VERSION ""

NS_ :

BS_:

BU_: ICC DVR PCL EAMP FLZCU_HCU_IC FLZCU_IC HCU_IC FLZCU_Signal_IC CGW TBOX BNCM CWC FRZCU

BO_ 1096 TMS_11: 32 CGW
 SG_ TMS_AirPurgeReminderSts : 17|2@0+ (1,0) [0|3] ""  ICC
 SG_ TMS_BT_Reduce_Wind_SpeedSts : 23|2@0+ (1,0) [0|3] "Bit"  ICC
 SG_ TMS_First_BlowingSts : 21|2@0+ (1,0) [0|3] "Bit"  ICC
 SG_ TMS_CirculationInTunnelsSts : 19|2@0+ (1,0) [0|3] "Bit"  ICC
 SG_ TMS_crosscountry_coolingSts : 29|2@0+ (1,0) [0|3] "Bit"  ICC
 SG_ TMS_ParkingAirConditioningStatus : 27|2@0+ (1,0) [0|3] "Bit"  ICC
 SG_ TMS_CoolantFillSts : 25|2@0+ (1,0) [0|3] "Bit"  ICC
 SG_ TMS_UVC_ControlSts : 39|2@0+ (1,0) [0|3] "Bit"  ICC
 SG_ TMS_AutoDefogActiveSts : 37|1@0+ (1,0) [0|1] ""  ICC
 SG_ TMS_UVC_LuminanceSts : 36|3@0+ (1,0) [0|7] "Bit"  ICC
 SG_ TMS_ICC_Lightoff_Sts : 33|2@0+ (1,0) [0|3] ""  ICC
 SG_ TMS_ICC_Memoff_Sts : 47|2@0+ (1,0) [0|3] ""  ICC
 SG_ TMS_keepwarmSet_TemperatureSts : 55|8@0+ (1,0) [0|254] "Bit"  ICC
 SG_ TMS_CFSCycleLevel : 71|3@0+ (1,0) [0|7] ""  ICC
 SG_ TMS_TimingLevel : 68|3@0+ (1,0) [0|7] ""  ICC
 SG_ TMS_BiochemicalFuncSts : 95|2@0+ (1,0) [0|3] ""  ICC
 SG_ TMS_TimedVentilationSts : 97|2@0+ (1,0) [0|3] ""  ICC

BO_ 1240 TDU_9: 32 CGW
 SG_ TMS_CFSSwitchFb : 17|2@0+ (1,0) [0|3] ""  ICC
 SG_ TDU_CFSPosOneType : 21|4@0+ (1,0) [0|15] ""  ICC
 SG_ TDU_CFSPosTwoType : 27|4@0+ (1,0) [0|15] ""  ICC
 SG_ TDU_CFSPosThreeType : 31|4@0+ (1,0) [0|15] ""  ICC
 SG_ TDU_CFSRunOut : 39|4@0+ (1,0) [0|15] ""  ICC
 SG_ TMS_CFSShortWarn : 43|4@0+ (1,0) [0|15] ""  ICC
 SG_ TMS_CFSLevelSetFb : 47|4@0+ (1,0) [0|15] ""  ICC
 SG_ TMS_CFSPosSetFb : 49|2@0+ (1,0) [0|3] ""  ICC
 SG_ TMS_CFSPosOneLife : 63|8@0+ (1,0) [0|100] "%"  ICC
 SG_ TMS_CFSPosTwoLife : 87|8@0+ (1,0) [0|100] "%"  ICC
 SG_ TMS_CFSPosThreeLife : 95|8@0+ (1,0) [0|100] "%"  ICC
 SG_ TMS_PM25SwitchFb : 97|2@0+ (1,0) [0|3] ""  ICC
 SG_ TMS_AQSCOSts_2 : 103|4@0+ (1,0) [0|15] ""  ICC
 SG_ TMS_AQSNO2Sts_2 : 107|4@0+ (1,0) [0|15] ""  ICC
 SG_ TMS_AQSN02SnsrSts_2 : 109|2@0+ (1,0) [0|3] ""  ICC
 SG_ TMS_AQSLifeCntr_2 : 111|2@0+ (1,0) [0|3] ""  ICC
 SG_ TMS_AQSErrSts_2 : 114|3@0+ (1,0) [0|7] ""  ICC
 SG_ TMS_AQSErrRespAQSM_2 : 115|1@0+ (1,0) [0|1] ""  ICC
 SG_ TMS_AQSAirQlySts_2 : 118|3@0+ (1,0) [0|7] ""  ICC
 SG_ TMS_ThrModeStsFb : 122|3@0+ (1,0) [0|6] ""  ICC
 SG_ TMS_ThrSetTempFb_C : 127|5@0+ (0.5,15.5) [15.5|30.5] "℃"  ICC
 SG_ TMS_ThrCLMSwitchFb : 145|2@0+ (1,0) [0|3] ""  ICC
 SG_ TMS_ThrAutoSwitchFb : 147|2@0+ (1,0) [0|3] ""  ICC
 SG_ TMS_ThrBlowSpeedLevelKeyStsFb : 151|4@0+ (1,0) [0|15] ""  ICC

BO_ 638 FRZCU_9: 16 CGW
 SG_ FRZCU_HoodSts : 45|2@0+ (1,0) [0|3] ""  ICC
 SG_ FRZCU_AuthenResult : 48|1@0+ (1,0) [0|1] ""  ICC
 SG_ FRZCU_PowerMode : 51|2@0+ (1,0) [0|3] ""  ICC
 SG_ FRZCU_TrunkSts : 53|2@0+ (1,0) [0|3] ""  ICC
 SG_ FRZCU_HandleSwitchStsFL : 57|2@0+ (1,0) [0|3] ""  ICC,PCL
 SG_ FRZCU_HandleSwitchStsFR : 59|2@0+ (1,0) [0|3] ""  ICC,PCL
 SG_ FRZCU_HandleSwitchStsRR : 61|2@0+ (1,0) [0|3] ""  ICC
 SG_ FRZCU_HandleSwitchStsRL : 63|2@0+ (1,0) [0|3] ""  ICC
 SG_ SeatLength_target_Passenger : 87|4@0+ (1,0) [0|15] ""  ICC
 SG_ SeatBackrest_target_Passenger : 95|5@0+ (1,0) [0|15] ""  ICC
 SG_ FRZCU_TrunkLockSts : 89|2@0+ (1,0) [0|3] ""  ICC
 SG_ FRZCU_HoodLockSts : 103|2@0+ (1,0) [0|3] ""  ICC
 SG_ FrontBackSpeedAdj_Cmd : 101|3@0+ (1,0) [0|7] ""  ICC
 SG_ FRZCU_GloveboxSW : 98|1@0+ (1,0) [0|1] ""  ICC
 SG_ FRZCU_FRReleaseLockSts : 111|3@0+ (1,0) [0|7] ""  ICC
 SG_ FRZCU_RRReleaseLockSts : 108|3@0+ (1,0) [0|7] ""  ICC
 SG_ FRZCU_PELockInKeyWarning : 105|1@0+ (1,0) [0|1] ""  ICC
 SG_ FRZCU_PowerOFFWarning : 118|1@0+ (1,0) [0|1] ""  ICC
 SG_ FRZCU_KeylessWarning : 116|1@0+ (1,0) [0|1] ""  ICC
 SG_ FRZCU_OTAPwrDwnReqFb : 113|2@0+ (1,0) [0|3] ""  ICC
 SG_ FRZCU_OTAPwrOnReqFb : 127|2@0+ (1,0) [0|3] ""  ICC

BO_ 949 PEPS_1: 16 CGW
 SG_ PEPS_InformationSource : 23|2@0+ (1,0) [0|3] ""  ICC,PCL
 SG_ PEPS_OrderInformation : 21|4@0+ (1,0) [0|15] ""  ICC,PCL
 SG_ PEPS_IDInformation : 31|4@0+ (1,0) [0|15] ""  ICC,PCL
 SG_ PEPS_KeySts : 27|3@0+ (1,0) [0|7] ""  ICC,PCL
 SG_ PEPS_ETRUnLockReq : 39|2@0+ (1,0) [0|3] ""  ICC,PCL

BO_ 1028 PEPS_2: 16 CGW
 SG_ PEPS_WelcomeON : 17|2@0+ (1,0) [0|3] ""  ICC,PCL
 SG_ PEPS_VehicleSearchReq : 19|2@0+ (1,0) [0|3] ""  ICC,PCL
 SG_ PEPS_SATOReminder : 21|2@0+ (1,0) [0|3] ""  ICC,PCL
 SG_ PEPS_PLGUnlockReq : 23|2@0+ (1,0) [0|3] ""  ICC,PCL
 SG_ PEPS_RKETrunkSts : 25|2@0+ (1,0) [0|3] ""  ICC,PCL
 SG_ PEPS_SSBInhibitCWCSts : 27|2@0+ (1,0) [0|3] ""  ICC,PCL
 SG_ PEPS_WirelessChargingCtrSts : 29|2@0+ (1,0) [0|3] ""  ICC,PCL
 SG_ PEPS_EmgyShutdown : 35|2@0+ (1,0) [0|3] ""  ICC,PCL
 SG_ PEPS_SSBInputFailure : 37|2@0+ (1,0) [0|3] ""  ICC,PCL
 SG_ PEPS_SmartSystemWarning1_1 : 39|2@0+ (1,0) [0|3] ""  ICC,PCL
 SG_ PEPS_SmartSystemWarning2_2 : 41|2@0+ (1,0) [0|3] ""  ICC,PCL
 SG_ PEPS_SmartSystemWarning3_1 : 43|2@0+ (1,0) [0|3] ""  ICC,PCL
 SG_ PEPS_SmartSystemWarning3_2 : 45|2@0+ (1,0) [0|3] ""  ICC,PCL
 SG_ PEPS_SmartSystemWarning4_2 : 47|2@0+ (1,0) [0|3] ""  ICC,PCL
 SG_ PEPS_SmartSystemWarning4_3 : 49|2@0+ (1,0) [0|3] ""  ICC,PCL
 SG_ PEPS_SystemWarning : 51|2@0+ (1,0) [0|3] ""  ICC,PCL
 SG_ PEPS_BLTKeyPESts : 53|2@0+ (1,0) [0|3] ""  ICC,PCL

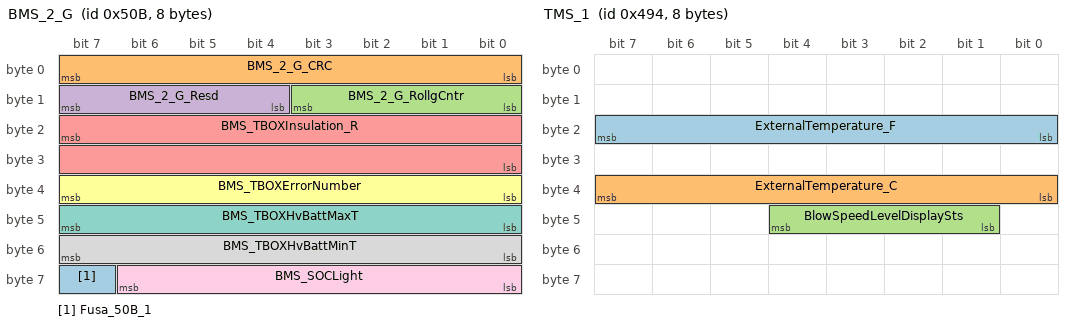
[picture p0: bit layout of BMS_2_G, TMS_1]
BO_ 1291 BMS_2_G: 8 CGW
 SG_ Fusa_50B_1 : 63|1@0+ (1,0) [0|1] ""  ICC
 SG_ BMS_2_G_CRC : 7|8@0+ (1,0) [0|255] ""  ICC
 SG_ BMS_2_G_RollgCntr : 11|4@0+ (1,0) [0|14] ""  ICC
 SG_ BMS_2_G_Resd : 15|4@0+ (1,0) [0|15] ""  ICC
 SG_ BMS_TBOXInsulation_R : 23|16@0+ (1,0) [0|60000] "kiloohm(kΩ)"  ICC
 SG_ BMS_TBOXErrorNumber : 39|8@0+ (1,0) [0|255] ""  ICC
 SG_ BMS_TBOXHvBattMaxT : 47|8@0+ (1,-40) [-40|210] "gradcelsius(°C)"  ICC
 SG_ BMS_TBOXHvBattMinT : 55|8@0+ (1,-40) [-40|210] "gradcelsius(°C)"  ICC
 SG_ BMS_SOCLight : 62|7@0+ (1,0) [0|100] "%"  ICC

BO_ 587 ONEBOX_4: 48 CGW
 SG_ ONEBOX_4_LHFWheelSpeedRPM : 23|16@0+ (0.0625,0) [0|4095.875] "rpm"  ICC
 SG_ ONEBOX_4_RHFWheelSpeedRPM : 39|16@0+ (0.0625,0) [0|4095.875] "rpm"  ICC
 SG_ LHRWheelSpeedRPM : 55|16@0+ (0.0625,0) [0|4095.875] "rpm"  ICC
 SG_ RHRWheelSpeedRPM : 87|16@0+ (0.0625,0) [0|4095.875] "rpm"  ICC
 SG_ LHRPulseCounterFailSts : 106|1@0+ (1,0) [0|1] ""  ICC
 SG_ LHRPulseCounter : 103|13@0+ (1,0) [0|8191] "pulse"  ICC
 SG_ RHRPulseCounterFailSts : 122|1@0+ (1,0) [0|1] ""  ICC
 SG_ RHRPulseCounter : 119|13@0+ (1,0) [0|8191] "pulse"  ICC
 SG_ RHFPulseCounterFailSts : 154|1@0+ (1,0) [0|1] ""  ICC
 SG_ RHFPulseCounter : 151|13@0+ (1,0) [0|8191] "pulse"  ICC
 SG_ LHFPulseCounterFailSts : 170|1@0+ (1,0) [0|1] ""  ICC
 SG_ LHFPulseCounter : 167|13@0+ (1,0) [0|8191] "pulse"  ICC
 SG_ LHFWheelDriveDirection : 187|3@0+ (1,0) [0|7] ""  ICC
 SG_ RHFWheelDriveDirection : 219|3@0+ (1,0) [0|7] ""  ICC
 SG_ LHRWheelDriveDirection : 235|3@0+ (1,0) [0|7] ""  ICC
 SG_ RHRWheelDriveDirection : 251|3@0+ (1,0) [0|7] ""  ICC

BO_ 1338 FMCU_1_G: 8 CGW
 SG_ FMCU_ErrLvlDis : 19|3@0+ (1,0) [0|7] ""  ICC
 SG_ FMCU_SpdAct_EDR : 39|16@0+ (1,-32767) [-32767|32766] "rpm"  ICC

BO_ 777 ISGF_2: 8 CGW
 SG_ ISGF_ErrLvl : 20|4@0+ (1,0) [0|6] ""  ICC

BO_ 1403 RMCU_1_G: 8 CGW
 SG_ RMCU_ErrLvlDis : 19|3@0+ (1,0) [0|7] ""  ICC
 SG_ RMCU_Speed_EDR : 39|16@0+ (1,-32767) [-32767|32766] "rpm"  ICC

BO_ 1299 BMS_1_G: 8 CGW
 SG_ BMS_PackVoltageDis : 23|16@0+ (0.1,0) [0|1000] "volt(V)"  ICC
 SG_ BMS_PackCurrentDis : 39|16@0+ (0.1,-2047) [-2047|2047] "ampere(A)"  ICC

BO_ 1099 ISGF_4: 8 CGW
 SG_ ISGF_SysTempOvrInd : 40|1@0+ (1,0) [0|1] ""  ICC

BO_ 1130 TCU_23: 64 CGW
 SG_ TCU_23_GBFaultstatus : 23|2@0+ (1,0) [0|3] ""  ICC
 SG_ TCU_23_TeachInState : 30|3@0+ (1,0) [0|7] ""  ICC
 SG_ TCU_23_GBWarmUpReq : 27|1@0+ (1,0) [0|1] ""  ICC
 SG_ TCU_23_CluSelfLrng : 39|1@0+ (1,0) [0|1] ""  ICC

BO_ 1180 ACU_1: 8 CGW
 SG_ New_Signal_49C_9 : 32|25@0+ (1,0) [0|1024] ""  ICC
 SG_ New_Signal_49C_8 : 37|4@0+ (1,0) [0|15] ""  ICC
 SG_ New_Signal_49C_7 : 27|1@0+ (1,0) [0|1] ""  ICC
 SG_ New_Signal_49C_6 : 29|1@0+ (1,0) [0|1] ""  ICC
 SG_ New_Signal_49C_5 : 31|1@0+ (1,0) [0|1] ""  ICC
 SG_ New_Signal_49C_4 : 19|2@0+ (1,0) [0|3] ""  ICC
 SG_ New_Signal_49C_3 : 21|1@0+ (1,0) [0|1] ""  ICC
 SG_ New_Signal_49C_2 : 23|1@0+ (1,0) [0|1] ""  ICC
 SG_ New_Signal_49C_1 : 15|4@0+ (1,0) [0|15] ""  ICC
 SG_ ACU_1_RollgCntr1 : 11|4@0+ (1,0) [0|15] ""  ICC
 SG_ ACU_1_CRC1 : 7|8@0+ (1,0) [0|255] ""  ICC
 SG_ ABM_1_Rollover_Status : 33|1@0+ (1,0) [0|1] ""  ICC
 SG_ ACU_1_AirBagFailSts : 17|2@0+ (1,0) [0|3] ""  ICC
 SG_ ACU_1_ThdRowLBeltWarning : 20|1@0+ (1,0) [0|1] ""  ICC
 SG_ ACU_1_ThdRowRBeltWarning : 22|1@0+ (1,0) [0|1] ""  ICC
 SG_ ACU_1_PsngrSeatBeltWarning : 25|2@0+ (1,0) [0|3] ""  ICC
 SG_ ACU_1_SecRowLBeltWarning : 26|1@0+ (1,0) [0|1] ""  ICC
 SG_ ACU_1_SecRowMBeltWarning : 28|1@0+ (1,0) [0|1] ""  ICC
 SG_ ACU_1_SecRowRBeltWarning : 30|1@0+ (1,0) [0|1] ""  ICC
 SG_ ACU_1_PsngrSeatOccupiedSts : 39|2@0+ (1,0) [0|3] ""  ICC

BO_ 1248 FRZCU_TO_FLZCU: 48 CGW

BO_ 1341 BMS_44: 48 CGW
 SG_ BMS_44_PackPowerRealTime : 23|15@0+ (0.1,-1024) [-1024|1024] "kW"  ICC

BO_ 811 BMS_6: 16 CGW
 SG_ BMS_Chg_Sts : 87|4@0+ (1,0) [0|15] ""  ICC

BO_ 1427 ILCF_1: 8 CGW
 SG_ ILCF_1_LogoParkingSts : 17|2@0+ (1,0) [0|3] ""  ICC

BO_ 1172 TMS_1: 8 CGW
 SG_ ExternalTemperature_F : 23|8@0+ (1,-67) [-67|158] "°F"  ICC
 SG_ ExternalTemperature_C : 39|8@0+ (0.5,-40) [-40|85] "°C"  ICC
 SG_ BlowSpeedLevelDisplaySts : 44|4@0+ (1,0) [0|15] ""  ICC,EAMP

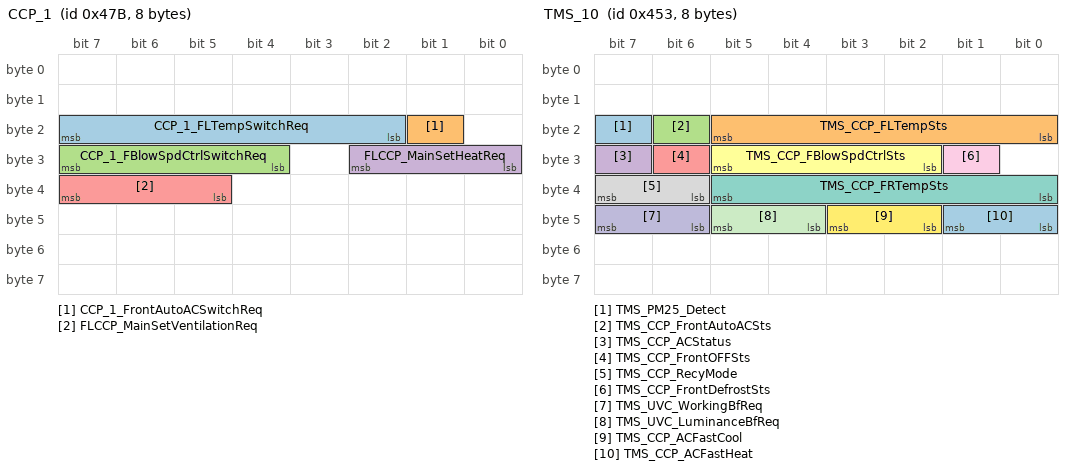
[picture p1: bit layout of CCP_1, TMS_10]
BO_ 1147 CCP_1: 8 CGW
 SG_ CCP_1_FLTempSwitchReq : 23|6@0+ (0.5,15.5) [15.5|30.5] "℃"  ICC
 SG_ CCP_1_FrontAutoACSwitchReq : 17|1@0+ (1,0) [0|1] ""  ICC
 SG_ CCP_1_FBlowSpdCtrlSwitchReq : 31|4@0+ (1,0) [0|15] ""  ICC
 SG_ FLCCP_MainSetHeatReq : 26|3@0+ (1,0) [0|7] ""  ICC
 SG_ FLCCP_MainSetVentilationReq : 39|3@0+ (1,0) [0|7] ""  ICC

BO_ 1107 TMS_10: 8 CGW
 SG_ TMS_PM25_Detect : 23|1@0+ (1,0) [0|1] ""  ICC
 SG_ TMS_CCP_FLTempSts : 21|6@0+ (0.5,15.5) [15.5|30.5] "℃"  ICC
 SG_ TMS_CCP_FrontAutoACSts : 22|1@0+ (1,0) [0|1] ""  ICC
 SG_ TMS_CCP_ACStatus : 31|1@0+ (1,0) [0|1] ""  ICC
 SG_ TMS_CCP_FrontOFFSts : 30|1@0+ (1,0) [0|1] ""  ICC
 SG_ TMS_CCP_FBlowSpdCtrlSts : 29|4@0+ (1,0) [0|15] ""  ICC
 SG_ TMS_CCP_FRTempSts : 37|6@0+ (0.5,15.5) [15.5|30.5] "℃"  ICC
 SG_ TMS_CCP_RecyMode : 39|2@0+ (1,0) [0|3] ""  ICC
 SG_ TMS_CCP_FrontDefrostSts : 25|1@0+ (1,0) [0|1] ""  ICC
 SG_ TMS_UVC_WorkingBfReq : 47|2@0+ (1,0) [0|3] ""  ICC
 SG_ TMS_UVC_LuminanceBfReq : 45|2@0+ (1,0) [0|3] ""  ICC
 SG_ TMS_CCP_ACFastCool : 43|2@0+ (1,0) [0|3] ""  ICC
 SG_ TMS_CCP_ACFastHeat : 41|2@0+ (1,0) [0|3] ""  ICC

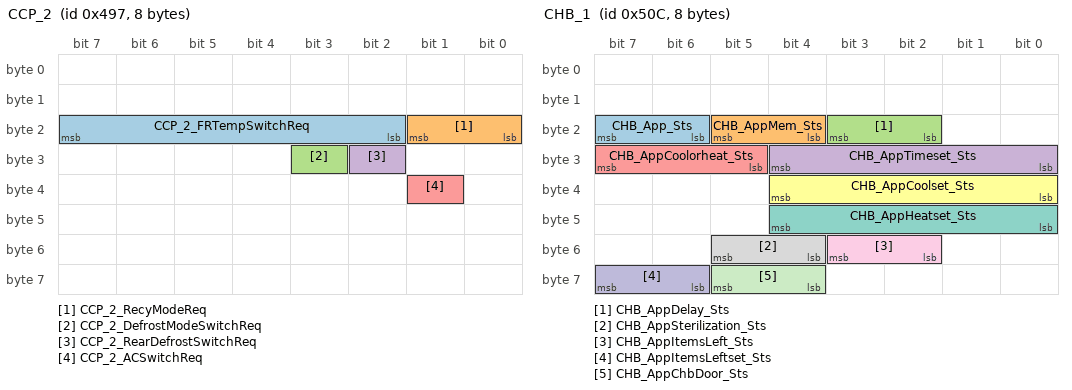
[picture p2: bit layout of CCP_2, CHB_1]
BO_ 1175 CCP_2: 8 CGW
 SG_ CCP_2_FRTempSwitchReq : 23|6@0+ (0.5,15.5) [15.5|30.5] "℃"  ICC
 SG_ CCP_2_RecyModeReq : 17|2@0+ (1,0) [0|3] ""  ICC
 SG_ CCP_2_DefrostModeSwitchReq : 27|1@0+ (1,0) [0|1] ""  ICC
 SG_ CCP_2_RearDefrostSwitchReq : 26|1@0+ (1,0) [0|1] ""  ICC
 SG_ CCP_2_ACSwitchReq : 33|1@0+ (1,0) [0|1] ""  ICC

BO_ 1292 CHB_1: 8 CGW
 SG_ CHB_App_Sts : 23|2@0+ (1,0) [0|3] ""  ICC
 SG_ CHB_AppMem_Sts : 21|2@0+ (1,0) [0|3] ""  ICC
 SG_ CHB_AppDelay_Sts : 19|2@0+ (1,0) [0|3] ""  ICC
 SG_ CHB_AppTimeset_Sts : 28|5@0+ (1,0) [0|31] "h"  ICC
 SG_ CHB_AppCoolorheat_Sts : 31|3@0+ (1,0) [0|7] ""  ICC
 SG_ CHB_AppCoolset_Sts : 36|5@0+ (1,0) [0|31] ""  ICC
 SG_ CHB_AppHeatset_Sts : 44|5@0+ (1,0) [0|31] ""  ICC
 SG_ CHB_AppSterilization_Sts : 53|2@0+ (1,0) [0|3] ""  ICC
 SG_ CHB_AppItemsLeft_Sts : 51|2@0+ (1,0) [0|3] ""  ICC
 SG_ CHB_AppItemsLeftset_Sts : 63|2@0+ (1,0) [0|3] ""  ICC
 SG_ CHB_AppChbDoor_Sts : 61|2@0+ (1,0) [0|3] ""  ICC

BO_ 1241 EMS_4_G: 8 CGW
 SG_ FuelTankLidSystemFailureSts : 43|1@0+ (1,0) [0|1] ""  ICC
 SG_ FuelTankPressureConditionReached : 45|2@0+ (1,0) [0|3] ""  ICC

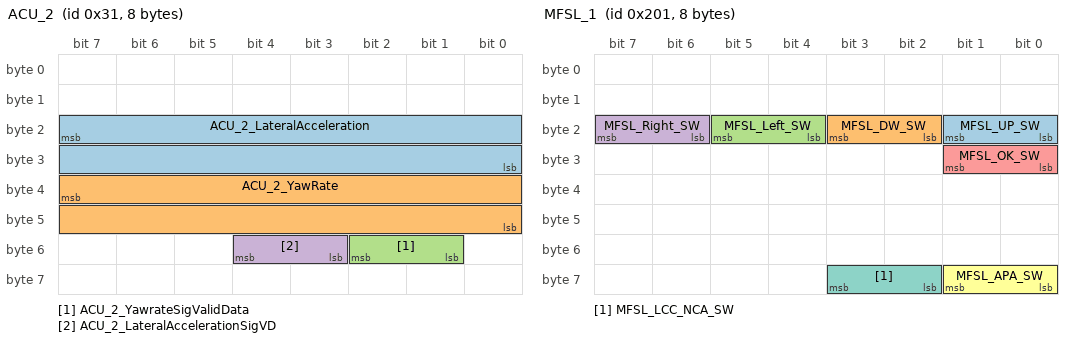
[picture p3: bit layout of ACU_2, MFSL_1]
BO_ 49 ACU_2: 8 CGW
 SG_ ACU_2_LateralAcceleration : 23|16@0+ (0.001,-2) [-2|2] "g"  ICC
 SG_ ACU_2_YawRate : 39|16@0+ (0.01,-180) [-180|180] "deg/sec"  ICC
 SG_ ACU_2_YawrateSigValidData : 50|2@0+ (1,0) [0|3] ""  ICC
 SG_ ACU_2_LateralAccelerationSigVD : 52|2@0+ (1,0) [0|3] ""  ICC

BO_ 1024 FRZCU_13: 64 CGW
 SG_ FRZCU_ADSLightSts : 49|2@0+ (1,0) [0|3] ""  ICC
 SG_ CSunshadeSts : 23|3@0+ (1,0) [0|7] ""  ICC
 SG_ CSunshadePercentSts : 20|4@0+ (1,0) [0|15] ""  ICC
 SG_ FRZCU_SeatHeatLvlFR2 : 31|4@0+ (1,0) [0|15] ""  ICC
 SG_ FRZCU_SeatVentLvlFR2 : 27|4@0+ (1,0) [0|15] ""  ICC
 SG_ FRZCU_SeatVentLvlRR2 : 39|4@0+ (1,0) [0|15] ""  ICC
 SG_ FRZCU_SeatHeatLvlRR2 : 35|4@0+ (1,0) [0|15] ""  ICC
 SG_ FRZCU_ContainerlightSts : 47|2@0+ (1,0) [0|3] ""  ICC
 SG_ FRZCU_FRWinThermalSts : 45|1@0+ (1,0) [0|1] ""  ICC
 SG_ FRZCU_RRWinThermalSts : 44|1@0+ (1,0) [0|1] ""  ICC
 SG_ FRZCU_CSunshadeThermalSts : 43|1@0+ (1,0) [0|1] ""  ICC

BO_ 1182 CDU_OBC_3: 48 CGW
 SG_ OBC_InnerDischgVolt : 348|13@0+ (0.1,0) [0|800] ""  ICC
 SG_ OBC_InnerDischgCurr : 343|10@0+ (0.1,0) [0|100] ""  ICC
 SG_ OBC_ElectronicLockSts : 242|3@0+ (1,0) [0|4] ""  ICC
 SG_ OBC_WorkingMode : 251|4@0+ (1,0) [0|15] ""  ICC
 SG_ OBC_OutDischgCurr : 367|10@0+ (0.1,0) [0|100] "A"  ICC
 SG_ OBC_OutDischgVolt : 372|13@0+ (0.1,0) [0|800] "V"  ICC

BO_ 513 MFSL_1: 8 CGW
 SG_ MFSL_UP_SW : 17|2@0+ (1,0) [0|3] ""  ICC
 SG_ MFSL_DW_SW : 19|2@0+ (1,0) [0|3] ""  ICC
 SG_ MFSL_Left_SW : 21|2@0+ (1,0) [0|3] ""  ICC
 SG_ MFSL_Right_SW : 23|2@0+ (1,0) [0|3] ""  ICC
 SG_ MFSL_OK_SW : 25|2@0+ (1,0) [0|3] ""  ICC
 SG_ MFSL_APA_SW : 57|2@0+ (1,0) [0|3] ""  ICC
 SG_ MFSL_LCC_NCA_SW : 59|2@0+ (1,0) [0|3] ""  ICC

BO_ 1152 TBOX_8: 16 CGW
 SG_ TBOX_PetmodeSetTemperature : 118|5@0+ (0.5,15.5) [15.5|30.5] "℃"  ICC

BO_ 1164 CDU_5: 64 CGW
 SG_ OBC_DischgSts : 123|3@0+ (1,0) [0|3] ""  ICC

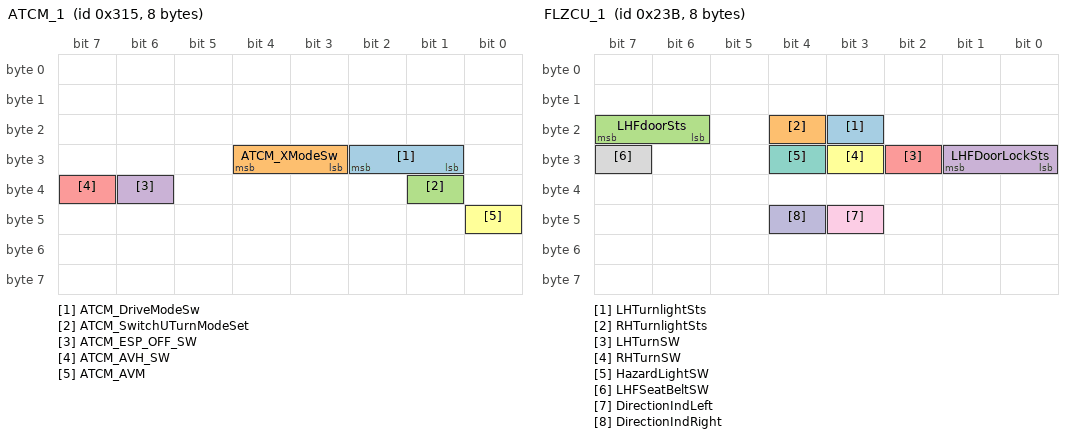
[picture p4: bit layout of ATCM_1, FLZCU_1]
BO_ 789 ATCM_1: 8 CGW
 SG_ ATCM_DriveModeSw : 26|2@0+ (1,0) [0|3] ""  ICC
 SG_ ATCM_XModeSw : 28|2@0+ (1,0) [0|3] ""  ICC
 SG_ ATCM_SwitchUTurnModeSet : 33|1@0+ (1,0) [0|1] ""  ICC
 SG_ ATCM_ESP_OFF_SW : 38|1@0+ (1,0) [0|1] ""  ICC
 SG_ ATCM_AVH_SW : 39|1@0+ (1,0) [0|1] ""  ICC
 SG_ ATCM_AVM : 40|1@0+ (1,0) [0|1] ""  ICC

BO_ 1214 BNCM_16: 32 CGW
 SG_ BNCM_16_CRC1 : 7|8@0+ (1,0) [0|255] ""  ICC
 SG_ BNCM_16_RollgCntr1 : 11|4@0+ (1,0) [0|14] ""  ICC
 SG_ BNCM_16_Resd1 : 15|4@0+ (1,0) [0|15] ""  ICC
 SG_ BNCM_16_CMD : 23|16@0+ (1,0) [0|65535] ""  ICC
 SG_ BNCM_16_PDU1 : 39|64@0+ (1,0) [0|1.84467440737096E+019] ""  ICC
 SG_ BNCM_16_PDU2 : 103|64@0+ (1,0) [0|1.84467440737096E+019] ""  ICC
 SG_ BNCM_16_PDU3 : 167|64@0+ (1,0) [0|1.84467440737096E+019] ""  ICC
 SG_ BNCM_16_PDU4 : 231|32@0+ (1,0) [0|4294967295] ""  ICC

BO_ 571 FLZCU_1: 8 FLZCU_HCU_IC
 SG_ LHTurnlightSts : 19|1@0+ (1,0) [0|1] ""  ICC,DVR
 SG_ RHTurnlightSts : 20|1@0+ (1,0) [0|1] ""  ICC,DVR
 SG_ LHFdoorSts : 23|2@0+ (1,0) [0|3] ""  ICC,PCL
 SG_ LHFDoorLockSts : 25|2@0+ (1,0) [0|3] ""  ICC,PCL
 SG_ LHTurnSW : 26|1@0+ (1,0) [0|1] ""  ICC
 SG_ RHTurnSW : 27|1@0+ (1,0) [0|1] ""  ICC
 SG_ HazardLightSW : 28|1@0+ (1,0) [0|1] ""  ICC
 SG_ LHFSeatBeltSW : 31|1@0+ (1,0) [0|1] ""  ICC
 SG_ DirectionIndLeft : 43|1@0+ (1,0) [0|1] ""  ICC
 SG_ DirectionIndRight : 44|1@0+ (1,0) [0|1] ""  ICC

BO_ 699 RZCU_2: 8 FLZCU_HCU_IC
 SG_ LHRdoorSts : 21|2@0+ (1,0) [0|3] ""  ICC,PCL

BO_ 787 FRZCU_14: 16 CGW
 SG_ ChrgHoodSts : 23|1@0+ (1,0) [0|1] ""  ICC
 SG_ FRZCU_FRSitPosnSts : 22|2@0+ (1,0) [0|3] ""  ICC

BO_ 572 ONEBOX_7: 48 CGW
 SG_ ONEBOX_7_TAB_HighTemp : 49|1@0+ (1,0) [0|1] ""  ICC
 SG_ ONEBOX_7_TAB_Active : 51|2@0+ (1,0) [0|3] ""  ICC
 SG_ ONEBOX_7_BSW_Active : 60|2@0+ (1,0) [0|3] ""  ICC
 SG_ ONEBOX_7_iCCO_TgtVel : 151|8@0+ (0.1,0) [0|20] ""  ICC

BO_ 1212 VCU_3_G: 8 FLZCU_HCU_IC
 SG_ VCU_3_G_ActWheelTorqueFA : 23|16@0+ (1,-32768) [-32768|32767] "NM"  ICC
 SG_ VCU_3_G_ActWheelTorqueRA : 39|16@0+ (1,-32768) [-32768|32767] "NM"  ICC

BO_ 1110 IMMO_ICC_11: 8 CGW
 SG_ IMMO_Chall_ICC : 7|64@0+ (1,0) [0|1.84467440737096E+019] ""  ICC

BO_ 1149 IMMO_VCC_12: 8 CGW
 SG_ IMMO_Teach_VCC : 7|64@0+ (1,0) [0|1.84467440737096E+019] ""  ICC

BO_ 1120 FLZCU_3: 8 FLZCU_HCU_IC
 SG_ RLHS_2_AmbBrightness : 19|12@0+ (20,0) [0|81880] "Lux"  ICC
 SG_ RLHS_LiSwithReason : 49|2@0+ (1,0) [0|3] ""  ICC

BO_ 1199 TCM_1: 8 CGW
 SG_ TCM_1_TrailerSts : 16|1@0+ (1,0) [0|1] ""  ICC

BO_ 770 ADS_HW_302h: 64 CGW
 SG_ ADS_VdcActvSts_302h : 249|1@0+ (1,0) [0|1] ""  ICC
 SG_ ADS_TcsActvSts_302h : 248|1@0+ (1,0) [0|1] ""  ICC
 SG_ ADS_CRC1_302h : 7|8@0+ (1,0) [0|255] ""  ICC
 SG_ ADS_RollgCntr1_302h : 11|4@0+ (1,0) [0|14] ""  ICC
 SG_ ADS_Resd1_302h : 15|4@0+ (1,0) [0|15] ""  ICC
 SG_ ADS_RPAOnlineOrNot_302h : 23|8@0+ (1,0) [0|255] ""  ICC
 SG_ ADS_RpaParkAuthn_302h : 31|2@0+ (1,0) [0|3] ""  ICC
 SG_ ADS_SeldParkID_302h : 29|4@0+ (1,0) [0|10] ""  ICC
 SG_ ADS_VehParkMod_302h : 25|3@0+ (1,0) [0|2] ""  ICC
 SG_ ADS_RemParkPatSel_302h : 38|2@0+ (1,0) [0|3] ""  ICC
 SG_ ADS_ParkDirCfm_302h : 36|4@0+ (1,0) [0|8] ""  ICC
 SG_ ADS_ParkProgs_302h : 32|7@0+ (1,0) [0|100] ""  ICC
 SG_ ADS_ParkRmngDst_302h : 41|9@0+ (0.1,0) [0|50] ""  ICC
 SG_ ADS_ObstclDst_302h : 48|5@0+ (1,0) [0|31] ""  ICC
 SG_ ADS_AutEve_302h : 59|4@0+ (1,0) [0|15] ""  ICC
 SG_ ADS_CRC2_302h : 71|8@0+ (1,0) [0|255] ""  ICC
 SG_ ADS_RollgCntr2_302h : 75|4@0+ (1,0) [0|14] ""  ICC
 SG_ ADS_Resd2_302h : 79|4@0+ (1,0) [0|15] ""  ICC
 SG_ ADS_parkInterruptDuration_302h : 87|8@0+ (1,0) [0|255] ""  ICC
 SG_ APA_ResuAvl_302h : 95|2@0+ (1,0) [0|3] ""  ICC
 SG_ ADS_ParkStMac_302h : 93|5@0+ (1,0) [0|31] ""  ICC
 SG_ ADS_ParkOutDir_ParaLe_302h : 88|1@0+ (1,0) [0|1] ""  ICC
 SG_ ADS_ParkOutDir_ParaRi_302h : 103|1@0+ (1,0) [0|1] ""  ICC
 SG_ ADS_ParkOutDir_PerpFwd_302h : 102|1@0+ (1,0) [0|1] ""  ICC
 SG_ ADS_ParkOutDir_PerpLeFwd_302h : 101|1@0+ (1,0) [0|1] ""  ICC
 SG_ ADS_ParkOutDir_PerpRiFwd_302h : 100|1@0+ (1,0) [0|1] ""  ICC
 SG_ ADS_ParkOutDir_PerpLeBack_302h : 99|1@0+ (1,0) [0|1] ""  ICC
 SG_ ADS_ParkOutDir_PerpRiBack_302h : 98|1@0+ (1,0) [0|1] ""  ICC
 SG_ ADS_ParkOutDir_PerpBack_302h : 97|1@0+ (1,0) [0|1] ""  ICC
 SG_ APA_RPAFctUnavlMsg_1_302h : 96|1@0+ (1,0) [0|1] ""  ICC
 SG_ APA_RPAFctUnavlMsg_2_302h : 111|1@0+ (1,0) [0|1] ""  ICC
 SG_ APA_RPAFctUnavlMsg_3_302h : 110|1@0+ (1,0) [0|1] ""  ICC
 SG_ APA_RPAFctUnavlMsg_4_302h : 109|1@0+ (1,0) [0|1] ""  ICC
 SG_ APA_RPAFctUnavlMsg_5_302h : 108|1@0+ (1,0) [0|1] ""  ICC
 SG_ APA_RPAFctUnavlMsg_6_302h : 107|1@0+ (1,0) [0|1] ""  ICC
 SG_ APA_RPAFctUnavlMsg_7_302h : 106|1@0+ (1,0) [0|1] ""  ICC
 SG_ APA_RPAFctUnavlMsg_8_302h : 105|1@0+ (1,0) [0|1] ""  ICC
 SG_ APA_RPAFctUnavlMsg_9_302h : 104|1@0+ (1,0) [0|1] ""  ICC
 SG_ APA_RPAFctUnavlMsg_10_302h : 119|1@0+ (1,0) [0|1] ""  ICC
 SG_ APA_RPAFctUnavlMsg_11_302h : 118|1@0+ (1,0) [0|1] ""  ICC
 SG_ APA_RPAFctUnavlMsg_12_302h : 117|1@0+ (1,0) [0|1] ""  ICC
 SG_ APA_RPAFctUnavlMsg_13_302h : 116|1@0+ (1,0) [0|1] ""  ICC
 SG_ APA_RPAFctUnavlMsg_14_302h : 115|1@0+ (1,0) [0|1] ""  ICC
 SG_ APA_RPAFctUnavlMsg_15_302h : 114|1@0+ (1,0) [0|1] ""  ICC
 SG_ APA_RPAFctUnavlMsg_16_302h : 113|1@0+ (1,0) [0|1] ""  ICC
 SG_ APA_RPAFctUnavlMsg_17_302h : 112|1@0+ (1,0) [0|1] ""  ICC
 SG_ APA_RPAFctUnavlMsg_18_302h : 127|1@0+ (1,0) [0|1] ""  ICC
 SG_ APA_RPAFctUnavlMsg_19_302h : 126|1@0+ (1,0) [0|1] ""  ICC
 SG_ APA_RPAFctUnavlMsg_20_302h : 125|1@0+ (1,0) [0|1] ""  ICC
 SG_ APA_RPAFctUnavlMsg_21_302h : 124|1@0+ (1,0) [0|1] ""  ICC
 SG_ APA_RPAFctUnavlMsg_22_302h : 123|1@0+ (1,0) [0|1] ""  ICC
 SG_ APA_RPAFctUnavlMsg_23_302h : 122|1@0+ (1,0) [0|1] ""  ICC
 SG_ APA_RPAFctUnavlMsg_24_302h : 121|1@0+ (1,0) [0|1] ""  ICC
 SG_ APA_RPAFctUnavlMsg_25_302h : 120|1@0+ (1,0) [0|1] ""  ICC
 SG_ ADS_CRC3_302h : 135|8@0+ (1,0) [0|255] ""  ICC
 SG_ ADS_RollgCntr3_302h : 139|4@0+ (1,0) [0|14] ""  ICC
 SG_ ADS_Resd3_302h : 143|4@0+ (1,0) [0|15] ""  ICC
 SG_ APA_RPACnclMsg_1_302h : 151|1@0+ (1,0) [0|1] ""  ICC
 SG_ APA_RPACnclMsg_2_302h : 150|1@0+ (1,0) [0|1] ""  ICC
 SG_ APA_RPACnclMsg_3 : 149|1@0+ (1,0) [0|1] ""  ICC
 SG_ APA_RPACnclMsg_4_302h : 148|1@0+ (1,0) [0|1] ""  ICC
 SG_ APA_RPACnclMsg_5_302h : 147|1@0+ (1,0) [0|1] ""  ICC
 SG_ APA_RPACnclMsg_6_302h : 146|1@0+ (1,0) [0|1] ""  ICC
 SG_ APA_RPACnclMsg_7_302h : 145|1@0+ (1,0) [0|1] ""  ICC
 SG_ APA_RPACnclMsg_8_302h : 144|1@0+ (1,0) [0|1] ""  ICC
 SG_ APA_RPACnclMsg_9_302h : 159|1@0+ (1,0) [0|1] ""  ICC
 SG_ APA_RPACnclMsg_10_302h : 158|1@0+ (1,0) [0|1] ""  ICC
 SG_ APA_RPACnclMsg_11_302h : 157|1@0+ (1,0) [0|1] ""  ICC
 SG_ APA_RPACnclMsg_12_302h : 156|1@0+ (1,0) [0|1] ""  ICC
 SG_ APA_RPACnclMsg_13_302h : 155|1@0+ (1,0) [0|1] ""  ICC
 SG_ APA_RPACnclMsg_14_302h : 154|1@0+ (1,0) [0|1] ""  ICC
 SG_ APA_RPACnclMsg_15_302h : 153|1@0+ (1,0) [0|1] ""  ICC
 SG_ APA_RPACnclMsg_16_302h : 152|1@0+ (1,0) [0|1] ""  ICC
 SG_ APA_RPACnclMsg_17_302h : 167|1@0+ (1,0) [0|1] ""  ICC
 SG_ APA_RPACnclMsg_18_302h : 166|1@0+ (1,0) [0|1] ""  ICC
 SG_ APA_RPACnclMsg_19_302h : 165|1@0+ (1,0) [0|1] ""  ICC
 SG_ APA_RPACnclMsg_20_302h : 164|1@0+ (1,0) [0|1] ""  ICC
 SG_ APA_RPAPauseMsg_1_302h : 163|1@0+ (1,0) [0|1] ""  ICC
 SG_ APA_RPAPauseMsg_2_302h : 162|1@0+ (1,0) [0|1] ""  ICC
 SG_ APA_RPAPauseMsg_3_302h : 161|1@0+ (1,0) [0|1] ""  ICC
 SG_ APA_RPAPauseMsg_4_302h : 160|1@0+ (1,0) [0|1] ""  ICC
 SG_ APA_RPAPauseMsg_5_302h : 175|1@0+ (1,0) [0|1] ""  ICC
 SG_ APA_RPAPauseMsg_6_302h : 174|1@0+ (1,0) [0|1] ""  ICC
 SG_ APA_RPAPauseMsg_7_302h : 173|1@0+ (1,0) [0|1] ""  ICC
 SG_ APA_RPAPauseMsg_8_302h : 172|1@0+ (1,0) [0|1] ""  ICC
 SG_ APA_RPAPauseMsg_9_302h : 171|1@0+ (1,0) [0|1] ""  ICC
 SG_ APA_RPAPauseMsg_10_302h : 170|1@0+ (1,0) [0|1] ""  ICC
 SG_ ADS_ParkPosn1_ID_302h : 169|4@0+ (1,0) [0|15] ""  ICC
 SG_ ADS_MnvrOrintChng1_302h : 181|2@0+ (1,0) [0|3] ""  ICC
 SG_ ADS_MnvrOrintChng2_302h : 179|2@0+ (1,0) [0|3] ""  ICC
 SG_ ADS_ParkRelPos1_x1_302h : 177|10@0+ (0.1,-50) [-50|50] ""  ICC
 SG_ ADS_CRC4_302h : 199|8@0+ (1,0) [0|255] ""  ICC
 SG_ ADS_RollgCntr4_302h : 203|4@0+ (1,0) [0|14] ""  ICC
 SG_ ADS_Resd4_302h : 207|4@0+ (1,0) [0|15] ""  ICC
 SG_ ADS_ParkRelPos1_y1_302h : 215|10@0+ (0.1,-50) [-50|50] ""  ICC
 SG_ ADS_ParkRelPos1_x2_302h : 221|10@0+ (0.1,-50) [-50|50] ""  ICC
 SG_ ADS_ParkRelPos1_y2_302h : 227|10@0+ (0.1,-50) [-50|50] ""  ICC
 SG_ ADS_ParkRelPos1_x3_302h : 233|10@0+ (0.1,-50) [-50|50] ""  ICC
 SG_ ADS_TarParkSt_Posn1_302h : 255|3@0+ (1,0) [0|7] ""  ICC
 SG_ ADS_ParkChkSrc_Posn1_302h : 252|3@0+ (1,0) [0|3] ""  ICC
 SG_ ADS_CRC5_302h : 263|8@0+ (1,0) [0|255] ""  ICC
 SG_ ADS_RollgCntr5_302h : 267|4@0+ (1,0) [0|14] ""  ICC
 SG_ ADS_Resd5_302h : 271|4@0+ (1,0) [0|15] ""  ICC
 SG_ ADS_ParkRelPos1_y3_302h : 279|10@0+ (0.1,-50) [-50|50] ""  ICC
 SG_ ADS_ParkRelPos1_x4_302h : 285|10@0+ (0.1,-50) [-50|50] ""  ICC
 SG_ ADS_ParkRelPos1_y4_302h : 291|10@0+ (0.1,-50) [-50|50] ""  ICC
 SG_ ADS_ParkPosn2_ID_302h : 297|4@0+ (1,0) [0|15] ""  ICC
 SG_ ADS_ParkRelPos2_x1_302h : 309|10@0+ (0.1,-50) [-50|50] ""  ICC
 SG_ ADS_CRC6_302h : 327|8@0+ (1,0) [0|255] ""  ICC
 SG_ ADS_RollgCntr6_302h : 331|4@0+ (1,0) [0|14] ""  ICC
 SG_ ADS_Resd6_302h : 335|4@0+ (1,0) [0|15] ""  ICC
 SG_ ADS_ParkRelPos2_y1_302h : 343|10@0+ (0.1,-50) [-50|50] ""  ICC
 SG_ ADS_ParkRelPos2_x2_302h : 349|10@0+ (0.1,-50) [-50|50] ""  ICC
 SG_ ADS_ParkRelPos2_y2_302h : 355|10@0+ (0.1,-50) [-50|50] ""  ICC
 SG_ ADS_ParkRelPos2_x3_302h : 361|10@0+ (0.1,-50) [-50|50] ""  ICC
 SG_ ADS_TarParkSt_Posn2_302h : 383|3@0+ (1,0) [0|7] ""  ICC
 SG_ ADS_ParkChkSrc_Posn2_302h : 380|3@0+ (1,0) [0|3] ""  ICC
 SG_ ADS_CRC7_302h : 391|8@0+ (1,0) [0|255] ""  ICC
 SG_ ADS_RollgCntr7_302h : 395|4@0+ (1,0) [0|14] ""  ICC
 SG_ ADS_Resd7_302h : 399|4@0+ (1,0) [0|15] ""  ICC
 SG_ ADS_ParkRelPos2_y3_302h : 407|10@0+ (0.1,-50) [-50|50] ""  ICC
 SG_ ADS_ParkRelPos2_x4_302h : 413|10@0+ (0.1,-50) [-50|50] ""  ICC
 SG_ ADS_ParkRelPos2_y4_302h : 419|10@0+ (0.1,-50) [-50|50] ""  ICC

BO_ 514 ADS_HW_202h: 16 CGW
 SG_ Fusa_202_1 : 111|24@0+ (1,0) [0|65535] ""  ICC
 SG_ ADS_CRC1_202h : 7|8@0+ (1,0) [0|255] ""  ICC
 SG_ ADS_RollgCntr1_202h : 11|4@0+ (1,0) [0|14] ""  ICC
 SG_ ADS_Resd1_202h : 15|4@0+ (1,0) [0|15] ""  ICC
 SG_ ADS_AdsFault_202h : 23|3@0+ (1,0) [0|7] ""  ICC
 SG_ ADS_NicaReminderLEDVisual_202h : 20|3@0+ (1,0) [0|7] ""  ICC
 SG_ ADS_NicaReminderAcoustic_202h : 17|3@0+ (1,0) [0|7] ""  ICC
 SG_ ADS_TakeoverID_202h : 30|16@0+ (1,0) [0|65535] ""  ICC
 SG_ ADS_TakeoverLevel_202h : 46|3@0+ (1,0) [0|7] ""  ICC
 SG_ ADS_TakeoverType_202h : 43|4@0+ (1,0) [0|15] ""  ICC
 SG_ ADS_TORIDCorrespErrorID_202h : 55|16@0+ (1,0) [0|65535] ""  ICC
 SG_ ADS_CRC2_202h : 71|8@0+ (1,0) [0|255] ""  ICC
 SG_ ADS_RollgCntr2_202h : 75|4@0+ (1,0) [0|14] ""  ICC
 SG_ ADS_Resd2_202h : 79|4@0+ (1,0) [0|15] ""  ICC
 SG_ ADS_TakeoverExtended16bit_202h : 87|16@0+ (1,0) [0|65535] ""  ICC
 SG_ ADS_TakeoverExtended8bit_202h : 103|8@0+ (1,0) [0|255] ""  ICC

BO_ 1041 ADS_HW_411h: 48 CGW
 SG_ ADS_CRC1_411h : 7|8@0+ (1,0) [0|255] ""  ICC
 SG_ ADS_RollgCntr1_411h : 11|4@0+ (1,0) [0|14] ""  ICC
 SG_ ADS_Resd1_411h : 15|4@0+ (1,0) [0|15] ""  ICC
 SG_ ADS_RadarWarning0Distance_411h : 23|8@0+ (1,0) [0|255] "cm"  ICC
 SG_ ADS_RadarWarning1Distance_411h : 31|8@0+ (1,0) [0|255] "cm"  ICC
 SG_ ADS_RadarWarning2Distance_411h : 39|8@0+ (1,0) [0|255] "cm"  ICC
 SG_ ADS_RadarWarning3Distance_411h : 47|8@0+ (1,0) [0|255] "cm"  ICC
 SG_ ADS_RadarWarning4Distance_411h : 55|8@0+ (1,0) [0|255] "cm"  ICC
 SG_ ADS_RadarWarning5Distance_411h : 63|8@0+ (1,0) [0|255] "cm"  ICC
 SG_ ADS_CRC2_411h : 71|8@0+ (1,0) [0|255] ""  ICC
 SG_ ADS_RollgCntr2_411h : 75|4@0+ (1,0) [0|14] ""  ICC
 SG_ ADS_Resd2_411h : 79|4@0+ (1,0) [0|15] ""  ICC
 SG_ ADS_RadarWarning6Distance_411h : 87|8@0+ (1,0) [0|255] "cm"  ICC
 SG_ ADS_RadarWarning7Distance_411h : 95|8@0+ (1,0) [0|255] "cm"  ICC
 SG_ ADS_RadarWarning8Distance_411h : 103|8@0+ (1,0) [0|255] "cm"  ICC
 SG_ ADS_RadarWarning9Distance_411h : 111|8@0+ (1,0) [0|255] "cm"  ICC
 SG_ ADS_RadarWarning10Distance_411h : 119|8@0+ (1,0) [0|255] "cm"  ICC
 SG_ ADS_RadarWarning11Distance_411h : 127|8@0+ (1,0) [0|255] "cm"  ICC
 SG_ ADS_CRC3_411h : 135|8@0+ (1,0) [0|255] ""  ICC
 SG_ ADS_RollgCntr3_411h : 139|4@0+ (1,0) [0|14] ""  ICC
 SG_ ADS_Resd3_411h : 143|4@0+ (1,0) [0|15] ""  ICC
 SG_ ADS_RadarWarning12Distance_411h : 151|8@0+ (1,0) [0|255] "cm"  ICC
 SG_ ADS_RadarWarning13Distance_411h : 159|8@0+ (1,0) [0|255] "cm"  ICC
 SG_ ADS_RadarWarning14Distance_411h : 167|8@0+ (1,0) [0|255] "cm"  ICC
 SG_ ADS_RadarWarning15Distance_411h : 175|8@0+ (1,0) [0|255] "cm"  ICC
 SG_ ADS_RadarWarning0AcLvl_411h : 183|3@0+ (1,0) [0|7] ""  ICC
 SG_ ADS_RadarWarning1AcLvl_411h : 180|3@0+ (1,0) [0|7] ""  ICC
 SG_ ADS_RadarWarning2AcLvl_411h : 177|3@0+ (1,0) [0|7] ""  ICC
 SG_ ADS_RadarWarning3AcLvl_411h : 190|3@0+ (1,0) [0|7] ""  ICC
 SG_ ADS_RadarWarning4AcLvl_411h : 187|3@0+ (1,0) [0|7] ""  ICC
 SG_ ADS_CRC4_411h : 199|8@0+ (1,0) [0|255] ""  ICC
 SG_ ADS_RollgCntr4_411h : 203|4@0+ (1,0) [0|14] ""  ICC
 SG_ ADS_Resd4_411h : 207|4@0+ (1,0) [0|15] ""  ICC
 SG_ ADS_RadarWarning5AcLvl_411h : 215|3@0+ (1,0) [0|7] ""  ICC
 SG_ ADS_RadarWarning6AcLvl_411h : 212|3@0+ (1,0) [0|7] ""  ICC
 SG_ ADS_RadarWarning7AcLvl_411h : 209|3@0+ (1,0) [0|7] ""  ICC
 SG_ ADS_RadarWarning8AcLvl_411h : 222|3@0+ (1,0) [0|7] ""  ICC
 SG_ ADS_RadarWarning9AcLvl_411h : 219|3@0+ (1,0) [0|7] ""  ICC
 SG_ ADS_RadarWarning10AcLvl_411h : 216|3@0+ (1,0) [0|7] ""  ICC
 SG_ ADS_RadarWarning11AcLvl_411h : 229|3@0+ (1,0) [0|7] ""  ICC
 SG_ ADS_RadarWarning12AcLvl_411h : 226|3@0+ (1,0) [0|7] ""  ICC
 SG_ ADS_RadarWarning13AcLvl_411h : 239|3@0+ (1,0) [0|7] ""  ICC
 SG_ ADS_RadarWarning14AcLvl_411h : 236|3@0+ (1,0) [0|7] ""  ICC
 SG_ ADS_RadarWarning15AcLvl_411h : 233|3@0+ (1,0) [0|7] ""  ICC
 SG_ ADC_FuncReq_SentryModWarn_411h : 246|1@0+ (1,0) [0|1] ""  ICC
 SG_ ADC_FuncReq_SentryModDetec_411h : 245|1@0+ (1,0) [0|1] ""  ICC
 SG_ ADC_MdcSentryAlarmMod_411h : 244|1@0+ (1,0) [0|1] ""  ICC

BO_ 769 ADS_HW_301h: 48 CGW
 SG_ ADS_CRC1_301h : 7|8@0+ (1,0) [0|255] ""  ICC
 SG_ ADS_RollgCntr1_301h : 11|4@0+ (1,0) [0|14] ""  ICC
 SG_ ADS_Resd1_301h : 15|4@0+ (1,0) [0|15] ""  ICC
 SG_ ADS_AccFunctionStatus_301h : 23|4@0+ (1,0) [0|15] ""  ICC
 SG_ ADS_LccNcaFunctionStatus_301h : 19|6@0+ (1,0) [0|63] ""  ICC
 SG_ ADS_AdsFucntionNotActive_301h : 29|4@0+ (1,0) [0|15] ""  ICC
 SG_ ADS_AvpFunctionStatus_301h : 25|5@0+ (1,0) [0|31] ""  ICC
 SG_ ADS_SpeedSetByDriver_301h : 36|9@0+ (1,0) [0|511] "kph"  ICC
 SG_ ADS_SpeedLimitValue_301h : 43|8@0+ (1,0) [0|255] "kph"  ICC
 SG_ ADS_SpeedAutoFollow_301h : 51|3@0+ (1,0) [0|7] ""  ICC
 SG_ ADS_OneTouchSpeedAdjustment_301h : 48|3@0+ (1,0) [0|7] ""  ICC
 SG_ ADS_CalibState_301h : 61|3@0+ (1,0) [0|7] ""  ICC
 SG_ ADS_HODReminder_301h : 58|3@0+ (1,0) [0|7] ""  ICC
 SG_ ADS_CRC2_301h : 71|8@0+ (1,0) [0|255] ""  ICC
 SG_ ADS_RollgCntr2_301h : 75|4@0+ (1,0) [0|14] ""  ICC
 SG_ ADS_Resd2_301h : 79|4@0+ (1,0) [0|15] ""  ICC
 SG_ ADS_DMSReminder_301h : 87|4@0+ (1,0) [0|15] ""  ICC
 SG_ ADS_FcwWaning_301h : 83|3@0+ (1,0) [0|7] ""  ICC
 SG_ ADS_FcwFault_301h : 80|2@0+ (1,0) [0|3] ""  ICC
 SG_ ADS_AebWaning_301h : 94|4@0+ (1,0) [0|15] ""  ICC
 SG_ ADS_AebFault_301h : 90|2@0+ (1,0) [0|3] ""  ICC
 SG_ ADS_AebObjType_301h : 88|3@0+ (1,0) [0|7] ""  ICC
 SG_ ADS_RaebWarning_301h : 101|3@0+ (1,0) [0|7] ""  ICC
 SG_ ADS_RaebFault_301h : 98|2@0+ (1,0) [0|3] ""  ICC
 SG_ ADS_RcwWarning_301h : 96|3@0+ (1,0) [0|7] ""  ICC
 SG_ ADS_RcwFault_301h : 109|2@0+ (1,0) [0|3] ""  ICC
 SG_ ADS_FctaLeftWarning_301h : 107|3@0+ (1,0) [0|7] ""  ICC
 SG_ ADS_FctaRightWarning_301h : 104|3@0+ (1,0) [0|7] ""  ICC
 SG_ ADS_FctbLeftWarning_301h : 117|3@0+ (1,0) [0|7] ""  ICC
 SG_ ADS_FctbRightWarning_301h : 114|3@0+ (1,0) [0|7] ""  ICC
 SG_ ADS_RctaLeftWarning_301h : 127|3@0+ (1,0) [0|7] ""  ICC
 SG_ ADS_RctaRightWarning_301h : 124|3@0+ (1,0) [0|7] ""  ICC
 SG_ ADS_RctaFault_301h : 121|2@0+ (1,0) [0|3] ""  ICC
 SG_ ADS_CRC3_301h : 135|8@0+ (1,0) [0|255] ""  ICC
 SG_ ADS_RollgCntr3_301h : 139|4@0+ (1,0) [0|14] ""  ICC
 SG_ ADS_Resd3_301h : 143|4@0+ (1,0) [0|15] ""  ICC
 SG_ ADS_RctbLeftWarning_301h : 151|3@0+ (1,0) [0|7] ""  ICC
 SG_ ADS_RctbRightWarning_301h : 148|3@0+ (1,0) [0|7] ""  ICC
 SG_ ADS_LdwWarning_301h : 145|3@0+ (1,0) [0|7] ""  ICC
 SG_ ADS_LdwFault_301h : 158|3@0+ (1,0) [0|7] ""  ICC
 SG_ ADS_LKAWarning_301h : 155|3@0+ (1,0) [0|7] ""  ICC
 SG_ ADS_LkaFault_301h : 152|2@0+ (1,0) [0|3] ""  ICC
 SG_ ADS_LeftMirrWarningCmd_301h : 166|3@0+ (1,0) [0|7] ""  ICC
 SG_ ADS_RightMirrWarningCmd_301h : 163|3@0+ (1,0) [0|7] ""  ICC
 SG_ ADS_BsdFault_301h : 160|2@0+ (1,0) [0|3] ""  ICC
 SG_ ADS_LeFrntDoorWarningCmd_301h : 174|3@0+ (1,0) [0|7] ""  ICC
 SG_ ADS_LeReDoorWarningCmd_301h : 171|3@0+ (1,0) [0|7] ""  ICC
 SG_ ADS_RiFrntDoorWarningCmd_301h : 168|3@0+ (1,0) [0|7] ""  ICC
 SG_ ADS_RiReDoorWarningCmd_301h : 181|3@0+ (1,0) [0|7] ""  ICC
 SG_ ADS_DowFault_301h : 178|2@0+ (1,0) [0|3] ""  ICC
 SG_ ADS_SpeedLimitWarning_301h : 176|3@0+ (1,0) [0|7] ""  ICC
 SG_ ADS_TsrFault_301h : 189|2@0+ (1,0) [0|3] ""  ICC
 SG_ ADS_TlaFault_301h : 187|2@0+ (1,0) [0|3] ""  ICC
 SG_ ADS_ElkaFault_301h : 185|2@0+ (1,0) [0|3] ""  ICC
 SG_ ADS_CRC4_301h : 199|8@0+ (1,0) [0|255] ""  ICC
 SG_ ADS_RollgCntr4_301h : 203|4@0+ (1,0) [0|14] ""  ICC
 SG_ ADS_Resd4_301h : 207|4@0+ (1,0) [0|15] ""  ICC
 SG_ ADS_AbsoultwSpeedLimit_301h : 215|16@0+ (1,0) [0|65535] "kph"  ICC
 SG_ ADS_TlaWarning_301h : 231|3@0+ (1,0) [0|7] ""  ICC
 SG_ ADS_ElkaWarning_301h : 228|3@0+ (1,0) [0|7] ""  ICC

BO_ 1042 ADS_HW_412h: 16 CGW
 SG_ New_Signal_412_1 : 56|1@0+ (1,0) [0|1] ""  ICC
 SG_ ADS_CRC1_412h : 7|8@0+ (1,0) [0|255] ""  ICC
 SG_ ADS_RollgCntr1_412h : 11|4@0+ (1,0) [0|14] ""  ICC
 SG_ ADS_Resd1_412h : 15|4@0+ (1,0) [0|15] ""  ICC
 SG_ ADS_BrkBeamReq_412h : 23|2@0+ (1,0) [0|3] ""  ICC
 SG_ ADS_AutoLightSwCtrl_412h : 21|2@0+ (1,0) [0|3] ""  ICC
 SG_ ADS_LeFrntDowWarning_412h : 19|2@0+ (1,0) [0|3] ""  ICC
 SG_ ADS_RiFrntDowWarning_412h : 17|2@0+ (1,0) [0|3] ""  ICC
 SG_ ADS_LeReDowWarning_412h : 31|2@0+ (1,0) [0|3] ""  ICC
 SG_ ADS_RiReDowWarning_412h : 29|2@0+ (1,0) [0|3] ""  ICC
 SG_ ADS_LeftMirrWarningCmd_412h : 27|2@0+ (1,0) [0|3] ""  ICC
 SG_ ADS_RightMirrWarningCmd_412h : 25|2@0+ (1,0) [0|3] ""  ICC
 SG_ ADS_ReMirrReq_412h : 39|2@0+ (1,0) [0|3] ""  ICC
 SG_ ADS_DoorLockReq_412h : 37|2@0+ (1,0) [0|3] ""  ICC
 SG_ ADS_SBeltControl_412h : 35|3@0+ (1,0) [0|7] ""  ICC
 SG_ ADS_WshrReq_412h : 32|1@0+ (1,0) [0|1] ""  ICC
 SG_ ADS_SeatShakeControl_412h : 47|2@0+ (1,0) [0|3] ""  ICC
 SG_ ADS_FrtWindshildHeatReq_412h : 45|2@0+ (1,0) [0|3] ""  ICC
 SG_ ADS_HornReq_412h : 43|2@0+ (1,0) [0|3] ""  ICC
 SG_ ADS_LeFmtWinCtrl_412h : 41|2@0+ (1,0) [0|3] ""  ICC
 SG_ ADS_RiFmtWinCtrl_412h : 55|2@0+ (1,0) [0|3] ""  ICC
 SG_ ADS_LeReWinCtrl_412h : 53|2@0+ (1,0) [0|3] ""  ICC
 SG_ ADS_RiReWinCtrl_412h : 51|2@0+ (1,0) [0|3] ""  ICC
 SG_ ADS_TopWinCtrl_412h : 49|2@0+ (1,0) [0|3] ""  ICC
 SG_ ADS_FrontWiperReq_412h : 63|1@0+ (1,0) [0|1] ""  ICC
 SG_ ADS_ChargingPortCmd_412h : 62|2@0+ (1,0) [0|3] ""  ICC
 SG_ ADAS_FctSts_412h : 60|1@0+ (1,0) [0|1] ""  ICC
 SG_ ADS_MdcCrtSts_412h : 59|3@0+ (1,0) [0|7] ""  ICC
 SG_ ADS_CRC2_412h : 71|8@0+ (1,0) [0|255] ""  ICC
 SG_ ADS_RollgCntr2_412h : 75|4@0+ (1,0) [0|14] ""  ICC
 SG_ ADS_Resd2_412h : 79|4@0+ (1,0) [0|15] ""  ICC
 SG_ ADS_HVCtrlReq_412h : 87|1@0+ (1,0) [0|1] ""  ICC
 SG_ ADS_ThmPostRun_412h : 86|1@0+ (1,0) [0|1] "m/s2"  ICC
 SG_ ADS_FlowReq_412h : 85|4@0+ (1,0) [0|15] ""  ICC
 SG_ ADS_PwrOnOffReq_412h : 81|3@0+ (1,0) [0|7] ""  ICC
 SG_ ADS_hmaOnOffSts_412h : 94|2@0+ (1,0) [0|3] ""  ICC
 SG_ ADS_HMAStatus_412h : 92|2@0+ (1,0) [0|3] ""  ICC
 SG_ ADS_HiBeamReq_412h : 90|1@0+ (1,0) [0|1] ""  ICC

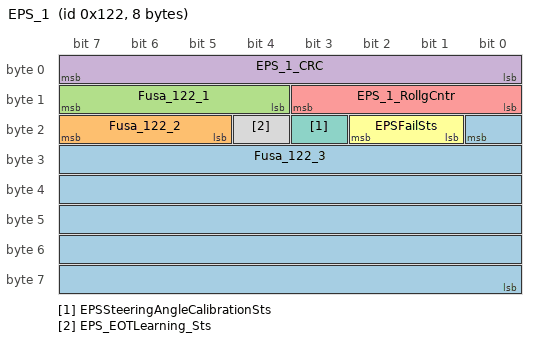
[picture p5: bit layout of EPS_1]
BO_ 290 EPS_1: 8 CGW
 SG_ Fusa_122_3 : 16|41@0+ (1,0) [0|1024] ""  ICC
 SG_ Fusa_122_2 : 23|3@0+ (1,0) [0|7] ""  ICC
 SG_ Fusa_122_1 : 15|4@0+ (1,0) [0|15] ""  ICC
 SG_ EPS_1_CRC : 7|8@0+ (1,0) [0|255] ""  ICC
 SG_ EPS_1_RollgCntr : 11|4@0+ (1,0) [0|14] ""  ICC
 SG_ EPSFailSts : 18|2@0+ (1,0) [0|3] ""  ICC
 SG_ EPSSteeringAngleCalibrationSts : 19|1@0+ (1,0) [0|1] ""  ICC
 SG_ EPS_EOTLearning_Sts : 20|1@0+ (1,0) [0|1] ""  ICC

BO_ 1046 LBMS_SysSt4: 32 CGW
 SG_ LBMS_LoWSocFlt : 87|4@0+ (1,0) [0|15] ""  ICC
 SG_ LBMS_ThermRunawayFlt : 158|1@0+ (1,0) [0|1] ""  ICC
 SG_ LBMS_SysFlt : 157|1@0+ (1,0) [0|1] ""  ICC
 SG_ LBMS_LowPowerRemind : 167|4@0+ (1,0) [0|15] ""  ICC
 SG_ LBMS_EndLifeFlt : 152|1@0+ (1,0) [0|1] ""  ICC

BO_TX_BU_ 571 : FLZCU_HCU_IC,FLZCU_IC,FLZCU_Signal_IC;
BO_TX_BU_ 699 : FLZCU_HCU_IC,FLZCU_IC,FLZCU_Signal_IC;
BO_TX_BU_ 787 : CGW,FRZCU;
BO_TX_BU_ 1212 : FLZCU_HCU_IC,HCU_IC;
BO_TX_BU_ 1120 : FLZCU_HCU_IC,FLZCU_IC,FLZCU_Signal_IC;
CM_ SG_ 1096 TMS_AirPurgeReminderSts "空气净化提醒开关状态";
CM_ SG_ 1096 TMS_BT_Reduce_Wind_SpeedSts "蓝牙通话降低风速状态";
CM_ SG_ 1096 TMS_First_BlowingSts "空调启动时第一口风状态";
CM_ SG_ 1096 TMS_CirculationInTunnelsSts "隧道内循环状态";
CM_ SG_ 1096 TMS_crosscountry_coolingSts "越野散热状态";
CM_ SG_ 1096 TMS_ParkingAirConditioningStatus "驻车空调状态工作状态";
CM_ SG_ 1096 TMS_CoolantFillSts "一键除气";
CM_ SG_ 1096 TMS_UVC_ControlSts "UVC控制反馈";
CM_ SG_ 1096 TMS_AutoDefogActiveSts "自动除雾开启后激活功能弹窗使用";
CM_ SG_ 1096 TMS_UVC_LuminanceSts "UVC亮度反馈";
CM_ SG_ 1096 TMS_ICC_Lightoff_Sts "香氛氛围灯开关状态";
CM_ SG_ 1096 TMS_ICC_Memoff_Sts "香氛记忆开关状态";
CM_ SG_ 1096 TMS_keepwarmSet_TemperatureSts "恒温模式温度设置";
CM_ SG_ 1096 TMS_CFSCycleLevel "香氛循环等级";
CM_ SG_ 1096 TMS_TimingLevel "香氛定时等级";
CM_ SG_ 1096 TMS_BiochemicalFuncSts "生化功能开关反馈";
CM_ SG_ 1096 TMS_TimedVentilationSts "大屏定时换气开关状态反馈";
CM_ SG_ 1240 TMS_CFSSwitchFb "香氛系统开关设置反馈";
CM_ SG_ 1240 TDU_CFSPosOneType "香氛位置1香型";
CM_ SG_ 1240 TDU_CFSPosTwoType "香氛位置2香型";
CM_ SG_ 1240 TDU_CFSPosThreeType "香氛位置3香型";
CM_ SG_ 1240 TDU_CFSRunOut "香氛已用完提醒";
CM_ SG_ 1240 TMS_CFSShortWarn "香氛不足提醒";
CM_ SG_ 1240 TMS_CFSLevelSetFb "香氛工作浓度";
CM_ SG_ 1240 TMS_CFSPosSetFb "香氛工作位置反馈";
CM_ SG_ 1240 TMS_CFSPosOneLife "通道一香氛寿命";
CM_ SG_ 1240 TMS_CFSPosTwoLife "通道二香氛寿命";
CM_ SG_ 1240 TMS_CFSPosThreeLife "通道三香氛寿命";
CM_ SG_ 1240 TMS_PM25SwitchFb "PM2.5状态反馈";
CM_ SG_ 1240 TMS_AQSCOSts_2 "J版AQS检测CO污染等级";
CM_ SG_ 1240 TMS_AQSNO2Sts_2 "J版AQS检测NO2污染等级";
CM_ SG_ 1240 TMS_AQSN02SnsrSts_2 "J版AQS中NO2传感器工作状态
0x0:初始阶段
0x1:工作阶段
0x2:待机阶段
0x3:故障阶段";
CM_ SG_ 1240 TMS_AQSLifeCntr_2 "J版AQS内部循环状态";
CM_ SG_ 1240 TMS_AQSErrSts_2 "J版空气质量传感器故障状态(内部故障诊断)  
0x0:信号无效
0x1:传感器正常
0x2:传感器过压工作
0x3:传感器MCU温度超高
0x4:传感器内部故障";
CM_ SG_ 1240 TMS_AQSErrRespAQSM_2 "J版AQS通讯状态";
CM_ SG_ 1240 TMS_AQSAirQlySts_2 "J版传感器感受到的污染状态
0x0:无污染
0x1:低度污染
0x2:中度污染
0x3:重度污染
0x4:信号无效
0x5~0x7:Reserved";
CM_ SG_ 1240 TMS_ThrModeStsFb "三排模式反馈";
CM_ SG_ 1240 TMS_ThrSetTempFb_C "三排温度反馈";
CM_ SG_ 1240 TMS_ThrCLMSwitchFb "三排空调状态反馈";
CM_ SG_ 1240 TMS_ThrAutoSwitchFb "空调自动状态显示";
CM_ SG_ 1240 TMS_ThrBlowSpeedLevelKeyStsFb "三排鼓风机档位";
CM_ SG_ 638 FRZCU_HoodSts "前舱盖状态";
CM_ SG_ 638 FRZCU_PowerMode "低压电源状态";
CM_ SG_ 638 SeatLength_target_Passenger "座椅水平位置调节";
CM_ SG_ 638 SeatBackrest_target_Passenger "座椅靠背角度调节";
CM_ SG_ 638 FrontBackSpeedAdj_Cmd "Front_Back_Speed_Adjust_Command
座椅前后调节速度信号";
CM_ SG_ 638 FRZCU_GloveboxSW "上报手套箱开关状态";
CM_ SG_ 638 FRZCU_FRReleaseLockSts "右前电释放状态
0x0:None
0x1:已释放
0x2:释放中
0x3:已复位
0x4:复位中";
CM_ SG_ 638 FRZCU_RRReleaseLockSts "右后电释放状态
0x0:None
0x1:已释放
0x2:释放中
0x3:已复位
0x4:复位中";
CM_ SG_ 638 FRZCU_PELockInKeyWarning "PE闭锁车内有钥匙提醒";
CM_ SG_ 638 FRZCU_PowerOFFWarning "电源下电提醒";
CM_ SG_ 638 FRZCU_KeylessWarning "无合法钥匙提醒";
CM_ SG_ 638 FRZCU_OTAPwrDwnReqFb "OTA_Power_Down_Request_FeedBack";
CM_ SG_ 638 FRZCU_OTAPwrOnReqFb "OTA_Power_On_Request_FeedBack";
CM_ SG_ 949 PEPS_InformationSource "To_show_the_lock/unlock_information_is_from_Smart_or_RKE_.";
CM_ SG_ 949 PEPS_OrderInformation "PEPS_do_not_add_any_additional_logic._Just_reflect_the_status_of_the_switch_state.";
CM_ SG_ 949 PEPS_KeySts "PEPS钥匙位置状态";
CM_ SG_ 949 PEPS_ETRUnLockReq "尾门靠近解锁请求";
CM_ SG_ 1028 PEPS_WelcomeON "welcome_light_request
迎宾开启请求";
CM_ SG_ 1028 PEPS_VehicleSearchReq "寻车请VehicleSearchRequest
寻车请求";
CM_ SG_ 1028 PEPS_SATOReminder "Easy_trunk_function_start_light
进入后备箱区域激活ETR功能闪灯信号";
CM_ SG_ 1028 PEPS_PLGUnlockReq "PLG解锁指令";
CM_ SG_ 1028 PEPS_RKETrunkSts "实体钥匙尾门按键";
CM_ SG_ 1028 PEPS_SSBInhibitCWCSts "OFF档时点按SSB，发送1值。
OFF档，CWC接收到SSBInhibitCWCSts=1后屏蔽无线充电功能；";
CM_ SG_ 1028 PEPS_WirelessChargingCtrSts "发送1时，PEPS处于搜索遥控钥匙的状态，无线充电功能应关闭";
CM_ SG_ 1028 PEPS_EmgyShutdown "Emergency_shut_down._If_happen_,Send_three_frame_continuous_signal_1
此信号代表发生过紧急熄火功能。如果没发生都是发0，如果发生了，连续发3帧1出来。";
CM_ SG_ 1028 PEPS_SSBInputFailure "The_warning_indicator_the_SSB_is_faulty";
CM_ SG_ 1028 PEPS_SmartSystemWarning1_1 "非OFF档关门钥匙不在车内报警";
CM_ SG_ 1028 PEPS_SmartSystemWarning2_2 "车速无钥匙报警";
CM_ SG_ 1028 PEPS_SmartSystemWarning3_1 "钥匙电池电量低报警";
CM_ SG_ 1028 PEPS_SmartSystemWarning3_2 "用于SSB启动时，非P档时启动报警";
CM_ SG_ 1028 PEPS_SmartSystemWarning4_2 "用于SSB启动时，未踩刹车提醒报警";
CM_ SG_ 1028 PEPS_SmartSystemWarning4_3 "下电不在P档报警";
CM_ SG_ 1028 PEPS_SystemWarning "PEPS系统故障提醒";
CM_ SG_ 1028 PEPS_BLTKeyPESts "蓝牙钥匙的PE功能开启关闭状态信号";
CM_ SG_ 1291 BMS_2_G_CRC "Profile1A:E2E CRC (SAE J1850 CRC-8) for 8 Bytes
DataID:0x0075";
CM_ SG_ 1291 BMS_2_G_RollgCntr "Profile1A:E2E Rolling message counter(the maximum value of Alive counter is 14)";
CM_ SG_ 1291 BMS_2_G_Resd "Profile1A:E2E Reserved";
CM_ SG_ 1291 BMS_TBOXInsulation_R "insulation resistance";
CM_ SG_ 1291 BMS_TBOXErrorNumber "BMS Error Numbers";
CM_ SG_ 1291 BMS_TBOXHvBattMaxT "battery max temperature";
CM_ SG_ 1291 BMS_TBOXHvBattMinT "battery min temperature";
CM_ SG_ 1291 BMS_SOCLight "BMS_SOCLight
SOC电量显示（仪表显示）";
CM_ SG_ 587 ONEBOX_4_LHFWheelSpeedRPM "left front Wheel Speed(the unit is RPM)";
CM_ SG_ 587 ONEBOX_4_RHFWheelSpeedRPM "right front  Wheel Speed(the unit is RPM)";
CM_ SG_ 587 LHRWheelSpeedRPM "Left Rear Wheel Speed(the unit is RPM)";
CM_ SG_ 587 RHRWheelSpeedRPM "right Rear  Wheel Speed(the unit is RPM)";
CM_ SG_ 587 LHRPulseCounterFailSts "left rear wheel Pulse Counter Fail Status";
CM_ SG_ 587 LHRPulseCounter "left rear wheel Pulse Counter";
CM_ SG_ 587 RHRPulseCounterFailSts "right rear wheel Pulse Counter FailSts";
CM_ SG_ 587 RHRPulseCounter "right rear wheel Pulse Counter";
CM_ SG_ 587 RHFPulseCounterFailSts "right front wheel Pulse Counter FailSts";
CM_ SG_ 587 RHFPulseCounter "right front wheel Pulse Counter";
CM_ SG_ 587 LHFPulseCounterFailSts "left front wheel Pulse Counter FailSts";
CM_ SG_ 587 LHFPulseCounter "left front wheel Pulse Counter";
CM_ SG_ 587 LHFWheelDriveDirection "left front Wheel Drive Direction";
CM_ SG_ 587 RHFWheelDriveDirection "right front Wheel Speed Drive Direction";
CM_ SG_ 587 LHRWheelDriveDirection "left rear Wheel Speed Drive Direction";
CM_ SG_ 587 RHRWheelDriveDirection "right rear Wheel Speed Drive Direction";
CM_ SG_ 1338 FMCU_ErrLvlDis "Error Level";
CM_ SG_ 1338 FMCU_SpdAct_EDR "FMCU motor actual speed";
CM_ SG_ 777 ISGF_ErrLvl "Error Level";
CM_ SG_ 1403 RMCU_ErrLvlDis "Error Level";
CM_ SG_ 1403 RMCU_Speed_EDR "RMCU motor actual speed";
CM_ SG_ 1299 BMS_PackVoltageDis "Battery Voltage（高压后的表显电压，不上高压发0）";
CM_ SG_ 1299 BMS_PackCurrentDis "Battery Current(direction:discharge+ charge -)";
CM_ SG_ 1099 ISGF_SysTempOvrInd "Indicator of overheat warning lamp（捷途D01不使用）";
CM_ SG_ 1130 TCU_23_GBFaultstatus "Activation gearbox error Lamp, only for ICM including LCD to light LED and LCD. This signal should be sent with “AGErrorLamp” simultaneously";
CM_ SG_ 1130 TCU_23_TeachInState "TCU自学习状态";
CM_ SG_ 1130 TCU_23_GBWarmUpReq "变速箱暖机请求（T1J FL2智驾版3DHT使用）";
CM_ SG_ 1130 TCU_23_CluSelfLrng "离合器自学习状态（T1J FL2智驾版3DHT使用）";
CM_ SG_ 1180 ACU_1_ThdRowLBeltWarning "With Occupancy detection：
Third row (left) safety belt status
0x0:not occupied/occupied and fastened
0x1:occupied and not fastened 
Without Occupancy detection：
0x0:Seat belt is fastened
0x1:Seat belt is not fastened";
CM_ SG_ 1180 ACU_1_ThdRowRBeltWarning "With Occupancy detection：
Third row (right) safety belt status
0x0:not occupied/occupied and fastened
0x1:occupied and not fastened 
Without Occupancy detection：
0x0:Seat belt is fastened
0x1:Seat belt is not fastened";
CM_ SG_ 1180 ACU_1_PsngrSeatBeltWarning "In addition to the corresponding value sent by ACU with copilot safety belt alarm, the signal sent by ACU without alarm configuration sends the startup value.
The signal is judged in combination with SBR";
CM_ SG_ 1180 ACU_1_SecRowLBeltWarning "With Occupancy detection：
Second row (left) safety belt status
0x0:not occupied/occupied and fastened
0x1:occupied and not fastened 
Without Occupancy detection：
0x0:Seat belt is fastened
0x1:Seat belt is not fastened";
CM_ SG_ 1180 ACU_1_SecRowMBeltWarning "With Occupancy detection：
Second row (middle) safety belt status
0x0:not occupied/occupied and fastened
0x1:occupied and not fastened 
Without Occupancy detection：
0x0:Seat belt is fastened
0x1:Seat belt is not fastened";
CM_ SG_ 1180 ACU_1_SecRowRBeltWarning "With Occupancy detection：
Second row (right) safety belt status
0x0:not occupied/occupied and fastened
0x1:occupied and not fastened 
Without Occupancy detection：
0x0:Seat belt is fastened
0x1:Seat belt is not fastened";
CM_ SG_ 1180 ACU_1_PsngrSeatOccupiedSts "副驾座椅占位状态，0为未占位，1为占位
E03：国内\国际非欧盟一、二阶段都体现，类欧盟\欧盟不分阶段都体现；
E0Y：国内\国际非欧盟，类欧盟\欧盟都体现；
0x2:open circuit (03仅欧盟、类欧盟做，0Y都做)
0x3:short circuit (03仅欧盟、类欧盟做，0Y都做)";
CM_ SG_ 1341 BMS_44_PackPowerRealTime "捷途新增动力电池包实时功率";
CM_ SG_ 811 BMS_Chg_Sts "BMS_Chg_Sts";
CM_ SG_ 1427 ILCF_1_LogoParkingSts "前LOGO驻车点亮开关状态反馈";
CM_ SG_ 1172 ExternalTemperature_F "External_temperature（F）（外部温度（华氏度））";
CM_ SG_ 1172 ExternalTemperature_C "External_temperature（℃）
Invalid:_When_external_temperature_is_fail,_the_signal_value_is_0xFE.";
CM_ SG_ 1172 BlowSpeedLevelDisplaySts "Blow_Speed_Level_feedback
鼓风机档位
0xB:Auto后面要加这个属性";
CM_ SG_ 1147 CCP_1_FLTempSwitchReq "按下触摸到抬起一次，20ms信号有效的时候连发3帧，后期周期间隔100ms，按照当前状态发送";
CM_ SG_ 1147 CCP_1_FrontAutoACSwitchReq "前排自动功能";
CM_ SG_ 1147 CCP_1_FBlowSpdCtrlSwitchReq "前排风速";
CM_ SG_ 1147 FLCCP_MainSetHeatReq "主驾座椅加热";
CM_ SG_ 1147 FLCCP_MainSetVentilationReq "主驾座椅通风";
CM_ SG_ 1107 TMS_CCP_FLTempSts "前排左侧温度设置";
CM_ SG_ 1107 TMS_CCP_FrontAutoACSts "前排自动功能";
CM_ SG_ 1107 TMS_CCP_ACStatus "ACStatus
AC_状态";
CM_ SG_ 1107 TMS_CCP_FrontOFFSts "空调关闭";
CM_ SG_ 1107 TMS_CCP_FBlowSpdCtrlSts "前排风速设置";
CM_ SG_ 1107 TMS_CCP_FRTempSts "前排右侧温度设置";
CM_ SG_ 1107 TMS_CCP_RecyMode "内外循环";
CM_ SG_ 1107 TMS_CCP_FrontDefrostSts "前除霜";
CM_ SG_ 1107 TMS_UVC_WorkingBfReq "紫外线杀菌灯请求";
CM_ SG_ 1107 TMS_UVC_LuminanceBfReq "紫外线杀菌灯强度请求";
CM_ SG_ 1107 TMS_CCP_ACFastCool "一键制冷反馈";
CM_ SG_ 1107 TMS_CCP_ACFastHeat "一键制热反馈";
CM_ SG_ 1175 CCP_2_FRTempSwitchReq "同上";
CM_ SG_ 1175 CCP_2_RecyModeReq "内外循环";
CM_ SG_ 1175 CCP_2_DefrostModeSwitchReq "前除霜";
CM_ SG_ 1175 CCP_2_RearDefrostSwitchReq "后除霜请求";
CM_ SG_ 1175 CCP_2_ACSwitchReq "AC开关请求";
CM_ SG_ 1292 CHB_App_Sts "冰箱开关状态（捷途预留）";
CM_ SG_ 1292 CHB_AppMem_Sts "记忆开关状态";
CM_ SG_ 1292 CHB_AppDelay_Sts "延时开关状态";
CM_ SG_ 1292 CHB_AppTimeset_Sts "延时时间设置";
CM_ SG_ 1292 CHB_AppCoolorheat_Sts "制冷制热选择状态
冰箱工作模式（捷途使用）
0x0：无请求
0x1：制冷
0x2：制热
0x3：关
0x4：冷饮模式
0x5：冰淇淋模式
0x6：温奶模式
0x7：热饮模式";
CM_ SG_ 1292 CHB_AppCoolset_Sts "制冷温度设置
0xE~0x19:-18℃~-7℃（捷途预留）
0x1~0xD:-6℃~6℃（捷途使用）";
CM_ SG_ 1292 CHB_AppHeatset_Sts "制热温度调节设置";
CM_ SG_ 1292 CHB_AppSterilization_Sts "杀菌开关状态";
CM_ SG_ 1292 CHB_AppItemsLeft_Sts "物品遗留开关状态";
CM_ SG_ 1292 CHB_AppItemsLeftset_Sts "冰箱是否检测到物品的状态";
CM_ SG_ 1292 CHB_AppChbDoor_Sts "冰箱是门开关状态反馈信号";
CM_ SG_ 1241 FuelTankLidSystemFailureSts "加油小门系统故障信号";
CM_ SG_ 1241 FuelTankPressureConditionReached "油箱压力状态信号";
CM_ SG_ 49 ACU_2_LateralAcceleration "Lateral acceleration signal
Sensor accuracy：0.0027680342857143g";
CM_ SG_ 49 ACU_2_YawRate "Yaw rate signal
Sensor accuracy：0.122189236 deg/s";
CM_ SG_ 49 ACU_2_YawrateSigValidData "Signal state for yawrate";
CM_ SG_ 49 ACU_2_LateralAccelerationSigVD "If hasn’t been calibrated, after initialization, this signal ‘s value is always 10(invalid).";
CM_ SG_ 1024 CSunshadeSts "天幕遮阳帘实际状态
(大屏动效-可显示开启和关闭的动画)";
CM_ SG_ 1024 CSunshadePercentSts "天幕遮阳帘开度百分比状态";
CM_ SG_ 1024 FRZCU_SeatHeatLvlFR2 "副驾座椅加热状态--捷途使用";
CM_ SG_ 1024 FRZCU_SeatVentLvlFR2 "副驾座椅通风状态--捷途使用";
CM_ SG_ 1024 FRZCU_SeatVentLvlRR2 "二排右侧座椅通风状态--捷途使用";
CM_ SG_ 1024 FRZCU_SeatHeatLvlRR2 "二排右侧座椅加热状态--捷途使用";
CM_ SG_ 1024 FRZCU_ContainerlightSts "货箱灯状态反馈（D01P)";
CM_ SG_ 1024 FRZCU_FRWinThermalSts "右前车窗热保护状态
0：未触发热保护
1：热保护触发中";
CM_ SG_ 1024 FRZCU_RRWinThermalSts "右后车窗热保护状态
0：未触发热保护
1：热保护触发中";
CM_ SG_ 1024 FRZCU_CSunshadeThermalSts "天幕遮阳帘热保护状态
0：未触发热保护
1：热保护触发中";
CM_ SG_ 1182 OBC_ElectronicLockSts "Electronic Lock Sts";
CM_ SG_ 1182 OBC_WorkingMode "OBC working states";
CM_ SG_ 513 MFSL_APA_SW "APA开关";
CM_ SG_ 513 MFSL_LCC_NCA_SW "行车功能激活按键";
CM_ SG_ 1152 TBOX_PetmodeSetTemperature "宠物模式远程空调温度设置";
CM_ SG_ 1164 OBC_DischgSts "（新增OBC中控屏使用外放电电流显示）
0x0:NoDischarge
0x1:Discharging(外放电)
0x2:Discharging-Interior(内放电)
0x3:Discharging_AND_Discharging-Interior(内外放电同时进行)";
CM_ SG_ 789 ATCM_DriveModeSw "驾驶模式状态
（正旋一次共发送4帧信号：
三帧0×1加一帧0×0
反旋一次共发送4帧信号：
三帧0×2加一帧0×0
信号周期20ms/帧）";
CM_ SG_ 789 ATCM_XModeSw "X模式状态";
CM_ SG_ 789 ATCM_SwitchUTurnModeSet "极限掉头开关/坦克掉头
（点击一次共发送3帧信号：
三帧0×1）";
CM_ SG_ 789 ATCM_ESP_OFF_SW "车身稳定控制系统关闭ESP—OFF开关
（点击一次共发送3帧信号：
三帧0×1）";
CM_ SG_ 789 ATCM_AVH_SW "自动驻车/AVH开关
（点击一次共发送3帧信号：
三帧0×1）";
CM_ SG_ 789 ATCM_AVM "AVM开关
（点击一次共发送3帧信号：
三帧0×1）";
CM_ SG_ 1214 BNCM_16_CRC1 "Profile1A:E2E CRC (SAE J1850 CRC-8) for 8 Bytes
DataID:No ASIL requirements.Not configure
CRC Reserved.";
CM_ SG_ 1214 BNCM_16_RollgCntr1 "Profile1A:E2E Rolling message counter(the maximum value of Alive counter is 14)要求启动计数，每发一帧计数一次，到最大值14之后从0重新计数，防止有两个连续单帧的情况发生";
CM_ SG_ 1214 BNCM_16_Resd1 "Profile1A:E2E Reserved";
CM_ SG_ 571 LHTurnlightSts "转向灯-左";
CM_ SG_ 571 RHTurnlightSts "转向灯-右";
CM_ SG_ 571 LHFDoorLockSts "主驾门锁";
CM_ SG_ 571 LHTurnSW "左转向开关，打开发1；关闭发0，默认发0";
CM_ SG_ 571 RHTurnSW "右转向开关，打开发1；关闭发0，默认发0";
CM_ SG_ 571 HazardLightSW "带自锁的开关，按照危险灯状态发送；不带自锁的开关，发送危险灯状态";
CM_ SG_ 571 LHFSeatBeltSW "安全带检测开关，0为未插入，1为插入";
CM_ SG_ 571 DirectionIndLeft "当左转向灯闪烁时一直发1，转向灯熄灭时一直发0.";
CM_ SG_ 571 DirectionIndRight "当右转向灯闪烁时一直发1，转向灯熄灭时一直发0.";
CM_ SG_ 699 LHRdoorSts "左后门状态";
CM_ SG_ 787 ChrgHoodSts "充电口盖状态反馈
股份FLZCU0x33E发，捷途由FRZCU发";
CM_ SG_ 787 FRZCU_FRSitPosnSts "副驾座椅记忆位置反馈";
CM_ SG_ 572 ONEBOX_7_TAB_HighTemp "坦克转弯工作温度过高";
CM_ SG_ 572 ONEBOX_7_TAB_Active "IPB反馈TAB状态";
CM_ SG_ 572 ONEBOX_7_BSW_Active "智能擦盘状态反馈信号";
CM_ SG_ 572 ONEBOX_7_iCCO_TgtVel "iCCO功能目标车速";
CM_ SG_ 1212 VCU_3_G_ActWheelTorqueFA "Actual wheel torque at FA前轮轮端实际扭矩";
CM_ SG_ 1212 VCU_3_G_ActWheelTorqueRA "Actual wheel torque at RA后轮轮端实际扭矩";
CM_ SG_ 1120 RLHS_2_AmbBrightness "顶向光";
CM_ SG_ 1120 RLHS_LiSwithReason "开关灯切换原因
RLS_ LightSwithReason";
CM_ SG_ 1199 TCM_1_TrailerSts "Trailer Status send by TCM. Vehicle can use this information to turn off/on some assistance like Park Distance Control. Furthermore it might be used to turn off the fog light on the vehicle when a trailer is connected (at least in germany, there is a law saying that the vehicles fog lamp must not be turned on when a trailer is connected - only the fog of the trailer should be turned on).";
CM_ SG_ 770 ADS_CRC1_302h "Profile1A:E2E CRC (SAE J1850 CRC-8) for 8 Bytes
DataID:Reserved";
CM_ SG_ 770 ADS_RollgCntr1_302h "Profile1A:E2E Rolling message counter(the maximum value of Alive counter is 14)";
CM_ SG_ 770 ADS_Resd1_302h "Profile1A:E2E Reserved";
CM_ SG_ 770 ADS_RPAOnlineOrNot_302h "RPA业务心跳消息";
CM_ SG_ 770 ADS_RpaParkAuthn_302h "RPA泊车授权";
CM_ SG_ 770 ADS_SeldParkID_302h "选中的目标车位ID号";
CM_ SG_ 770 ADS_VehParkMod_302h "自车泊入方式";
CM_ SG_ 770 ADS_RemParkPatSel_302h "RPA远程泊车模式选择确认";
CM_ SG_ 770 ADS_ParkDirCfm_302h "RPA泊出方向确认";
CM_ SG_ 770 ADS_ParkProgs_302h "泊车进度0~100%";
CM_ SG_ 770 ADS_ParkRmngDst_302h "泊车剩余距离0~50m";
CM_ SG_ 770 ADS_ObstclDst_302h "障碍物距离";
CM_ SG_ 770 ADS_AutEve_302h "智能驾驶事件（RPA指示信息）";
CM_ SG_ 770 ADS_CRC2_302h "Profile1A:E2E CRC (SAE J1850 CRC-8) for 8 Bytes
DataID:Reserved";
CM_ SG_ 770 ADS_RollgCntr2_302h "Profile1A:E2E Rolling message counter(the maximum value of Alive counter is 14)";
CM_ SG_ 770 ADS_Resd2_302h "Profile1A:E2E Reserved";
CM_ SG_ 770 ADS_parkInterruptDuration_302h "RPA暂停倒计时";
CM_ SG_ 770 APA_ResuAvl_302h "RPA功能是否可以恢复泊车";
CM_ SG_ 770 ADS_ParkStMac_302h "泊车状态机";
CM_ SG_ 770 ADS_ParkOutDir_ParaLe_302h "水平向左";
CM_ SG_ 770 ADS_ParkOutDir_ParaRi_302h "水平向右";
CM_ SG_ 770 ADS_ParkOutDir_PerpFwd_302h "垂直向前";
CM_ SG_ 770 ADS_ParkOutDir_PerpLeFwd_302h "垂直向左前";
CM_ SG_ 770 ADS_ParkOutDir_PerpRiFwd_302h "垂直向右前";
CM_ SG_ 770 ADS_ParkOutDir_PerpLeBack_302h "垂直向左后";
CM_ SG_ 770 ADS_ParkOutDir_PerpRiBack_302h "垂直向右后";
CM_ SG_ 770 ADS_ParkOutDir_PerpBack_302h "垂直向后";
CM_ SG_ 770 APA_RPAFctUnavlMsg_1_302h "RPA功能不可用原因1";
CM_ SG_ 770 APA_RPAFctUnavlMsg_2_302h "RPA功能不可用原因2";
CM_ SG_ 770 APA_RPAFctUnavlMsg_3_302h "RPA功能不可用原因3";
CM_ SG_ 770 APA_RPAFctUnavlMsg_4_302h "RPA功能不可用原因4";
CM_ SG_ 770 APA_RPAFctUnavlMsg_5_302h "RPA功能不可用原因5";
CM_ SG_ 770 APA_RPAFctUnavlMsg_6_302h "RPA功能不可用原因6";
CM_ SG_ 770 APA_RPAFctUnavlMsg_7_302h "RPA功能不可用原因7";
CM_ SG_ 770 APA_RPAFctUnavlMsg_8_302h "RPA功能不可用原因8";
CM_ SG_ 770 APA_RPAFctUnavlMsg_9_302h "RPA功能不可用原因9";
CM_ SG_ 770 APA_RPAFctUnavlMsg_10_302h "RPA功能不可用原因10";
CM_ SG_ 770 APA_RPAFctUnavlMsg_11_302h "RPA功能不可用原因11";
CM_ SG_ 770 APA_RPAFctUnavlMsg_12_302h "RPA功能不可用原因12";
CM_ SG_ 770 APA_RPAFctUnavlMsg_13_302h "RPA功能不可用原因13";
CM_ SG_ 770 APA_RPAFctUnavlMsg_14_302h "RPA功能不可用原因14";
CM_ SG_ 770 APA_RPAFctUnavlMsg_15_302h "RPA功能不可用原因15";
CM_ SG_ 770 APA_RPAFctUnavlMsg_16_302h "RPA功能不可用原因16";
CM_ SG_ 770 APA_RPAFctUnavlMsg_17_302h "RPA功能不可用原因17";
CM_ SG_ 770 APA_RPAFctUnavlMsg_18_302h "RPA功能不可用原因18";
CM_ SG_ 770 APA_RPAFctUnavlMsg_19_302h "RPA功能不可用原因19";
CM_ SG_ 770 APA_RPAFctUnavlMsg_20_302h "RPA功能不可用原因20";
CM_ SG_ 770 APA_RPAFctUnavlMsg_21_302h "RPA功能不可用原因21";
CM_ SG_ 770 APA_RPAFctUnavlMsg_22_302h "RPA功能不可用原因22";
CM_ SG_ 770 APA_RPAFctUnavlMsg_23_302h "RPA功能不可用原因23";
CM_ SG_ 770 APA_RPAFctUnavlMsg_24_302h "RPA功能不可用原因24";
CM_ SG_ 770 APA_RPAFctUnavlMsg_25_302h "RPA功能不可用原因25";
CM_ SG_ 770 ADS_CRC3_302h "Profile1A:E2E CRC (SAE J1850 CRC-8) for 8 Bytes
DataID:Reserved";
CM_ SG_ 770 ADS_RollgCntr3_302h "Profile1A:E2E Rolling message counter(the maximum value of Alive counter is 14)";
CM_ SG_ 770 ADS_Resd3_302h "Profile1A:E2E Reserved";
CM_ SG_ 770 APA_RPACnclMsg_1_302h "RPA功能取消原因1";
CM_ SG_ 770 APA_RPACnclMsg_2_302h "RPA功能取消原因2";
CM_ SG_ 770 APA_RPACnclMsg_3 "RPA功能取消原因3";
CM_ SG_ 770 APA_RPACnclMsg_4_302h "RPA功能取消原因4";
CM_ SG_ 770 APA_RPACnclMsg_5_302h "RPA功能取消原因5";
CM_ SG_ 770 APA_RPACnclMsg_6_302h "RPA功能取消原因6";
CM_ SG_ 770 APA_RPACnclMsg_7_302h "RPA功能取消原因7";
CM_ SG_ 770 APA_RPACnclMsg_8_302h "RPA功能取消原因8";
CM_ SG_ 770 APA_RPACnclMsg_9_302h "RPA功能取消原因9";
CM_ SG_ 770 APA_RPACnclMsg_10_302h "RPA功能取消原因10";
CM_ SG_ 770 APA_RPACnclMsg_11_302h "RPA功能取消原因11";
CM_ SG_ 770 APA_RPACnclMsg_12_302h "RPA功能取消原因12";
CM_ SG_ 770 APA_RPACnclMsg_13_302h "RPA功能取消原因13";
CM_ SG_ 770 APA_RPACnclMsg_14_302h "RPA功能取消原因14";
CM_ SG_ 770 APA_RPACnclMsg_15_302h "RPA功能取消原因15";
CM_ SG_ 770 APA_RPACnclMsg_16_302h "RPA功能取消原因16";
CM_ SG_ 770 APA_RPACnclMsg_17_302h "RPA功能取消原因17";
CM_ SG_ 770 APA_RPACnclMsg_18_302h "RPA功能取消原因18";
CM_ SG_ 770 APA_RPACnclMsg_19_302h "RPA功能取消原因19";
CM_ SG_ 770 APA_RPACnclMsg_20_302h "RPA功能取消原因20";
CM_ SG_ 770 APA_RPAPauseMsg_1_302h "RPA功能暂停原因1";
CM_ SG_ 770 APA_RPAPauseMsg_2_302h "RPA功能暂停原因2";
CM_ SG_ 770 APA_RPAPauseMsg_3_302h "RPA功能暂停原因3";
CM_ SG_ 770 APA_RPAPauseMsg_4_302h "RPA功能暂停原因4";
CM_ SG_ 770 APA_RPAPauseMsg_5_302h "RPA功能暂停原因5";
CM_ SG_ 770 APA_RPAPauseMsg_6_302h "RPA功能暂停原因6";
CM_ SG_ 770 APA_RPAPauseMsg_7_302h "RPA功能暂停原因7";
CM_ SG_ 770 APA_RPAPauseMsg_8_302h "RPA功能暂停原因8";
CM_ SG_ 770 APA_RPAPauseMsg_9_302h "RPA功能暂停原因9";
CM_ SG_ 770 APA_RPAPauseMsg_10_302h "RPA功能暂停原因10";
CM_ SG_ 770 ADS_ParkPosn1_ID_302h "车位1_ID号0~15";
CM_ SG_ 770 ADS_MnvrOrintChng1_302h "目标车位1类型";
CM_ SG_ 770 ADS_MnvrOrintChng2_302h "目标车位2类型";
CM_ SG_ 770 ADS_ParkRelPos1_x1_302h "目标车位相对位置1_x1(-50.0~50.0m)";
CM_ SG_ 770 ADS_CRC4_302h "Profile1A:E2E CRC (SAE J1850 CRC-8) for 8 Bytes
DataID:Reserved";
CM_ SG_ 770 ADS_RollgCntr4_302h "Profile1A:E2E Rolling message counter(the maximum value of Alive counter is 14)";
CM_ SG_ 770 ADS_Resd4_302h "Profile1A:E2E Reserved";
CM_ SG_ 770 ADS_ParkRelPos1_y1_302h "目标车位相对位置1_y1(-50.0~50.0m)";
CM_ SG_ 770 ADS_ParkRelPos1_x2_302h "目标车位相对位置1_x2(-50.0~50.0m)";
CM_ SG_ 770 ADS_ParkRelPos1_y2_302h "目标车位相对位置1_y2(-50.0~50.0m)";
CM_ SG_ 770 ADS_ParkRelPos1_x3_302h "目标车位相对位置1_x3(-50.0~50.0m)";
CM_ SG_ 770 ADS_TarParkSt_Posn1_302h "目标车位1的状态";
CM_ SG_ 770 ADS_ParkChkSrc_Posn1_302h "目标车位1检测来源";
CM_ SG_ 770 ADS_CRC5_302h "Profile1A:E2E CRC (SAE J1850 CRC-8) for 8 Bytes
DataID:Reserved";
CM_ SG_ 770 ADS_RollgCntr5_302h "Profile1A:E2E Rolling message counter(the maximum value of Alive counter is 14)";
CM_ SG_ 770 ADS_Resd5_302h "Profile1A:E2E Reserved";
CM_ SG_ 770 ADS_ParkRelPos1_y3_302h "目标车位相对位置1_y3(-50.0~50.0m)";
CM_ SG_ 770 ADS_ParkRelPos1_x4_302h "目标车位相对位置1_x4(-50.0~50.0m)";
CM_ SG_ 770 ADS_ParkRelPos1_y4_302h "目标车位相对位置1_y4(-50.0~50.0m)";
CM_ SG_ 770 ADS_ParkPosn2_ID_302h "车位2_ID号(0~15)";
CM_ SG_ 770 ADS_ParkRelPos2_x1_302h "目标车位相对位置2_x1(-50.0~50.0m)";
CM_ SG_ 770 ADS_CRC6_302h "Profile1A:E2E CRC (SAE J1850 CRC-8) for 8 Bytes
DataID:Reserved";
CM_ SG_ 770 ADS_RollgCntr6_302h "Profile1A:E2E Rolling message counter(the maximum value of Alive counter is 14)";
CM_ SG_ 770 ADS_Resd6_302h "Profile1A:E2E Reserved";
CM_ SG_ 770 ADS_ParkRelPos2_y1_302h "目标车位相对位置2_y1(-50.0~50.0m)";
CM_ SG_ 770 ADS_ParkRelPos2_x2_302h "目标车位相对位置2_x2(-50.0~50.0m)";
CM_ SG_ 770 ADS_ParkRelPos2_y2_302h "目标车位相对位置2_y2(-50.0~50.0m)";
CM_ SG_ 770 ADS_ParkRelPos2_x3_302h "目标车位相对位置2_x3(-50.0~50.0m)";
CM_ SG_ 770 ADS_TarParkSt_Posn2_302h "目标车位2的状态";
CM_ SG_ 770 ADS_ParkChkSrc_Posn2_302h "目标车位2检测来源";
CM_ SG_ 770 ADS_CRC7_302h "Profile1A:E2E CRC (SAE J1850 CRC-8) for 8 Bytes
DataID:Reserved";
CM_ SG_ 770 ADS_RollgCntr7_302h "Profile1A:E2E Rolling message counter(the maximum value of Alive counter is 14)";
CM_ SG_ 770 ADS_Resd7_302h "Profile1A:E2E Reserved";
CM_ SG_ 770 ADS_ParkRelPos2_y3_302h "目标车位相对位置2_y3(-50.0~50.0m)";
CM_ SG_ 770 ADS_ParkRelPos2_x4_302h "目标车位相对位置2_x4(-50.0~50.0m)";
CM_ SG_ 770 ADS_ParkRelPos2_y4_302h "目标车位相对位置2_y4(-50.0~50.0m)";
CM_ SG_ 514 ADS_CRC1_202h "Profile1A:E2E CRC (SAE J1850 CRC-8) for 8 Bytes
DataID:Reserved";
CM_ SG_ 514 ADS_RollgCntr1_202h "Profile1A:E2E Rolling message counter(the maximum value of Alive counter is 14)";
CM_ SG_ 514 ADS_Resd1_202h "Profile1A:E2E Reserved";
CM_ SG_ 514 ADS_AdsFault_202h "ADS系统故障";
CM_ SG_ 514 ADS_NicaReminderLEDVisual_202h "ADS功能接告警灯提醒";
CM_ SG_ 514 ADS_NicaReminderAcoustic_202h "ADS功能告警声音提醒";
CM_ SG_ 514 ADS_TakeoverID_202h "ADS功能接管提醒ID";
CM_ SG_ 514 ADS_TakeoverLevel_202h "TORLevel";
CM_ SG_ 514 ADS_TakeoverType_202h "TORType";
CM_ SG_ 514 ADS_TORIDCorrespErrorID_202h "TOR对应的error code ID";
CM_ SG_ 514 ADS_CRC2_202h "Profile1A:E2E CRC (SAE J1850 CRC-8) for 8 Bytes
DataID:Reserved";
CM_ SG_ 514 ADS_RollgCntr2_202h "Profile1A:E2E Rolling message counter(the maximum value of Alive counter is 14)";
CM_ SG_ 514 ADS_Resd2_202h "Profile1A:E2E Reserved";
CM_ SG_ 514 ADS_TakeoverExtended16bit_202h "接管扩展字段(如：弹窗内数值显示)";
CM_ SG_ 514 ADS_TakeoverExtended8bit_202h "接管扩展字段(如：功能激活失败)";
CM_ SG_ 1041 ADS_CRC1_411h "Profile1A:E2E CRC (SAE J1850 CRC-8) for 8 Bytes
DataID:Reserved";
CM_ SG_ 1041 ADS_RollgCntr1_411h "Profile1A:E2E Rolling message counter(the maximum value of Alive counter is 14)";
CM_ SG_ 1041 ADS_Resd1_411h "Profile1A:E2E Reserved";
CM_ SG_ 1041 ADS_RadarWarning0Distance_411h "雷达告警扇区与障碍物距离";
CM_ SG_ 1041 ADS_RadarWarning1Distance_411h "雷达告警扇区与障碍物距离";
CM_ SG_ 1041 ADS_RadarWarning2Distance_411h "雷达告警扇区与障碍物距离";
CM_ SG_ 1041 ADS_RadarWarning3Distance_411h "雷达告警扇区与障碍物距离";
CM_ SG_ 1041 ADS_RadarWarning4Distance_411h "雷达告警扇区与障碍物距离";
CM_ SG_ 1041 ADS_RadarWarning5Distance_411h "雷达告警扇区与障碍物距离";
CM_ SG_ 1041 ADS_CRC2_411h "Profile1A:E2E CRC (SAE J1850 CRC-8) for 8 Bytes
DataID:Reserved";
CM_ SG_ 1041 ADS_RollgCntr2_411h "Profile1A:E2E Rolling message counter(the maximum value of Alive counter is 14)";
CM_ SG_ 1041 ADS_Resd2_411h "Profile1A:E2E Reserved";
CM_ SG_ 1041 ADS_RadarWarning6Distance_411h "雷达告警扇区与障碍物距离";
CM_ SG_ 1041 ADS_RadarWarning7Distance_411h "雷达告警扇区与障碍物距离";
CM_ SG_ 1041 ADS_RadarWarning8Distance_411h "雷达告警扇区与障碍物距离";
CM_ SG_ 1041 ADS_RadarWarning9Distance_411h "雷达告警扇区与障碍物距离";
CM_ SG_ 1041 ADS_RadarWarning10Distance_411h "雷达告警扇区与障碍物距离";
CM_ SG_ 1041 ADS_RadarWarning11Distance_411h "雷达告警扇区与障碍物距离";
CM_ SG_ 1041 ADS_CRC3_411h "Profile1A:E2E CRC (SAE J1850 CRC-8) for 8 Bytes
DataID:Reserved";
CM_ SG_ 1041 ADS_RollgCntr3_411h "Profile1A:E2E Rolling message counter(the maximum value of Alive counter is 14)";
CM_ SG_ 1041 ADS_Resd3_411h "Profile1A:E2E Reserved";
CM_ SG_ 1041 ADS_RadarWarning12Distance_411h "雷达告警扇区与障碍物距离";
CM_ SG_ 1041 ADS_RadarWarning13Distance_411h "雷达告警扇区与障碍物距离";
CM_ SG_ 1041 ADS_RadarWarning14Distance_411h "雷达告警扇区与障碍物距离";
CM_ SG_ 1041 ADS_RadarWarning15Distance_411h "雷达告警扇区与障碍物距离";
CM_ SG_ 1041 ADS_RadarWarning0AcLvl_411h "雷达告警扇区与障碍物声音报警等级";
CM_ SG_ 1041 ADS_RadarWarning1AcLvl_411h "雷达告警扇区与障碍物声音报警等级";
CM_ SG_ 1041 ADS_RadarWarning2AcLvl_411h "雷达告警扇区与障碍物声音报警等级";
CM_ SG_ 1041 ADS_RadarWarning3AcLvl_411h "雷达告警扇区与障碍物声音报警等级";
CM_ SG_ 1041 ADS_RadarWarning4AcLvl_411h "雷达告警扇区与障碍物声音报警等级";
CM_ SG_ 1041 ADS_CRC4_411h "Profile1A:E2E CRC (SAE J1850 CRC-8) for 8 Bytes
DataID:Reserved";
CM_ SG_ 1041 ADS_RollgCntr4_411h "Profile1A:E2E Rolling message counter(the maximum value of Alive counter is 14)";
CM_ SG_ 1041 ADS_Resd4_411h "Profile1A:E2E Reserved";
CM_ SG_ 1041 ADS_RadarWarning5AcLvl_411h "雷达告警扇区与障碍物声音报警等级";
CM_ SG_ 1041 ADS_RadarWarning6AcLvl_411h "雷达告警扇区与障碍物声音报警等级";
CM_ SG_ 1041 ADS_RadarWarning7AcLvl_411h "雷达告警扇区与障碍物声音报警等级";
CM_ SG_ 1041 ADS_RadarWarning8AcLvl_411h "雷达告警扇区与障碍物声音报警等级";
CM_ SG_ 1041 ADS_RadarWarning9AcLvl_411h "雷达告警扇区与障碍物声音报警等级";
CM_ SG_ 1041 ADS_RadarWarning10AcLvl_411h "雷达告警扇区与障碍物声音报警等级";
CM_ SG_ 1041 ADS_RadarWarning11AcLvl_411h "雷达告警扇区与障碍物声音报警等级";
CM_ SG_ 1041 ADS_RadarWarning12AcLvl_411h "雷达告警扇区与障碍物声音报警等级";
CM_ SG_ 1041 ADS_RadarWarning13AcLvl_411h "雷达告警扇区与障碍物声音报警等级";
CM_ SG_ 1041 ADS_RadarWarning14AcLvl_411h "雷达告警扇区与障碍物声音报警等级";
CM_ SG_ 1041 ADS_RadarWarning15AcLvl_411h "雷达告警扇区与障碍物声音报警等级";
CM_ SG_ 1041 ADC_FuncReq_SentryModWarn_411h "ADS哨兵模式告警唤醒功能报文";
CM_ SG_ 1041 ADC_FuncReq_SentryModDetec_411h "哨兵模式功能维持信号";
CM_ SG_ 1041 ADC_MdcSentryAlarmMod_411h "ADS哨兵模式警告";
CM_ SG_ 769 ADS_CRC1_301h "Profile1A:E2E CRC (SAE J1850 CRC-8) for 8 Bytes
DataID:Reserved";
CM_ SG_ 769 ADS_RollgCntr1_301h "Profile1A:E2E Rolling message counter(the maximum value of Alive counter is 14)";
CM_ SG_ 769 ADS_Resd1_301h "Profile1A:E2E Reserved";
CM_ SG_ 769 ADS_AccFunctionStatus_301h "ACC功能状态机";
CM_ SG_ 769 ADS_LccNcaFunctionStatus_301h "LCC和NCA的功能状态机";
CM_ SG_ 769 ADS_AdsFucntionNotActive_301h "ADS无法激活";
CM_ SG_ 769 ADS_AvpFunctionStatus_301h "AVP的功能状态机";
CM_ SG_ 769 ADS_SpeedSetByDriver_301h "ADS 智驾定速值";
CM_ SG_ 769 ADS_SpeedLimitValue_301h "ADS 道路限速值";
CM_ SG_ 769 ADS_SpeedAutoFollow_301h "智能限速状态";
CM_ SG_ 769 ADS_OneTouchSpeedAdjustment_301h "非智能限速一键调速";
CM_ SG_ 769 ADS_CalibState_301h "标定状态";
CM_ SG_ 769 ADS_HODReminder_301h "脱手提醒";
CM_ SG_ 769 ADS_CRC2_301h "Profile1A:E2E CRC (SAE J1850 CRC-8) for 8 Bytes
DataID:Reserved";
CM_ SG_ 769 ADS_RollgCntr2_301h "Profile1A:E2E Rolling message counter(the maximum value of Alive counter is 14)";
CM_ SG_ 769 ADS_Resd2_301h "Profile1A:E2E Reserved";
CM_ SG_ 769 ADS_DMSReminder_301h "DIL提醒";
CM_ SG_ 769 ADS_FcwWaning_301h "FCW告警";
CM_ SG_ 769 ADS_FcwFault_301h "FCW故障";
CM_ SG_ 769 ADS_AebWaning_301h "AEB告警";
CM_ SG_ 769 ADS_AebFault_301h "AEB故障";
CM_ SG_ 769 ADS_AebObjType_301h "AEB触发障碍物类型";
CM_ SG_ 769 ADS_RaebWarning_301h "RAEB告警";
CM_ SG_ 769 ADS_RaebFault_301h "RAEB故障";
CM_ SG_ 769 ADS_RcwWarning_301h "RCW告警";
CM_ SG_ 769 ADS_RcwFault_301h "RCW故障";
CM_ SG_ 769 ADS_FctaLeftWarning_301h "左FCTA告警";
CM_ SG_ 769 ADS_FctaRightWarning_301h "右FCTA告警";
CM_ SG_ 769 ADS_FctbLeftWarning_301h "左FCTB告警";
CM_ SG_ 769 ADS_FctbRightWarning_301h "右FCTB告警";
CM_ SG_ 769 ADS_RctaLeftWarning_301h "左RCTA告警";
CM_ SG_ 769 ADS_RctaRightWarning_301h "右RCTA告警";
CM_ SG_ 769 ADS_RctaFault_301h "RCTA故障";
CM_ SG_ 769 ADS_CRC3_301h "Profile1A:E2E CRC (SAE J1850 CRC-8) for 8 Bytes
DataID:Reserved";
CM_ SG_ 769 ADS_RollgCntr3_301h "Profile1A:E2E Rolling message counter(the maximum value of Alive counter is 14)";
CM_ SG_ 769 ADS_Resd3_301h "Profile1A:E2E Reserved";
CM_ SG_ 769 ADS_RctbLeftWarning_301h "左RCTB告警";
CM_ SG_ 769 ADS_RctbRightWarning_301h "右RCTB告警";
CM_ SG_ 769 ADS_LdwWarning_301h "LDW告警";
CM_ SG_ 769 ADS_LdwFault_301h "LDW故障";
CM_ SG_ 769 ADS_LKAWarning_301h "LKA告警";
CM_ SG_ 769 ADS_LkaFault_301h "LKA故障";
CM_ SG_ 769 ADS_LeftMirrWarningCmd_301h "左BSD告警";
CM_ SG_ 769 ADS_RightMirrWarningCmd_301h "右BSD告警";
CM_ SG_ 769 ADS_BsdFault_301h "BSD故障";
CM_ SG_ 769 ADS_LeFrntDoorWarningCmd_301h "左前门的告警";
CM_ SG_ 769 ADS_LeReDoorWarningCmd_301h "左后门的告警";
CM_ SG_ 769 ADS_RiFrntDoorWarningCmd_301h "右前门的告警";
CM_ SG_ 769 ADS_RiReDoorWarningCmd_301h "右后门的告警";
CM_ SG_ 769 ADS_DowFault_301h "DOW故障";
CM_ SG_ 769 ADS_SpeedLimitWarning_301h "超速告警";
CM_ SG_ 769 ADS_TsrFault_301h "TSR故障";
CM_ SG_ 769 ADS_TlaFault_301h "TLA故障";
CM_ SG_ 769 ADS_ElkaFault_301h "ELKA故障";
CM_ SG_ 769 ADS_CRC4_301h "Profile1A:E2E CRC (SAE J1850 CRC-8) for 8 Bytes
DataID:Reserved";
CM_ SG_ 769 ADS_RollgCntr4_301h "Profile1A:E2E Rolling message counter(the maximum value of Alive counter is 14)";
CM_ SG_ 769 ADS_Resd4_301h "Profile1A:E2E Reserved";
CM_ SG_ 769 ADS_AbsoultwSpeedLimit_301h "设定的绝对限速值";
CM_ SG_ 769 ADS_TlaWarning_301h "TLA告警";
CM_ SG_ 769 ADS_ElkaWarning_301h "ELKA告警";
CM_ SG_ 1042 ADS_CRC1_412h "Profile1A:E2E CRC (SAE J1850 CRC-8) for 8 Bytes
DataID:Reserved";
CM_ SG_ 1042 ADS_RollgCntr1_412h "Profile1A:E2E Rolling message counter(the maximum value of Alive counter is 14)";
CM_ SG_ 1042 ADS_Resd1_412h "Profile1A:E2E Reserved";
CM_ SG_ 1042 ADS_BrkBeamReq_412h "刹车灯开启请求";
CM_ SG_ 1042 ADS_AutoLightSwCtrl_412h "自动灯光控制（Auto）";
CM_ SG_ 1042 ADS_LeFrntDowWarning_412h "左前门氛围灯报警";
CM_ SG_ 1042 ADS_RiFrntDowWarning_412h "右前门氛围灯报警";
CM_ SG_ 1042 ADS_LeReDowWarning_412h "左后门氛围灯报警";
CM_ SG_ 1042 ADS_RiReDowWarning_412h "右后门氛围灯报警";
CM_ SG_ 1042 ADS_LeftMirrWarningCmd_412h "左后视镜告警请求";
CM_ SG_ 1042 ADS_RightMirrWarningCmd_412h "右后视镜告警请求";
CM_ SG_ 1042 ADS_ReMirrReq_412h "后视镜控制请求";
CM_ SG_ 1042 ADS_DoorLockReq_412h "车门解闭锁控制请求";
CM_ SG_ 1042 ADS_SBeltControl_412h "主动安全带控制";
CM_ SG_ 1042 ADS_WshrReq_412h "洗涤点动开启请求";
CM_ SG_ 1042 ADS_SeatShakeControl_412h "座椅震动提示";
CM_ SG_ 1042 ADS_FrtWindshildHeatReq_412h "前风挡加热丝控制请求";
CM_ SG_ 1042 ADS_HornReq_412h "喇叭开启请求";
CM_ SG_ 1042 ADS_LeFmtWinCtrl_412h "驾驶员侧车窗控制";
CM_ SG_ 1042 ADS_RiFmtWinCtrl_412h "副驾驶员侧车窗控制";
CM_ SG_ 1042 ADS_LeReWinCtrl_412h "左后侧车窗控制";
CM_ SG_ 1042 ADS_RiReWinCtrl_412h "右后侧车窗控制";
CM_ SG_ 1042 ADS_TopWinCtrl_412h "天窗控制（若有）";
CM_ SG_ 1042 ADS_FrontWiperReq_412h "雨刮开启请求";
CM_ SG_ 1042 ADS_ChargingPortCmd_412h "充电口控制";
CM_ SG_ 1042 ADAS_FctSts_412h "智驾功能状态";
CM_ SG_ 1042 ADS_MdcCrtSts_412h "MDC工作状态";
CM_ SG_ 1042 ADS_CRC2_412h "Profile1A:E2E CRC (SAE J1850 CRC-8) for 8 Bytes
DataID:Reserved";
CM_ SG_ 1042 ADS_RollgCntr2_412h "Profile1A:E2E Rolling message counter(the maximum value of Alive counter is 14)";
CM_ SG_ 1042 ADS_Resd2_412h "Profile1A:E2E Reserved";
CM_ SG_ 1042 ADS_HVCtrlReq_412h "MDC请求高压";
CM_ SG_ 1042 ADS_ThmPostRun_412h "MDC液冷需求";
CM_ SG_ 1042 ADS_FlowReq_412h "MDC冷却液流速请求（百分比或枚举如下）";
CM_ SG_ 1042 ADS_PwrOnOffReq_412h "整车上下电控制请求
泊车上下电和上下Ready";
CM_ SG_ 1042 ADS_hmaOnOffSts_412h "智能大灯辅助(HMA)功能开启/关闭状态信号";
CM_ SG_ 1042 ADS_HMAStatus_412h "智能远光灯状态";
CM_ SG_ 1042 ADS_HiBeamReq_412h "HMA远光灯控制请求";
CM_ SG_ 290 EPS_1_CRC "Profile1A:E2E CRC (SAE J1850 CRC-8) for 8 Bytes
DataID:0x002E";
CM_ SG_ 290 EPS_1_RollgCntr "Profile1A:E2E Rolling message counter(the maximum value of Alive counter is 14)";
CM_ SG_ 290 EPSFailSts "EPS Fail Status";
CM_ SG_ 290 EPSSteeringAngleCalibrationSts "EPS Steering Angle Calibration Status";
CM_ SG_ 290 EPS_EOTLearning_Sts "Indicates the status of EPS EOT(end of travel) learning, displayed on the DMC(ICM)";
CM_ SG_ 1046 LBMS_LoWSocFlt "SOC过低故障(同时也是电量告警整车的标志)";
CM_ SG_ 1046 LBMS_ThermRunawayFlt "热失控故障";
CM_ SG_ 1046 LBMS_SysFlt "低压电池故障状态";
CM_ SG_ 1046 LBMS_LowPowerRemind "锁电信号提示";
CM_ SG_ 1046 LBMS_EndLifeFlt "锂电池寿命终结信号，SOH≤70%置为1";
BA_DEF_ BO_  "GenMsgCycleTimeFast" INT 0 50000;
BA_DEF_ BO_  "GenMsgNrOfRepetition" INT 0 999999;
BA_DEF_ BO_  "GenMsgDelayTime" INT 0 1000;
BA_DEF_ BO_  "VFrameFormat" ENUM  "StandardCAN","ExtendedCAN","reserved","reserved","reserved","reserved","reserved","reserved","reserved","reserved","reserved","reserved","reserved","reserved","StandardCAN_FD","ExtendedCAN_FD";
BA_DEF_ BO_  "GenMsgILSupport" ENUM  "No","Yes";
BA_DEF_ BO_  "NmMessage" ENUM  "No","Yes";
BA_DEF_ BO_  "GenMsgSendType" ENUM  "Cycle","Event","IfActive","CE","CA","NoMsgSendType";
BA_DEF_ BO_  "GenMsgCycleTime" INT 0 50000;
BA_DEF_ BO_  "CANFD_BRS" INT 0 1;
BA_DEF_ BO_  "NmAsrMessage" ENUM  "No","Yes";
BA_DEF_ BO_  "GRC_ASIL" ENUM  "vector_leerstring","QM","A","B","C","D";
BA_DEF_ BO_  "GRC_History" STRING ;
BA_DEF_ SG_  "GenSigStartValue" FLOAT 0 100000000000;
BA_DEF_ SG_  "GenSigInactiveValue" INT 0 100000;
BA_DEF_ SG_  "GenSigInvalidValue" INT 0 100000000;
BA_DEF_ SG_  "GenSigSendType" ENUM  "Cycle","OnChange","OnWrite","IfActive","OnChangeWithRepetition","OnWriteWithRepetition","IfActiveWithRepetition","NoSigSendType","OnChangeAndIfActive","OnChangeAndIfActiveWithRepetition","CA","CE","Event";
BA_DEF_ SG_  "GRC_Sig_ASIL" ENUM  "vector_leerstring","QM","A","B","C","D";
BA_DEF_ SG_  "E2EDataId" INT 0 0;
BA_DEF_ SG_  "E2EProfile" STRING ;
BA_DEF_ SG_  "E2EDataLength" INT 0 512;
BA_DEF_DEF_  "GenMsgCycleTimeFast" 0;
BA_DEF_DEF_  "GenMsgNrOfRepetition" 0;
BA_DEF_DEF_  "GenMsgDelayTime" 0;
BA_DEF_DEF_  "VFrameFormat" "StandardCAN";
BA_DEF_DEF_  "GenMsgILSupport" "No";
BA_DEF_DEF_  "NmMessage" "No";
BA_DEF_DEF_  "GenMsgSendType" "NoMsgSendType";
BA_DEF_DEF_  "GenMsgCycleTime" 0;
BA_DEF_DEF_  "CANFD_BRS" 0;
BA_DEF_DEF_  "NmAsrMessage" "No";
BA_DEF_DEF_  "GRC_ASIL" "";
BA_DEF_DEF_  "GRC_History" "";
BA_DEF_DEF_  "GenSigStartValue" 0;
BA_DEF_DEF_  "GenSigInactiveValue" 0;
BA_DEF_DEF_  "GenSigInvalidValue" 0;
BA_DEF_DEF_  "GenSigSendType" "NoSigSendType";
BA_DEF_DEF_  "GRC_Sig_ASIL" "";
BA_DEF_DEF_  "E2EDataId" 0;
BA_DEF_DEF_  "E2EProfile" "";
BA_DEF_DEF_  "E2EDataLength" 0;
BA_ "CANFD_BRS" BO_ 1096 1;
BA_ "GenMsgSendType" BO_ 1096 0;
BA_ "GenMsgCycleTime" BO_ 1096 100;
BA_ "GenMsgILSupport" BO_ 1096 1;
BA_ "GRC_History" BO_ 1096 "[{'approvedBy':'贾少辉','author':'吴慧','changesComments':'新增3个信号TMS_AutoDefogActiveSts、TMS_CFSCycleLevel、TMS_TimingLevel，ICC接收','date':'2025/1/18','ecu':'TMS_11(0x448)','ecuName':'ICC','reviewedBy':'杨华','revision':'V1.0'},{'approvedBy':'贾少";
BA_ "VFrameFormat" BO_ 1096 14;
BA_ "CANFD_BRS" BO_ 1240 1;
BA_ "GenMsgSendType" BO_ 1240 0;
BA_ "GenMsgCycleTime" BO_ 1240 100;
BA_ "GenMsgILSupport" BO_ 1240 1;
BA_ "GRC_History" BO_ 1240 "[{'approvedBy':'贾少辉','author':'吴慧','changesComments':'史文妍GL网段-根据热管理TMS马澳需求FRZCU/TMS新增7个信号给ICC接收:\nTMS_AQSCOSts_2、TMS_AQSNO2Sts_2、TMS_AQSN02SnsrSts_2、TMS_AQSLifeCntr_2、TMS_AQSErrSts_2、TMS_AQSErrRespAQSM_2、TMS_AQSAirQlySts_";
BA_ "VFrameFormat" BO_ 1240 14;
BA_ "CANFD_BRS" BO_ 638 1;
BA_ "GenMsgSendType" BO_ 638 0;
BA_ "GenMsgCycleTime" BO_ 638 20;
BA_ "GenMsgILSupport" BO_ 638 1;
BA_ "VFrameFormat" BO_ 638 14;
BA_ "CANFD_BRS" BO_ 949 1;
BA_ "GenMsgSendType" BO_ 949 3;
BA_ "GenMsgCycleTime" BO_ 949 50;
BA_ "GenMsgCycleTimeFast" BO_ 949 50;
BA_ "GenMsgNrOfRepetition" BO_ 949 3;
BA_ "GenMsgDelayTime" BO_ 949 5;
BA_ "GenMsgILSupport" BO_ 949 1;
BA_ "VFrameFormat" BO_ 949 14;
BA_ "CANFD_BRS" BO_ 1028 1;
BA_ "GenMsgSendType" BO_ 1028 3;
BA_ "GenMsgCycleTime" BO_ 1028 100;
BA_ "GenMsgCycleTimeFast" BO_ 1028 50;
BA_ "GenMsgNrOfRepetition" BO_ 1028 3;
BA_ "GenMsgDelayTime" BO_ 1028 5;
BA_ "GenMsgILSupport" BO_ 1028 1;
BA_ "VFrameFormat" BO_ 1028 14;
BA_ "CANFD_BRS" BO_ 1291 1;
BA_ "GenMsgSendType" BO_ 1291 0;
BA_ "GenMsgCycleTime" BO_ 1291 500;
BA_ "GenMsgILSupport" BO_ 1291 1;
BA_ "VFrameFormat" BO_ 1291 14;
BA_ "CANFD_BRS" BO_ 587 1;
BA_ "GenMsgSendType" BO_ 587 0;
BA_ "GenMsgCycleTime" BO_ 587 20;
BA_ "GenMsgILSupport" BO_ 587 1;
BA_ "GRC_ASIL" BO_ 587 5;
BA_ "VFrameFormat" BO_ 587 14;
BA_ "CANFD_BRS" BO_ 1338 1;
BA_ "GenMsgSendType" BO_ 1338 0;
BA_ "GenMsgCycleTime" BO_ 1338 500;
BA_ "GenMsgILSupport" BO_ 1338 1;
BA_ "GRC_History" BO_ 1338 "[{'approvedBy':'贾少辉','author':'吴慧','changesComments':'冯夏新PT网段-FMCU新增发送FMCU_1_G_ISGMotWorkState信号，无接收','date':'2025/3/7','ecu':'FMCU_1_G(0x53A)','ecuName':'CGW','reviewedBy':'杨华','revision':'V1.1'}]";
BA_ "VFrameFormat" BO_ 1338 14;
BA_ "CANFD_BRS" BO_ 777 1;
BA_ "GenMsgSendType" BO_ 777 0;
BA_ "GenMsgCycleTime" BO_ 777 50;
BA_ "GenMsgILSupport" BO_ 777 1;
BA_ "VFrameFormat" BO_ 777 14;
BA_ "CANFD_BRS" BO_ 1403 1;
BA_ "GenMsgSendType" BO_ 1403 0;
BA_ "GenMsgCycleTime" BO_ 1403 500;
BA_ "GenMsgILSupport" BO_ 1403 1;
BA_ "VFrameFormat" BO_ 1403 14;
BA_ "CANFD_BRS" BO_ 1299 1;
BA_ "GenMsgSendType" BO_ 1299 0;
BA_ "GenMsgCycleTime" BO_ 1299 500;
BA_ "GenMsgILSupport" BO_ 1299 1;
BA_ "VFrameFormat" BO_ 1299 14;
BA_ "CANFD_BRS" BO_ 1099 1;
BA_ "GenMsgSendType" BO_ 1099 0;
BA_ "GenMsgCycleTime" BO_ 1099 100;
BA_ "GenMsgILSupport" BO_ 1099 1;
BA_ "GRC_History" BO_ 1099 "[{'approvedBy':'贾少辉','author':'吴慧','changesComments':'（同步D01更改）冯夏欣PT网段更新部分信号的备注，\n以及ISGF_SysTempOvrInd和ISGF_HVILFault（捷途D01不使用）','date':'2025/4/7','ecu':'ISGF_4(0x44B)','ecuName':'ICC','reviewedBy':'杨华','revision':'V";
BA_ "VFrameFormat" BO_ 1099 14;
BA_ "CANFD_BRS" BO_ 1130 1;
BA_ "GenMsgSendType" BO_ 1130 0;
BA_ "GenMsgCycleTime" BO_ 1130 100;
BA_ "GenMsgILSupport" BO_ 1130 1;
BA_ "GRC_History" BO_ 1130 "[{'approvedBy':'贾少辉','author':'吴慧','changesComments':'1、TCU修改TCU_23_ErrLever枚举值，新增0x5\n2、TCU新增信号TCU_23_GBWarmUpReq，TCU_23_STAT_LeverModeDisp，TCU_23_CluSelfLrng','date':'2025/1/18','ecu':'TCU_23(0x46A)','ecuName':'CGW','reviewedBy':'�";
BA_ "VFrameFormat" BO_ 1130 14;
BA_ "CANFD_BRS" BO_ 1180 1;
BA_ "GenMsgSendType" BO_ 1180 0;
BA_ "GenMsgCycleTime" BO_ 1180 100;
BA_ "GenMsgILSupport" BO_ 1180 1;
BA_ "VFrameFormat" BO_ 1180 14;
BA_ "CANFD_BRS" BO_ 1248 1;
BA_ "GenMsgSendType" BO_ 1248 3;
BA_ "GenMsgCycleTime" BO_ 1248 100;
BA_ "GenMsgCycleTimeFast" BO_ 1248 10;
BA_ "GenMsgNrOfRepetition" BO_ 1248 5;
BA_ "GenMsgDelayTime" BO_ 1248 5;
BA_ "GenMsgILSupport" BO_ 1248 1;
BA_ "GRC_History" BO_ 1248 "[{'approvedBy':'贾少辉','author':'吴慧','changesComments':'（同步D01更改）同步GL网段：与电子电器FRZCU、FLZCU丁阁文确定\n新增2个信号FRZCU_SSB1Sts、FRZCU_SSB2Sts，无接收端','date':'2025/3/5','ecu':'FRZCU_TO_FLZCU(0x4E0)','ecuName':'CGW','reviewedBy':'杨华'";
BA_ "VFrameFormat" BO_ 1248 14;
BA_ "CANFD_BRS" BO_ 1341 1;
BA_ "GenMsgSendType" BO_ 1341 0;
BA_ "GenMsgCycleTime" BO_ 1341 100;
BA_ "GenMsgILSupport" BO_ 1341 1;
BA_ "VFrameFormat" BO_ 1341 14;
BA_ "CANFD_BRS" BO_ 811 1;
BA_ "GenMsgSendType" BO_ 811 0;
BA_ "GenMsgCycleTime" BO_ 811 50;
BA_ "GenMsgILSupport" BO_ 811 1;
BA_ "VFrameFormat" BO_ 811 14;
BA_ "CANFD_BRS" BO_ 1427 1;
BA_ "GenMsgSendType" BO_ 1427 0;
BA_ "GenMsgCycleTime" BO_ 1427 100;
BA_ "GenMsgILSupport" BO_ 1427 1;
BA_ "GRC_History" BO_ 1427 "[{'approvedBy':'贾少辉','author':'吴慧','changesComments':'删除ILCF_1_LogoChargingSts和ILCF_1_DIYMusicShowModSts和ILCF_1_RandomMusicShowSts和ILCF_1_LogoColorAdjSts信号发送，ICC删除4条接收（刘胤翠）','date':'2025/1/20','ecu':'ILCF_1(0x593)','ecuName':'ICC";
BA_ "VFrameFormat" BO_ 1427 14;
BA_ "CANFD_BRS" BO_ 1172 1;
BA_ "GenMsgSendType" BO_ 1172 0;
BA_ "GenMsgCycleTime" BO_ 1172 100;
BA_ "GenMsgILSupport" BO_ 1172 1;
BA_ "VFrameFormat" BO_ 1172 14;
BA_ "CANFD_BRS" BO_ 1147 1;
BA_ "GenMsgSendType" BO_ 1147 3;
BA_ "GenMsgCycleTime" BO_ 1147 100;
BA_ "GenMsgCycleTimeFast" BO_ 1147 20;
BA_ "GenMsgNrOfRepetition" BO_ 1147 3;
BA_ "GenMsgDelayTime" BO_ 1147 5;
BA_ "GenMsgILSupport" BO_ 1147 1;
BA_ "GRC_History" BO_ 1147 "[{'approvedBy':'贾少辉','author':'吴慧','changesComments':'热管理EIPM齐静反馈CCP_1_FrontOFFSwitchReq、CCP_1_ACFastCool这2个信号EIPM不发送，故删除','date':'2025/1/18','ecu':'CCP_1(0x47B)','ecuName':'ICC','reviewedBy':'杨华','revision':'V1.0'}]";
BA_ "VFrameFormat" BO_ 1147 14;
BA_ "CANFD_BRS" BO_ 1107 1;
BA_ "GenMsgSendType" BO_ 1107 0;
BA_ "GenMsgCycleTime" BO_ 1107 100;
BA_ "GenMsgILSupport" BO_ 1107 1;
BA_ "GRC_History" BO_ 1107 "[{'approvedBy':'贾少辉','author':'吴慧','changesComments':'（同步D01更改）史文妍GL网段更新，根据与热管理TMS,UVC魏成贤、刘林森沟通：\n将TMS_UVC_WorkingBfSts名称更新为TMS_UVC_WorkingBfReq，信号描述更新为紫外线杀菌灯请求；TMS_UVC_LuminanceBfSts名称更新为TMS";
BA_ "VFrameFormat" BO_ 1107 14;
BA_ "CANFD_BRS" BO_ 1175 1;
BA_ "GenMsgSendType" BO_ 1175 3;
BA_ "GenMsgCycleTime" BO_ 1175 100;
BA_ "GenMsgCycleTimeFast" BO_ 1175 20;
BA_ "GenMsgNrOfRepetition" BO_ 1175 3;
BA_ "GenMsgDelayTime" BO_ 1175 5;
BA_ "GenMsgILSupport" BO_ 1175 1;
BA_ "GRC_History" BO_ 1175 "[{'approvedBy':'贾少辉','author':'吴慧','changesComments':'热管理EIPM齐静反馈CCP_2_ACFastHeat、CCP_2_FrontBlowSpdCtrlSwitchReq、FRCCP_DeputySetHeatReq、FRCCP_DeputySetVentilationReq这4个信号EIPM不发送，故删除','date':'2025/1/18','ecu':'CCP_2(0x497)','ecu";
BA_ "VFrameFormat" BO_ 1175 14;
BA_ "CANFD_BRS" BO_ 1292 1;
BA_ "GenMsgSendType" BO_ 1292 0;
BA_ "GenMsgCycleTime" BO_ 1292 500;
BA_ "GenMsgILSupport" BO_ 1292 1;
BA_ "VFrameFormat" BO_ 1292 14;
BA_ "CANFD_BRS" BO_ 1241 1;
BA_ "GenMsgSendType" BO_ 1241 0;
BA_ "GenMsgCycleTime" BO_ 1241 100;
BA_ "GenMsgILSupport" BO_ 1241 1;
BA_ "GRC_History" BO_ 1241 "[{'approvedBy':'贾少辉','author':'吴慧','changesComments':'（同步D01更改）冯夏欣EMS新增信号EMS_4_G_KL15Sts,无接收端','date':'2025/3/5','ecu':'EMS_4_G(0x4D9)','ecuName':'CGW','reviewedBy':'杨华','revision':'V1.1'}]";
BA_ "VFrameFormat" BO_ 1241 14;
BA_ "CANFD_BRS" BO_ 49 1;
BA_ "GenMsgSendType" BO_ 49 0;
BA_ "GenMsgCycleTime" BO_ 49 10;
BA_ "GenMsgILSupport" BO_ 49 1;
BA_ "VFrameFormat" BO_ 49 14;
BA_ "CANFD_BRS" BO_ 1024 1;
BA_ "GenMsgSendType" BO_ 1024 0;
BA_ "GenMsgCycleTime" BO_ 1024 100;
BA_ "GenMsgILSupport" BO_ 1024 1;
BA_ "GRC_History" BO_ 1024 "[{'approvedBy':'贾少辉','author':'吴慧','changesComments':'（同步D01更改）同步GL网段：电子电器丁阁文需求新增一个信号Antifault_UnlockReq，无接收','date':'2025/4/8','ecu':'FRZCU_13(0x400)','ecuName':'CGW','reviewedBy':'杨华','revision':'V1.2'}]";
BA_ "VFrameFormat" BO_ 1024 14;
BA_ "CANFD_BRS" BO_ 1182 1;
BA_ "GenMsgSendType" BO_ 1182 0;
BA_ "GenMsgCycleTime" BO_ 1182 100;
BA_ "GenMsgILSupport" BO_ 1182 1;
BA_ "VFrameFormat" BO_ 1182 14;
BA_ "CANFD_BRS" BO_ 513 1;
BA_ "GenMsgSendType" BO_ 513 0;
BA_ "GenMsgCycleTime" BO_ 513 20;
BA_ "GenMsgILSupport" BO_ 513 1;
BA_ "GRC_History" BO_ 513 "[{'approvedBy':'贾少辉','author':'吴慧','changesComments':'1、删除MFSL_AVM_SW和MFSL_Customize信号，ICC删除接收（刘胤翠）\n2、新增MFSL_APA_SW和MFSL_LCC_NCA_SW和MFSL_KeyReset_SW信号，ICC接收','date':'2025/1/19','ecu':'MFSL_1(0x201)','ecuName':'ICC','review";
BA_ "VFrameFormat" BO_ 513 14;
BA_ "CANFD_BRS" BO_ 1152 1;
BA_ "GenMsgSendType" BO_ 1152 1;
BA_ "GenMsgCycleTimeFast" BO_ 1152 100;
BA_ "GenMsgNrOfRepetition" BO_ 1152 3;
BA_ "GenMsgDelayTime" BO_ 1152 5;
BA_ "GenMsgILSupport" BO_ 1152 1;
BA_ "VFrameFormat" BO_ 1152 14;
BA_ "CANFD_BRS" BO_ 1164 1;
BA_ "GenMsgSendType" BO_ 1164 0;
BA_ "GenMsgCycleTime" BO_ 1164 100;
BA_ "GenMsgILSupport" BO_ 1164 1;
BA_ "VFrameFormat" BO_ 1164 14;
BA_ "GenMsgSendType" BO_ 789 1;
BA_ "GenMsgCycleTimeFast" BO_ 789 20;
BA_ "GenMsgNrOfRepetition" BO_ 789 3;
BA_ "GenMsgDelayTime" BO_ 789 5;
BA_ "GenMsgILSupport" BO_ 789 1;
BA_ "GRC_History" BO_ 789 "[{'approvedBy':'贾少辉','author':'吴慧','changesComments':'1、删除ATCM_FrontEDL和ATCM_ASU_LiftSet和ATCM_ASU_LowerSet信号，无接收端\n2、新增ATCM_ESP_OFF_SW和ATCM_AVH_SW和ATCM_AVM信号，ICC新增接收（刘胤翠）','date':'2025/1/19','ecu':'ATCM_1(0x315)','ecuNam";
BA_ "VFrameFormat" BO_ 789 14;
BA_ "CANFD_BRS" BO_ 1214 1;
BA_ "GenMsgSendType" BO_ 1214 1;
BA_ "GenMsgDelayTime" BO_ 1214 5;
BA_ "GenMsgILSupport" BO_ 1214 1;
BA_ "VFrameFormat" BO_ 1214 14;
BA_ "CANFD_BRS" BO_ 571 1;
BA_ "GenMsgSendType" BO_ 571 0;
BA_ "GenMsgCycleTime" BO_ 571 20;
BA_ "GenMsgILSupport" BO_ 571 1;
BA_ "VFrameFormat" BO_ 571 14;
BA_ "CANFD_BRS" BO_ 699 1;
BA_ "GenMsgSendType" BO_ 699 0;
BA_ "GenMsgCycleTime" BO_ 699 20;
BA_ "GenMsgILSupport" BO_ 699 1;
BA_ "VFrameFormat" BO_ 699 14;
BA_ "CANFD_BRS" BO_ 787 1;
BA_ "GenMsgSendType" BO_ 787 0;
BA_ "GenMsgCycleTime" BO_ 787 50;
BA_ "GenMsgILSupport" BO_ 787 1;
BA_ "GRC_ASIL" BO_ 787 3;
BA_ "VFrameFormat" BO_ 787 14;
BA_ "CANFD_BRS" BO_ 572 1;
BA_ "GenMsgSendType" BO_ 572 0;
BA_ "GenMsgCycleTime" BO_ 572 20;
BA_ "GenMsgILSupport" BO_ 572 1;
BA_ "GRC_History" BO_ 572 "[{'approvedBy':'贾少辉','author':'吴慧','changesComments':'（同步D01更改）同步CH网段：根据越野部王曦秀极限掉头和越野蠕行功能信号需求调整，\n1、ONEBOX_7_iCCO_TgtVel (iCCO功能目标车速)拓展到8bit，字节排布变动，精度修改为0.1，最大值20；ICC接收；\n2、ONEBOX_";
BA_ "VFrameFormat" BO_ 572 14;
BA_ "CANFD_BRS" BO_ 1212 1;
BA_ "GenMsgSendType" BO_ 1212 0;
BA_ "GenMsgCycleTime" BO_ 1212 100;
BA_ "GenMsgILSupport" BO_ 1212 1;
BA_ "VFrameFormat" BO_ 1212 14;
BA_ "CANFD_BRS" BO_ 1110 1;
BA_ "GenMsgSendType" BO_ 1110 1;
BA_ "GenMsgILSupport" BO_ 1110 1;
BA_ "VFrameFormat" BO_ 1110 14;
BA_ "CANFD_BRS" BO_ 1149 1;
BA_ "GenMsgSendType" BO_ 1149 1;
BA_ "GenMsgILSupport" BO_ 1149 1;
BA_ "VFrameFormat" BO_ 1149 14;
BA_ "CANFD_BRS" BO_ 1120 1;
BA_ "GenMsgSendType" BO_ 1120 0;
BA_ "GenMsgCycleTime" BO_ 1120 100;
BA_ "GenMsgILSupport" BO_ 1120 1;
BA_ "VFrameFormat" BO_ 1120 14;
BA_ "GenMsgSendType" BO_ 1199 0;
BA_ "GenMsgCycleTime" BO_ 1199 100;
BA_ "GenMsgILSupport" BO_ 1199 1;
BA_ "GRC_ASIL" BO_ 1199 3;
BA_ "VFrameFormat" BO_ 1199 14;
BA_ "CANFD_BRS" BO_ 770 1;
BA_ "GenMsgSendType" BO_ 770 0;
BA_ "GenMsgCycleTime" BO_ 770 50;
BA_ "GenMsgILSupport" BO_ 770 1;
BA_ "GRC_History" BO_ 770 "[{'approvedBy':'贾少辉','author':'吴慧','changesComments':'姜新ICC需求接收整帧报文，MDC华为智驾方案，新增DA-IC路由','date':'2025/1/19','ecu':'ADS_HW_302h(0x302)','ecuName':'ICC','reviewedBy':'杨华','revision':'V1.0'}]";
BA_ "VFrameFormat" BO_ 770 14;
BA_ "CANFD_BRS" BO_ 514 1;
BA_ "GenMsgSendType" BO_ 514 0;
BA_ "GenMsgCycleTime" BO_ 514 20;
BA_ "GenMsgILSupport" BO_ 514 1;
BA_ "GRC_History" BO_ 514 "[{'approvedBy':'贾少辉','author':'吴慧','changesComments':'姜新ICC需求接收整帧报文，MDC华为智驾方案，新增DA-IC路由','date':'2025/1/19','ecu':'ADS_HW_202h(0x202)','ecuName':'ICC','reviewedBy':'杨华','revision':'V1.0'}]";
BA_ "VFrameFormat" BO_ 514 14;
BA_ "CANFD_BRS" BO_ 1041 1;
BA_ "GenMsgSendType" BO_ 1041 0;
BA_ "GenMsgCycleTime" BO_ 1041 100;
BA_ "GenMsgILSupport" BO_ 1041 1;
BA_ "GRC_History" BO_ 1041 "[{'approvedBy':'贾少辉','author':'吴慧','changesComments':'姜新ICC需求接收整帧报文，MDC华为智驾方案，新增DA-IC路由','date':'2025/1/19','ecu':'ADS_HW_411h(0x411)','ecuName':'ICC','reviewedBy':'杨华','revision':'V1.0'}]";
BA_ "VFrameFormat" BO_ 1041 14;
BA_ "CANFD_BRS" BO_ 769 1;
BA_ "GenMsgSendType" BO_ 769 0;
BA_ "GenMsgCycleTime" BO_ 769 50;
BA_ "GenMsgILSupport" BO_ 769 1;
BA_ "GRC_History" BO_ 769 "[{'approvedBy':'贾少辉','author':'吴慧','changesComments':'姜新ICC需求接收整帧报文，MDC华为智驾方案，新增DA-IC路由','date':'2025/1/19','ecu':'ADS_HW_301h(0x301)','ecuName':'ICC','reviewedBy':'杨华','revision':'V1.0'}]";
BA_ "VFrameFormat" BO_ 769 14;
BA_ "CANFD_BRS" BO_ 1042 1;
BA_ "GenMsgSendType" BO_ 1042 0;
BA_ "GenMsgCycleTime" BO_ 1042 100;
BA_ "GenMsgILSupport" BO_ 1042 1;
BA_ "GRC_History" BO_ 1042 "[{'approvedBy':'贾少辉','author':'吴慧','changesComments':'姜新ICC需求接收整帧报文，MDC华为智驾方案，新增DA-IC路由','date':'2025/1/19','ecu':'ADS_HW_412h(0x412)','ecuName':'ICC','reviewedBy':'杨华','revision':'V1.0'},{'approvedBy':'贾少辉','author':'吴慧";
BA_ "VFrameFormat" BO_ 1042 14;
BA_ "CANFD_BRS" BO_ 290 1;
BA_ "GenMsgSendType" BO_ 290 0;
BA_ "GenMsgCycleTime" BO_ 290 10;
BA_ "GenMsgILSupport" BO_ 290 1;
BA_ "GRC_History" BO_ 290 "[{'approvedBy':'贾少辉','author':'吴慧','changesComments':'删除D01路由：EPS删除发送0x122，所以删除该ID报文，ICC删除接收','date':'2025/1/17','ecu':'EPS_1(0x122)','ecuName':'ICC','reviewedBy':'杨华','revision':'V1.0'},{'approvedBy':'贾少辉','author':'吴慧'";
BA_ "VFrameFormat" BO_ 290 14;
BA_ "CANFD_BRS" BO_ 1046 1;
BA_ "GenMsgSendType" BO_ 1046 0;
BA_ "GenMsgCycleTime" BO_ 1046 100;
BA_ "GenMsgILSupport" BO_ 1046 1;
BA_ "GRC_History" BO_ 1046 "[{'approvedBy':'贾少辉','author':'吴慧','changesComments':'新增EP-IC路由转发：王振兴需求ICC新增接收5条信号','date':'2025/4/15','ecu':'LBMS_SysSt4(0x416)','ecuName':'ICC','reviewedBy':'杨华','revision':'V1.2'}]";
BA_ "VFrameFormat" BO_ 1046 14;
BA_ "GenSigSendType" SG_ 1096 TMS_AirPurgeReminderSts 0;
BA_ "GenSigSendType" SG_ 1096 TMS_BT_Reduce_Wind_SpeedSts 0;
BA_ "GenSigSendType" SG_ 1096 TMS_First_BlowingSts 0;
BA_ "GenSigSendType" SG_ 1096 TMS_CirculationInTunnelsSts 0;
BA_ "GenSigSendType" SG_ 1096 TMS_crosscountry_coolingSts 0;
BA_ "GenSigSendType" SG_ 1096 TMS_ParkingAirConditioningStatus 0;
BA_ "GenSigSendType" SG_ 1096 TMS_CoolantFillSts 0;
BA_ "GenSigSendType" SG_ 1096 TMS_UVC_ControlSts 0;
BA_ "GenSigSendType" SG_ 1096 TMS_AutoDefogActiveSts 0;
BA_ "GenSigSendType" SG_ 1096 TMS_UVC_LuminanceSts 0;
BA_ "GenSigSendType" SG_ 1096 TMS_ICC_Lightoff_Sts 0;
BA_ "GenSigSendType" SG_ 1096 TMS_ICC_Memoff_Sts 0;
BA_ "GenSigSendType" SG_ 1096 TMS_keepwarmSet_TemperatureSts 0;
BA_ "GenSigSendType" SG_ 1096 TMS_CFSCycleLevel 0;
BA_ "GenSigSendType" SG_ 1096 TMS_TimingLevel 0;
BA_ "GenSigSendType" SG_ 1096 TMS_BiochemicalFuncSts 0;
BA_ "GenSigSendType" SG_ 1096 TMS_TimedVentilationSts 0;
BA_ "GenSigSendType" SG_ 1240 TMS_CFSSwitchFb 0;
BA_ "GenSigSendType" SG_ 1240 TDU_CFSPosOneType 0;
BA_ "GenSigStartValue" SG_ 1240 TDU_CFSPosOneType 15;
BA_ "GenSigSendType" SG_ 1240 TDU_CFSPosTwoType 0;
BA_ "GenSigStartValue" SG_ 1240 TDU_CFSPosTwoType 15;
BA_ "GenSigSendType" SG_ 1240 TDU_CFSPosThreeType 0;
BA_ "GenSigStartValue" SG_ 1240 TDU_CFSPosThreeType 15;
BA_ "GenSigSendType" SG_ 1240 TDU_CFSRunOut 0;
BA_ "GenSigStartValue" SG_ 1240 TDU_CFSRunOut 15;
BA_ "GenSigSendType" SG_ 1240 TMS_CFSShortWarn 0;
BA_ "GenSigStartValue" SG_ 1240 TMS_CFSShortWarn 15;
BA_ "GenSigSendType" SG_ 1240 TMS_CFSLevelSetFb 0;
BA_ "GenSigSendType" SG_ 1240 TMS_CFSPosSetFb 0;
BA_ "GenSigSendType" SG_ 1240 TMS_CFSPosOneLife 0;
BA_ "GenSigInvalidValue" SG_ 1240 TMS_CFSPosOneLife 255;
BA_ "GenSigSendType" SG_ 1240 TMS_CFSPosTwoLife 0;
BA_ "GenSigInvalidValue" SG_ 1240 TMS_CFSPosTwoLife 255;
BA_ "GenSigSendType" SG_ 1240 TMS_CFSPosThreeLife 0;
BA_ "GenSigInvalidValue" SG_ 1240 TMS_CFSPosThreeLife 255;
BA_ "GenSigSendType" SG_ 1240 TMS_PM25SwitchFb 0;
BA_ "GenSigSendType" SG_ 1240 TMS_AQSCOSts_2 0;
BA_ "GenSigSendType" SG_ 1240 TMS_AQSNO2Sts_2 0;
BA_ "GenSigSendType" SG_ 1240 TMS_AQSN02SnsrSts_2 0;
BA_ "GenSigSendType" SG_ 1240 TMS_AQSLifeCntr_2 0;
BA_ "GenSigSendType" SG_ 1240 TMS_AQSErrSts_2 0;
BA_ "GenSigStartValue" SG_ 1240 TMS_AQSErrSts_2 1;
BA_ "GenSigSendType" SG_ 1240 TMS_AQSErrRespAQSM_2 0;
BA_ "GenSigSendType" SG_ 1240 TMS_AQSAirQlySts_2 0;
BA_ "GenSigInvalidValue" SG_ 1240 TMS_AQSAirQlySts_2 4;
BA_ "GenSigSendType" SG_ 1240 TMS_ThrModeStsFb 0;
BA_ "GenSigStartValue" SG_ 1240 TMS_ThrModeStsFb 7;
BA_ "GenSigSendType" SG_ 1240 TMS_ThrSetTempFb_C 0;
BA_ "GenSigInvalidValue" SG_ 1240 TMS_ThrSetTempFb_C 31;
BA_ "GenSigStartValue" SG_ 1240 TMS_ThrSetTempFb_C 31;
BA_ "GenSigSendType" SG_ 1240 TMS_ThrCLMSwitchFb 0;
BA_ "GenSigSendType" SG_ 1240 TMS_ThrAutoSwitchFb 0;
BA_ "GenSigSendType" SG_ 1240 TMS_ThrBlowSpeedLevelKeyStsFb 0;
BA_ "GenSigSendType" SG_ 638 FRZCU_HoodSts 0;
BA_ "GenSigSendType" SG_ 638 FRZCU_AuthenResult 0;
BA_ "GenSigSendType" SG_ 638 FRZCU_PowerMode 0;
BA_ "GenSigSendType" SG_ 638 FRZCU_TrunkSts 0;
BA_ "GenSigSendType" SG_ 638 FRZCU_HandleSwitchStsFL 0;
BA_ "GenSigSendType" SG_ 638 FRZCU_HandleSwitchStsFR 0;
BA_ "GenSigSendType" SG_ 638 FRZCU_HandleSwitchStsRR 0;
BA_ "GenSigSendType" SG_ 638 FRZCU_HandleSwitchStsRL 0;
BA_ "GenSigSendType" SG_ 638 SeatLength_target_Passenger 0;
BA_ "GenSigSendType" SG_ 638 SeatBackrest_target_Passenger 0;
BA_ "GenSigSendType" SG_ 638 FRZCU_TrunkLockSts 0;
BA_ "GenSigStartValue" SG_ 638 FRZCU_TrunkLockSts 3;
BA_ "GenSigSendType" SG_ 638 FRZCU_HoodLockSts 0;
BA_ "GenSigStartValue" SG_ 638 FRZCU_HoodLockSts 3;
BA_ "GenSigSendType" SG_ 638 FrontBackSpeedAdj_Cmd 0;
BA_ "GenSigSendType" SG_ 638 FRZCU_GloveboxSW 0;
BA_ "GenSigSendType" SG_ 638 FRZCU_FRReleaseLockSts 0;
BA_ "GenSigSendType" SG_ 638 FRZCU_RRReleaseLockSts 0;
BA_ "GenSigSendType" SG_ 638 FRZCU_PELockInKeyWarning 0;
BA_ "GenSigSendType" SG_ 638 FRZCU_PowerOFFWarning 0;
BA_ "GenSigSendType" SG_ 638 FRZCU_KeylessWarning 0;
BA_ "GenSigSendType" SG_ 638 FRZCU_OTAPwrDwnReqFb 0;
BA_ "GenSigSendType" SG_ 638 FRZCU_OTAPwrOnReqFb 0;
BA_ "GenSigSendType" SG_ 949 PEPS_InformationSource 0;
BA_ "GenSigSendType" SG_ 949 PEPS_OrderInformation 0;
BA_ "GenSigSendType" SG_ 949 PEPS_IDInformation 0;
BA_ "GenSigSendType" SG_ 949 PEPS_KeySts 0;
BA_ "GenSigSendType" SG_ 949 PEPS_ETRUnLockReq 4;
BA_ "GenSigSendType" SG_ 1028 PEPS_WelcomeON 4;
BA_ "GenSigSendType" SG_ 1028 PEPS_VehicleSearchReq 4;
BA_ "GenSigSendType" SG_ 1028 PEPS_SATOReminder 4;
BA_ "GenSigSendType" SG_ 1028 PEPS_PLGUnlockReq 4;
BA_ "GenSigSendType" SG_ 1028 PEPS_RKETrunkSts 0;
BA_ "GenSigSendType" SG_ 1028 PEPS_SSBInhibitCWCSts 0;
BA_ "GenSigSendType" SG_ 1028 PEPS_WirelessChargingCtrSts 0;
BA_ "GenSigSendType" SG_ 1028 PEPS_EmgyShutdown 0;
BA_ "GenSigSendType" SG_ 1028 PEPS_SSBInputFailure 0;
BA_ "GenSigSendType" SG_ 1028 PEPS_SmartSystemWarning1_1 0;
BA_ "GenSigSendType" SG_ 1028 PEPS_SmartSystemWarning2_2 0;
BA_ "GenSigSendType" SG_ 1028 PEPS_SmartSystemWarning3_1 0;
BA_ "GenSigSendType" SG_ 1028 PEPS_SmartSystemWarning3_2 0;
BA_ "GenSigSendType" SG_ 1028 PEPS_SmartSystemWarning4_2 0;
BA_ "GenSigSendType" SG_ 1028 PEPS_SmartSystemWarning4_3 0;
BA_ "GenSigSendType" SG_ 1028 PEPS_SystemWarning 0;
BA_ "GenSigSendType" SG_ 1028 PEPS_BLTKeyPESts 0;
BA_ "GenSigSendType" SG_ 1291 Fusa_50B_1 0;
BA_ "GenSigSendType" SG_ 1291 BMS_2_G_CRC 0;
BA_ "E2EDataId" SG_ 1291 BMS_2_G_CRC 117;
BA_ "E2EProfile" SG_ 1291 BMS_2_G_CRC "P01";
BA_ "E2EDataLength" SG_ 1291 BMS_2_G_CRC 64;
BA_ "GenSigSendType" SG_ 1291 BMS_2_G_RollgCntr 0;
BA_ "E2EDataId" SG_ 1291 BMS_2_G_RollgCntr 117;
BA_ "E2EProfile" SG_ 1291 BMS_2_G_RollgCntr "P01";
BA_ "E2EDataLength" SG_ 1291 BMS_2_G_RollgCntr 64;
BA_ "GenSigSendType" SG_ 1291 BMS_2_G_Resd 0;
BA_ "E2EDataId" SG_ 1291 BMS_2_G_Resd 117;
BA_ "E2EProfile" SG_ 1291 BMS_2_G_Resd "P01";
BA_ "E2EDataLength" SG_ 1291 BMS_2_G_Resd 64;
BA_ "GenSigSendType" SG_ 1291 BMS_TBOXInsulation_R 0;
BA_ "E2EDataId" SG_ 1291 BMS_TBOXInsulation_R 117;
BA_ "E2EProfile" SG_ 1291 BMS_TBOXInsulation_R "P01";
BA_ "E2EDataLength" SG_ 1291 BMS_TBOXInsulation_R 64;
BA_ "GenSigSendType" SG_ 1291 BMS_TBOXErrorNumber 0;
BA_ "E2EDataId" SG_ 1291 BMS_TBOXErrorNumber 117;
BA_ "E2EProfile" SG_ 1291 BMS_TBOXErrorNumber "P01";
BA_ "E2EDataLength" SG_ 1291 BMS_TBOXErrorNumber 64;
BA_ "GenSigSendType" SG_ 1291 BMS_TBOXHvBattMaxT 0;
BA_ "GenSigStartValue" SG_ 1291 BMS_TBOXHvBattMaxT 255;
BA_ "E2EDataId" SG_ 1291 BMS_TBOXHvBattMaxT 117;
BA_ "E2EProfile" SG_ 1291 BMS_TBOXHvBattMaxT "P01";
BA_ "E2EDataLength" SG_ 1291 BMS_TBOXHvBattMaxT 64;
BA_ "GenSigSendType" SG_ 1291 BMS_TBOXHvBattMinT 0;
BA_ "GenSigStartValue" SG_ 1291 BMS_TBOXHvBattMinT 255;
BA_ "E2EDataId" SG_ 1291 BMS_TBOXHvBattMinT 117;
BA_ "E2EProfile" SG_ 1291 BMS_TBOXHvBattMinT "P01";
BA_ "E2EDataLength" SG_ 1291 BMS_TBOXHvBattMinT 64;
BA_ "GRC_Sig_ASIL" SG_ 1291 BMS_SOCLight 3;
BA_ "GenSigSendType" SG_ 1291 BMS_SOCLight 0;
BA_ "GenSigInvalidValue" SG_ 1291 BMS_SOCLight 127;
BA_ "E2EDataId" SG_ 1291 BMS_SOCLight 117;
BA_ "E2EProfile" SG_ 1291 BMS_SOCLight "P01";
BA_ "E2EDataLength" SG_ 1291 BMS_SOCLight 64;
BA_ "GRC_Sig_ASIL" SG_ 587 ONEBOX_4_LHFWheelSpeedRPM 5;
BA_ "GenSigSendType" SG_ 587 ONEBOX_4_LHFWheelSpeedRPM 0;
BA_ "GenSigInvalidValue" SG_ 587 ONEBOX_4_LHFWheelSpeedRPM 65535;
BA_ "GRC_Sig_ASIL" SG_ 587 ONEBOX_4_RHFWheelSpeedRPM 5;
BA_ "GenSigSendType" SG_ 587 ONEBOX_4_RHFWheelSpeedRPM 0;
BA_ "GenSigInvalidValue" SG_ 587 ONEBOX_4_RHFWheelSpeedRPM 65535;
BA_ "GRC_Sig_ASIL" SG_ 587 LHRWheelSpeedRPM 3;
BA_ "GenSigSendType" SG_ 587 LHRWheelSpeedRPM 0;
BA_ "GenSigInvalidValue" SG_ 587 LHRWheelSpeedRPM 65535;
BA_ "GRC_Sig_ASIL" SG_ 587 RHRWheelSpeedRPM 3;
BA_ "GenSigSendType" SG_ 587 RHRWheelSpeedRPM 0;
BA_ "GenSigInvalidValue" SG_ 587 RHRWheelSpeedRPM 65535;
BA_ "GRC_Sig_ASIL" SG_ 587 LHRPulseCounterFailSts 3;
BA_ "GenSigSendType" SG_ 587 LHRPulseCounterFailSts 0;
BA_ "GRC_Sig_ASIL" SG_ 587 LHRPulseCounter 3;
BA_ "GenSigSendType" SG_ 587 LHRPulseCounter 0;
BA_ "GRC_Sig_ASIL" SG_ 587 RHRPulseCounterFailSts 3;
BA_ "GenSigSendType" SG_ 587 RHRPulseCounterFailSts 0;
BA_ "GRC_Sig_ASIL" SG_ 587 RHRPulseCounter 3;
BA_ "GenSigSendType" SG_ 587 RHRPulseCounter 0;
BA_ "GRC_Sig_ASIL" SG_ 587 RHFPulseCounterFailSts 3;
BA_ "GenSigSendType" SG_ 587 RHFPulseCounterFailSts 0;
BA_ "GRC_Sig_ASIL" SG_ 587 RHFPulseCounter 3;
BA_ "GenSigSendType" SG_ 587 RHFPulseCounter 0;
BA_ "GRC_Sig_ASIL" SG_ 587 LHFPulseCounterFailSts 3;
BA_ "GenSigSendType" SG_ 587 LHFPulseCounterFailSts 0;
BA_ "GRC_Sig_ASIL" SG_ 587 LHFPulseCounter 3;
BA_ "GenSigSendType" SG_ 587 LHFPulseCounter 0;
BA_ "GRC_Sig_ASIL" SG_ 587 LHFWheelDriveDirection 3;
BA_ "GenSigSendType" SG_ 587 LHFWheelDriveDirection 0;
BA_ "GenSigInvalidValue" SG_ 587 LHFWheelDriveDirection 4;
BA_ "GRC_Sig_ASIL" SG_ 587 RHFWheelDriveDirection 3;
BA_ "GenSigSendType" SG_ 587 RHFWheelDriveDirection 0;
BA_ "GenSigInvalidValue" SG_ 587 RHFWheelDriveDirection 4;
BA_ "GRC_Sig_ASIL" SG_ 587 LHRWheelDriveDirection 3;
BA_ "GenSigSendType" SG_ 587 LHRWheelDriveDirection 0;
BA_ "GenSigInvalidValue" SG_ 587 LHRWheelDriveDirection 4;
BA_ "GRC_Sig_ASIL" SG_ 587 RHRWheelDriveDirection 3;
BA_ "GenSigSendType" SG_ 587 RHRWheelDriveDirection 0;
BA_ "GenSigInvalidValue" SG_ 587 RHRWheelDriveDirection 4;
BA_ "GenSigSendType" SG_ 1338 FMCU_ErrLvlDis 0;
BA_ "GenSigSendType" SG_ 1338 FMCU_SpdAct_EDR 0;
BA_ "GenSigInvalidValue" SG_ 1338 FMCU_SpdAct_EDR 65535;
BA_ "GenSigStartValue" SG_ 1338 FMCU_SpdAct_EDR 32767;
BA_ "GenSigSendType" SG_ 777 ISGF_ErrLvl 0;
BA_ "GenSigSendType" SG_ 1403 RMCU_ErrLvlDis 0;
BA_ "GenSigSendType" SG_ 1403 RMCU_Speed_EDR 0;
BA_ "GenSigSendType" SG_ 1299 BMS_PackVoltageDis 0;
BA_ "GenSigInvalidValue" SG_ 1299 BMS_PackVoltageDis 65535;
BA_ "GenSigStartValue" SG_ 1299 BMS_PackVoltageDis 65535;
BA_ "GenSigSendType" SG_ 1299 BMS_PackCurrentDis 0;
BA_ "GenSigInvalidValue" SG_ 1299 BMS_PackCurrentDis 65535;
BA_ "GenSigStartValue" SG_ 1299 BMS_PackCurrentDis 65535;
BA_ "GenSigSendType" SG_ 1099 ISGF_SysTempOvrInd 0;
BA_ "GenSigSendType" SG_ 1130 TCU_23_GBFaultstatus 0;
BA_ "GRC_Sig_ASIL" SG_ 1130 TCU_23_TeachInState 1;
BA_ "GenSigSendType" SG_ 1130 TCU_23_TeachInState 0;
BA_ "GRC_Sig_ASIL" SG_ 1130 TCU_23_GBWarmUpReq 1;
BA_ "GenSigSendType" SG_ 1130 TCU_23_GBWarmUpReq 0;
BA_ "GRC_Sig_ASIL" SG_ 1130 TCU_23_CluSelfLrng 1;
BA_ "GenSigSendType" SG_ 1130 TCU_23_CluSelfLrng 0;
BA_ "E2EDataLength" SG_ 1180 New_Signal_49C_9 64;
BA_ "E2EProfile" SG_ 1180 New_Signal_49C_9 "P01";
BA_ "E2EDataId" SG_ 1180 New_Signal_49C_9 173;
BA_ "GenSigSendType" SG_ 1180 New_Signal_49C_9 0;
BA_ "E2EDataLength" SG_ 1180 New_Signal_49C_8 64;
BA_ "E2EProfile" SG_ 1180 New_Signal_49C_8 "P01";
BA_ "E2EDataId" SG_ 1180 New_Signal_49C_8 173;
BA_ "GenSigSendType" SG_ 1180 New_Signal_49C_8 0;
BA_ "E2EDataLength" SG_ 1180 New_Signal_49C_7 64;
BA_ "E2EProfile" SG_ 1180 New_Signal_49C_7 "P01";
BA_ "E2EDataId" SG_ 1180 New_Signal_49C_7 173;
BA_ "GenSigSendType" SG_ 1180 New_Signal_49C_7 0;
BA_ "E2EDataLength" SG_ 1180 New_Signal_49C_6 64;
BA_ "E2EProfile" SG_ 1180 New_Signal_49C_6 "P01";
BA_ "E2EDataId" SG_ 1180 New_Signal_49C_6 173;
BA_ "GenSigSendType" SG_ 1180 New_Signal_49C_6 0;
BA_ "E2EDataLength" SG_ 1180 New_Signal_49C_5 64;
BA_ "E2EProfile" SG_ 1180 New_Signal_49C_5 "P01";
BA_ "E2EDataId" SG_ 1180 New_Signal_49C_5 173;
BA_ "GenSigSendType" SG_ 1180 New_Signal_49C_5 0;
BA_ "E2EDataLength" SG_ 1180 New_Signal_49C_4 64;
BA_ "E2EProfile" SG_ 1180 New_Signal_49C_4 "P01";
BA_ "E2EDataId" SG_ 1180 New_Signal_49C_4 173;
BA_ "GenSigSendType" SG_ 1180 New_Signal_49C_4 0;
BA_ "E2EDataLength" SG_ 1180 New_Signal_49C_3 64;
BA_ "E2EProfile" SG_ 1180 New_Signal_49C_3 "P01";
BA_ "E2EDataId" SG_ 1180 New_Signal_49C_3 173;
BA_ "GenSigSendType" SG_ 1180 New_Signal_49C_3 0;
BA_ "E2EDataLength" SG_ 1180 New_Signal_49C_2 64;
BA_ "E2EProfile" SG_ 1180 New_Signal_49C_2 "P01";
BA_ "E2EDataId" SG_ 1180 New_Signal_49C_2 173;
BA_ "GenSigSendType" SG_ 1180 New_Signal_49C_2 0;
BA_ "E2EDataLength" SG_ 1180 New_Signal_49C_1 64;
BA_ "E2EProfile" SG_ 1180 New_Signal_49C_1 "P01";
BA_ "E2EDataId" SG_ 1180 New_Signal_49C_1 173;
BA_ "GenSigSendType" SG_ 1180 New_Signal_49C_1 0;
BA_ "E2EDataLength" SG_ 1180 ACU_1_RollgCntr1 64;
BA_ "E2EProfile" SG_ 1180 ACU_1_RollgCntr1 "P01";
BA_ "E2EDataId" SG_ 1180 ACU_1_RollgCntr1 173;
BA_ "GenSigSendType" SG_ 1180 ACU_1_RollgCntr1 0;
BA_ "E2EDataLength" SG_ 1180 ACU_1_CRC1 64;
BA_ "E2EProfile" SG_ 1180 ACU_1_CRC1 "P01";
BA_ "E2EDataId" SG_ 1180 ACU_1_CRC1 173;
BA_ "GenSigSendType" SG_ 1180 ACU_1_CRC1 0;
BA_ "E2EDataLength" SG_ 1180 ABM_1_Rollover_Status 64;
BA_ "E2EProfile" SG_ 1180 ABM_1_Rollover_Status "P01";
BA_ "E2EDataId" SG_ 1180 ABM_1_Rollover_Status 173;
BA_ "GenSigSendType" SG_ 1180 ABM_1_Rollover_Status 0;
BA_ "E2EDataLength" SG_ 1180 ACU_1_AirBagFailSts 64;
BA_ "E2EProfile" SG_ 1180 ACU_1_AirBagFailSts "P01";
BA_ "E2EDataId" SG_ 1180 ACU_1_AirBagFailSts 173;
BA_ "GenSigSendType" SG_ 1180 ACU_1_AirBagFailSts 0;
BA_ "GenSigStartValue" SG_ 1180 ACU_1_AirBagFailSts 3;
BA_ "E2EDataLength" SG_ 1180 ACU_1_ThdRowLBeltWarning 64;
BA_ "E2EProfile" SG_ 1180 ACU_1_ThdRowLBeltWarning "P01";
BA_ "E2EDataId" SG_ 1180 ACU_1_ThdRowLBeltWarning 173;
BA_ "GenSigSendType" SG_ 1180 ACU_1_ThdRowLBeltWarning 0;
BA_ "E2EDataLength" SG_ 1180 ACU_1_ThdRowRBeltWarning 64;
BA_ "E2EProfile" SG_ 1180 ACU_1_ThdRowRBeltWarning "P01";
BA_ "E2EDataId" SG_ 1180 ACU_1_ThdRowRBeltWarning 173;
BA_ "GenSigSendType" SG_ 1180 ACU_1_ThdRowRBeltWarning 0;
BA_ "E2EDataLength" SG_ 1180 ACU_1_PsngrSeatBeltWarning 64;
BA_ "E2EProfile" SG_ 1180 ACU_1_PsngrSeatBeltWarning "P01";
BA_ "E2EDataId" SG_ 1180 ACU_1_PsngrSeatBeltWarning 173;
BA_ "GenSigSendType" SG_ 1180 ACU_1_PsngrSeatBeltWarning 0;
BA_ "E2EDataLength" SG_ 1180 ACU_1_SecRowLBeltWarning 64;
BA_ "E2EProfile" SG_ 1180 ACU_1_SecRowLBeltWarning "P01";
BA_ "E2EDataId" SG_ 1180 ACU_1_SecRowLBeltWarning 173;
BA_ "GenSigSendType" SG_ 1180 ACU_1_SecRowLBeltWarning 0;
BA_ "E2EDataLength" SG_ 1180 ACU_1_SecRowMBeltWarning 64;
BA_ "E2EProfile" SG_ 1180 ACU_1_SecRowMBeltWarning "P01";
BA_ "E2EDataId" SG_ 1180 ACU_1_SecRowMBeltWarning 173;
BA_ "GenSigSendType" SG_ 1180 ACU_1_SecRowMBeltWarning 0;
BA_ "E2EDataLength" SG_ 1180 ACU_1_SecRowRBeltWarning 64;
BA_ "E2EProfile" SG_ 1180 ACU_1_SecRowRBeltWarning "P01";
BA_ "E2EDataId" SG_ 1180 ACU_1_SecRowRBeltWarning 173;
BA_ "GenSigSendType" SG_ 1180 ACU_1_SecRowRBeltWarning 0;
BA_ "E2EDataLength" SG_ 1180 ACU_1_PsngrSeatOccupiedSts 64;
BA_ "E2EProfile" SG_ 1180 ACU_1_PsngrSeatOccupiedSts "P01";
BA_ "E2EDataId" SG_ 1180 ACU_1_PsngrSeatOccupiedSts 173;
BA_ "GenSigSendType" SG_ 1180 ACU_1_PsngrSeatOccupiedSts 0;
BA_ "GenSigSendType" SG_ 1341 BMS_44_PackPowerRealTime 0;
BA_ "GenSigInvalidValue" SG_ 1341 BMS_44_PackPowerRealTime 16383;
BA_ "GenSigStartValue" SG_ 1341 BMS_44_PackPowerRealTime 10240;
BA_ "GenSigSendType" SG_ 811 BMS_Chg_Sts 0;
BA_ "GenSigInvalidValue" SG_ 811 BMS_Chg_Sts 15;
BA_ "GenSigSendType" SG_ 1427 ILCF_1_LogoParkingSts 0;
BA_ "GenSigStartValue" SG_ 1427 ILCF_1_LogoParkingSts 1;
BA_ "GenSigSendType" SG_ 1172 ExternalTemperature_F 0;
BA_ "GenSigStartValue" SG_ 1172 ExternalTemperature_F 225;
BA_ "GenSigSendType" SG_ 1172 ExternalTemperature_C 0;
BA_ "GenSigInvalidValue" SG_ 1172 ExternalTemperature_C 254;
BA_ "GenSigStartValue" SG_ 1172 ExternalTemperature_C 254;
BA_ "GenSigSendType" SG_ 1172 BlowSpeedLevelDisplaySts 0;
BA_ "GenSigSendType" SG_ 1147 CCP_1_FLTempSwitchReq 0;
BA_ "GenSigInvalidValue" SG_ 1147 CCP_1_FLTempSwitchReq 31;
BA_ "GenSigStartValue" SG_ 1147 CCP_1_FLTempSwitchReq 31;
BA_ "GenSigSendType" SG_ 1147 CCP_1_FrontAutoACSwitchReq 0;
BA_ "GenSigSendType" SG_ 1147 CCP_1_FBlowSpdCtrlSwitchReq 0;
BA_ "GenSigSendType" SG_ 1147 FLCCP_MainSetHeatReq 0;
BA_ "GenSigSendType" SG_ 1147 FLCCP_MainSetVentilationReq 0;
BA_ "GenSigSendType" SG_ 1107 TMS_PM25_Detect 0;
BA_ "GenSigSendType" SG_ 1107 TMS_CCP_FLTempSts 0;
BA_ "GenSigInvalidValue" SG_ 1107 TMS_CCP_FLTempSts 31;
BA_ "GenSigStartValue" SG_ 1107 TMS_CCP_FLTempSts 31;
BA_ "GenSigSendType" SG_ 1107 TMS_CCP_FrontAutoACSts 0;
BA_ "GenSigSendType" SG_ 1107 TMS_CCP_ACStatus 0;
BA_ "GenSigSendType" SG_ 1107 TMS_CCP_FrontOFFSts 0;
BA_ "GenSigSendType" SG_ 1107 TMS_CCP_FBlowSpdCtrlSts 0;
BA_ "GenSigSendType" SG_ 1107 TMS_CCP_FRTempSts 0;
BA_ "GenSigInvalidValue" SG_ 1107 TMS_CCP_FRTempSts 31;
BA_ "GenSigStartValue" SG_ 1107 TMS_CCP_FRTempSts 31;
BA_ "GenSigSendType" SG_ 1107 TMS_CCP_RecyMode 0;
BA_ "GenSigSendType" SG_ 1107 TMS_CCP_FrontDefrostSts 0;
BA_ "GenSigSendType" SG_ 1107 TMS_UVC_WorkingBfReq 0;
BA_ "GenSigSendType" SG_ 1107 TMS_UVC_LuminanceBfReq 0;
BA_ "GenSigSendType" SG_ 1107 TMS_CCP_ACFastCool 0;
BA_ "GenSigSendType" SG_ 1107 TMS_CCP_ACFastHeat 0;
BA_ "GenSigSendType" SG_ 1175 CCP_2_FRTempSwitchReq 0;
BA_ "GenSigInvalidValue" SG_ 1175 CCP_2_FRTempSwitchReq 31;
BA_ "GenSigStartValue" SG_ 1175 CCP_2_FRTempSwitchReq 31;
BA_ "GenSigSendType" SG_ 1175 CCP_2_RecyModeReq 0;
BA_ "GenSigSendType" SG_ 1175 CCP_2_DefrostModeSwitchReq 0;
BA_ "GenSigSendType" SG_ 1175 CCP_2_RearDefrostSwitchReq 0;
BA_ "GenSigSendType" SG_ 1175 CCP_2_ACSwitchReq 0;
BA_ "GenSigSendType" SG_ 1292 CHB_App_Sts 0;
BA_ "GenSigSendType" SG_ 1292 CHB_AppMem_Sts 0;
BA_ "GenSigSendType" SG_ 1292 CHB_AppDelay_Sts 0;
BA_ "GenSigSendType" SG_ 1292 CHB_AppTimeset_Sts 0;
BA_ "GenSigInvalidValue" SG_ 1292 CHB_AppTimeset_Sts 31;
BA_ "GenSigSendType" SG_ 1292 CHB_AppCoolorheat_Sts 0;
BA_ "GenSigSendType" SG_ 1292 CHB_AppCoolset_Sts 0;
BA_ "GenSigSendType" SG_ 1292 CHB_AppHeatset_Sts 0;
BA_ "GenSigSendType" SG_ 1292 CHB_AppSterilization_Sts 0;
BA_ "GenSigSendType" SG_ 1292 CHB_AppItemsLeft_Sts 0;
BA_ "GenSigSendType" SG_ 1292 CHB_AppItemsLeftset_Sts 0;
BA_ "GenSigSendType" SG_ 1292 CHB_AppChbDoor_Sts 0;
BA_ "GenSigSendType" SG_ 1241 FuelTankLidSystemFailureSts 0;
BA_ "GenSigSendType" SG_ 1241 FuelTankPressureConditionReached 0;
BA_ "GRC_Sig_ASIL" SG_ 49 ACU_2_LateralAcceleration 3;
BA_ "GenSigSendType" SG_ 49 ACU_2_LateralAcceleration 0;
BA_ "GenSigInvalidValue" SG_ 49 ACU_2_LateralAcceleration 65535;
BA_ "GenSigStartValue" SG_ 49 ACU_2_LateralAcceleration 2000;
BA_ "GRC_Sig_ASIL" SG_ 49 ACU_2_YawRate 3;
BA_ "GenSigSendType" SG_ 49 ACU_2_YawRate 0;
BA_ "GenSigInvalidValue" SG_ 49 ACU_2_YawRate 65535;
BA_ "GenSigStartValue" SG_ 49 ACU_2_YawRate 18000;
BA_ "GRC_Sig_ASIL" SG_ 49 ACU_2_YawrateSigValidData 3;
BA_ "GenSigSendType" SG_ 49 ACU_2_YawrateSigValidData 0;
BA_ "GenSigStartValue" SG_ 49 ACU_2_YawrateSigValidData 3;
BA_ "GRC_Sig_ASIL" SG_ 49 ACU_2_LateralAccelerationSigVD 3;
BA_ "GenSigSendType" SG_ 49 ACU_2_LateralAccelerationSigVD 0;
BA_ "GenSigStartValue" SG_ 49 ACU_2_LateralAccelerationSigVD 3;
BA_ "GenSigSendType" SG_ 1024 FRZCU_ADSLightSts 0;
BA_ "GenSigSendType" SG_ 1024 CSunshadeSts 0;
BA_ "GenSigSendType" SG_ 1024 CSunshadePercentSts 0;
BA_ "GenSigSendType" SG_ 1024 FRZCU_SeatHeatLvlFR2 0;
BA_ "GenSigSendType" SG_ 1024 FRZCU_SeatVentLvlFR2 0;
BA_ "GenSigSendType" SG_ 1024 FRZCU_SeatVentLvlRR2 0;
BA_ "GenSigSendType" SG_ 1024 FRZCU_SeatHeatLvlRR2 0;
BA_ "GenSigSendType" SG_ 1024 FRZCU_ContainerlightSts 0;
BA_ "GenSigSendType" SG_ 1024 FRZCU_FRWinThermalSts 0;
BA_ "GenSigSendType" SG_ 1024 FRZCU_RRWinThermalSts 0;
BA_ "GenSigSendType" SG_ 1024 FRZCU_CSunshadeThermalSts 0;
BA_ "GenSigSendType" SG_ 1182 OBC_InnerDischgVolt 0;
BA_ "GenSigSendType" SG_ 1182 OBC_InnerDischgCurr 0;
BA_ "GenSigSendType" SG_ 1182 OBC_ElectronicLockSts 0;
BA_ "GRC_Sig_ASIL" SG_ 1182 OBC_WorkingMode 2;
BA_ "GenSigSendType" SG_ 1182 OBC_WorkingMode 0;
BA_ "GRC_Sig_ASIL" SG_ 1182 OBC_OutDischgCurr 2;
BA_ "GenSigSendType" SG_ 1182 OBC_OutDischgCurr 0;
BA_ "GRC_Sig_ASIL" SG_ 1182 OBC_OutDischgVolt 2;
BA_ "GenSigSendType" SG_ 1182 OBC_OutDischgVolt 0;
BA_ "GenSigSendType" SG_ 513 MFSL_UP_SW 0;
BA_ "GenSigSendType" SG_ 513 MFSL_DW_SW 0;
BA_ "GenSigSendType" SG_ 513 MFSL_Left_SW 0;
BA_ "GenSigSendType" SG_ 513 MFSL_Right_SW 0;
BA_ "GenSigSendType" SG_ 513 MFSL_OK_SW 0;
BA_ "GenSigSendType" SG_ 513 MFSL_APA_SW 0;
BA_ "GenSigSendType" SG_ 513 MFSL_LCC_NCA_SW 0;
BA_ "GenSigSendType" SG_ 1152 TBOX_PetmodeSetTemperature 5;
BA_ "GenSigInvalidValue" SG_ 1152 TBOX_PetmodeSetTemperature 31;
BA_ "GenSigStartValue" SG_ 1152 TBOX_PetmodeSetTemperature 31;
BA_ "GenSigSendType" SG_ 1164 OBC_DischgSts 0;
BA_ "GenSigSendType" SG_ 789 ATCM_DriveModeSw 5;
BA_ "GenSigSendType" SG_ 789 ATCM_XModeSw 5;
BA_ "GenSigSendType" SG_ 789 ATCM_SwitchUTurnModeSet 5;
BA_ "GenSigSendType" SG_ 789 ATCM_ESP_OFF_SW 5;
BA_ "GenSigSendType" SG_ 789 ATCM_AVH_SW 5;
BA_ "GenSigSendType" SG_ 789 ATCM_AVM 5;
BA_ "GenSigSendType" SG_ 1214 BNCM_16_CRC1 1;
BA_ "GenSigSendType" SG_ 1214 BNCM_16_RollgCntr1 1;
BA_ "GenSigSendType" SG_ 1214 BNCM_16_Resd1 1;
BA_ "GenSigSendType" SG_ 1214 BNCM_16_CMD 1;
BA_ "GenSigSendType" SG_ 1214 BNCM_16_PDU1 1;
BA_ "GenSigSendType" SG_ 1214 BNCM_16_PDU2 1;
BA_ "GenSigSendType" SG_ 1214 BNCM_16_PDU3 1;
BA_ "GenSigSendType" SG_ 1214 BNCM_16_PDU4 1;
BA_ "GRC_Sig_ASIL" SG_ 571 LHTurnlightSts 3;
BA_ "GenSigSendType" SG_ 571 LHTurnlightSts 0;
BA_ "GRC_Sig_ASIL" SG_ 571 RHTurnlightSts 3;
BA_ "GenSigSendType" SG_ 571 RHTurnlightSts 0;
BA_ "GRC_Sig_ASIL" SG_ 571 LHFdoorSts 2;
BA_ "GenSigSendType" SG_ 571 LHFdoorSts 0;
BA_ "GRC_Sig_ASIL" SG_ 571 LHFDoorLockSts 2;
BA_ "GenSigSendType" SG_ 571 LHFDoorLockSts 0;
BA_ "GenSigStartValue" SG_ 571 LHFDoorLockSts 3;
BA_ "GenSigSendType" SG_ 571 LHTurnSW 0;
BA_ "GenSigSendType" SG_ 571 RHTurnSW 0;
BA_ "GenSigSendType" SG_ 571 HazardLightSW 0;
BA_ "GRC_Sig_ASIL" SG_ 571 LHFSeatBeltSW 2;
BA_ "GenSigSendType" SG_ 571 LHFSeatBeltSW 0;
BA_ "GRC_Sig_ASIL" SG_ 571 DirectionIndLeft 3;
BA_ "GenSigSendType" SG_ 571 DirectionIndLeft 0;
BA_ "GRC_Sig_ASIL" SG_ 571 DirectionIndRight 3;
BA_ "GenSigSendType" SG_ 571 DirectionIndRight 0;
BA_ "GRC_Sig_ASIL" SG_ 699 LHRdoorSts 2;
BA_ "GenSigSendType" SG_ 699 LHRdoorSts 0;
BA_ "GenSigSendType" SG_ 787 ChrgHoodSts 0;
BA_ "GenSigSendType" SG_ 787 FRZCU_FRSitPosnSts 0;
BA_ "GenSigSendType" SG_ 572 ONEBOX_7_TAB_HighTemp 0;
BA_ "GenSigSendType" SG_ 572 ONEBOX_7_TAB_Active 0;
BA_ "GenSigSendType" SG_ 572 ONEBOX_7_BSW_Active 0;
BA_ "GenSigSendType" SG_ 572 ONEBOX_7_iCCO_TgtVel 0;
BA_ "GRC_Sig_ASIL" SG_ 1212 VCU_3_G_ActWheelTorqueFA 3;
BA_ "GenSigSendType" SG_ 1212 VCU_3_G_ActWheelTorqueFA 0;
BA_ "GRC_Sig_ASIL" SG_ 1212 VCU_3_G_ActWheelTorqueRA 3;
BA_ "GenSigSendType" SG_ 1212 VCU_3_G_ActWheelTorqueRA 0;
BA_ "GenSigSendType" SG_ 1110 IMMO_Chall_ICC 2;
BA_ "GenSigSendType" SG_ 1149 IMMO_Teach_VCC 2;
BA_ "GenSigSendType" SG_ 1120 RLHS_2_AmbBrightness 0;
BA_ "GenSigInvalidValue" SG_ 1120 RLHS_2_AmbBrightness 4095;
BA_ "GenSigSendType" SG_ 1120 RLHS_LiSwithReason 0;
BA_ "GRC_Sig_ASIL" SG_ 1199 TCM_1_TrailerSts 3;
BA_ "GenSigSendType" SG_ 1199 TCM_1_TrailerSts 0;
BA_ "GenSigSendType" SG_ 770 ADS_VdcActvSts_302h 0;
BA_ "GenSigSendType" SG_ 770 ADS_TcsActvSts_302h 0;
BA_ "GenSigSendType" SG_ 770 ADS_CRC1_302h 0;
BA_ "GenSigSendType" SG_ 770 ADS_RollgCntr1_302h 0;
BA_ "GenSigSendType" SG_ 770 ADS_Resd1_302h 0;
BA_ "GenSigSendType" SG_ 770 ADS_RPAOnlineOrNot_302h 0;
BA_ "GenSigSendType" SG_ 770 ADS_RpaParkAuthn_302h 0;
BA_ "GenSigSendType" SG_ 770 ADS_SeldParkID_302h 0;
BA_ "GenSigInvalidValue" SG_ 770 ADS_SeldParkID_302h 11;
BA_ "GenSigSendType" SG_ 770 ADS_VehParkMod_302h 0;
BA_ "GenSigInvalidValue" SG_ 770 ADS_VehParkMod_302h 3;
BA_ "GenSigSendType" SG_ 770 ADS_RemParkPatSel_302h 0;
BA_ "GenSigSendType" SG_ 770 ADS_ParkDirCfm_302h 0;
BA_ "GenSigInvalidValue" SG_ 770 ADS_ParkDirCfm_302h 8;
BA_ "GenSigSendType" SG_ 770 ADS_ParkProgs_302h 0;
BA_ "GenSigSendType" SG_ 770 ADS_ParkRmngDst_302h 0;
BA_ "GenSigSendType" SG_ 770 ADS_ObstclDst_302h 0;
BA_ "GenSigSendType" SG_ 770 ADS_AutEve_302h 0;
BA_ "GenSigSendType" SG_ 770 ADS_CRC2_302h 0;
BA_ "GenSigSendType" SG_ 770 ADS_RollgCntr2_302h 0;
BA_ "GenSigSendType" SG_ 770 ADS_Resd2_302h 0;
BA_ "GenSigSendType" SG_ 770 ADS_parkInterruptDuration_302h 0;
BA_ "GenSigSendType" SG_ 770 APA_ResuAvl_302h 0;
BA_ "GenSigSendType" SG_ 770 ADS_ParkStMac_302h 0;
BA_ "GenSigSendType" SG_ 770 ADS_ParkOutDir_ParaLe_302h 0;
BA_ "GenSigSendType" SG_ 770 ADS_ParkOutDir_ParaRi_302h 0;
BA_ "GenSigSendType" SG_ 770 ADS_ParkOutDir_PerpFwd_302h 0;
BA_ "GenSigSendType" SG_ 770 ADS_ParkOutDir_PerpLeFwd_302h 0;
BA_ "GenSigSendType" SG_ 770 ADS_ParkOutDir_PerpRiFwd_302h 0;
BA_ "GenSigSendType" SG_ 770 ADS_ParkOutDir_PerpLeBack_302h 0;
BA_ "GenSigSendType" SG_ 770 ADS_ParkOutDir_PerpRiBack_302h 0;
BA_ "GenSigSendType" SG_ 770 ADS_ParkOutDir_PerpBack_302h 0;
BA_ "GenSigSendType" SG_ 770 APA_RPAFctUnavlMsg_1_302h 0;
BA_ "GenSigSendType" SG_ 770 APA_RPAFctUnavlMsg_2_302h 0;
BA_ "GenSigSendType" SG_ 770 APA_RPAFctUnavlMsg_3_302h 0;
BA_ "GenSigSendType" SG_ 770 APA_RPAFctUnavlMsg_4_302h 0;
BA_ "GenSigSendType" SG_ 770 APA_RPAFctUnavlMsg_5_302h 0;
BA_ "GenSigSendType" SG_ 770 APA_RPAFctUnavlMsg_6_302h 0;
BA_ "GenSigSendType" SG_ 770 APA_RPAFctUnavlMsg_7_302h 0;
BA_ "GenSigSendType" SG_ 770 APA_RPAFctUnavlMsg_8_302h 0;
BA_ "GenSigSendType" SG_ 770 APA_RPAFctUnavlMsg_9_302h 0;
BA_ "GenSigSendType" SG_ 770 APA_RPAFctUnavlMsg_10_302h 0;
BA_ "GenSigSendType" SG_ 770 APA_RPAFctUnavlMsg_11_302h 0;
BA_ "GenSigSendType" SG_ 770 APA_RPAFctUnavlMsg_12_302h 0;
BA_ "GenSigSendType" SG_ 770 APA_RPAFctUnavlMsg_13_302h 0;
BA_ "GenSigSendType" SG_ 770 APA_RPAFctUnavlMsg_14_302h 0;
BA_ "GenSigSendType" SG_ 770 APA_RPAFctUnavlMsg_15_302h 0;
BA_ "GenSigSendType" SG_ 770 APA_RPAFctUnavlMsg_16_302h 0;
BA_ "GenSigSendType" SG_ 770 APA_RPAFctUnavlMsg_17_302h 0;
BA_ "GenSigSendType" SG_ 770 APA_RPAFctUnavlMsg_18_302h 0;
BA_ "GenSigSendType" SG_ 770 APA_RPAFctUnavlMsg_19_302h 0;
BA_ "GenSigSendType" SG_ 770 APA_RPAFctUnavlMsg_20_302h 0;
BA_ "GenSigSendType" SG_ 770 APA_RPAFctUnavlMsg_21_302h 0;
BA_ "GenSigSendType" SG_ 770 APA_RPAFctUnavlMsg_22_302h 0;
BA_ "GenSigSendType" SG_ 770 APA_RPAFctUnavlMsg_23_302h 0;
BA_ "GenSigSendType" SG_ 770 APA_RPAFctUnavlMsg_24_302h 0;
BA_ "GenSigSendType" SG_ 770 APA_RPAFctUnavlMsg_25_302h 0;
BA_ "GenSigSendType" SG_ 770 ADS_CRC3_302h 0;
BA_ "GenSigSendType" SG_ 770 ADS_RollgCntr3_302h 0;
BA_ "GenSigSendType" SG_ 770 ADS_Resd3_302h 0;
BA_ "GenSigSendType" SG_ 770 APA_RPACnclMsg_1_302h 0;
BA_ "GenSigSendType" SG_ 770 APA_RPACnclMsg_2_302h 0;
BA_ "GenSigSendType" SG_ 770 APA_RPACnclMsg_3 0;
BA_ "GenSigSendType" SG_ 770 APA_RPACnclMsg_4_302h 0;
BA_ "GenSigSendType" SG_ 770 APA_RPACnclMsg_5_302h 0;
BA_ "GenSigSendType" SG_ 770 APA_RPACnclMsg_6_302h 0;
BA_ "GenSigSendType" SG_ 770 APA_RPACnclMsg_7_302h 0;
BA_ "GenSigSendType" SG_ 770 APA_RPACnclMsg_8_302h 0;
BA_ "GenSigSendType" SG_ 770 APA_RPACnclMsg_9_302h 0;
BA_ "GenSigSendType" SG_ 770 APA_RPACnclMsg_10_302h 0;
BA_ "GenSigSendType" SG_ 770 APA_RPACnclMsg_11_302h 0;
BA_ "GenSigSendType" SG_ 770 APA_RPACnclMsg_12_302h 0;
BA_ "GenSigSendType" SG_ 770 APA_RPACnclMsg_13_302h 0;
BA_ "GenSigSendType" SG_ 770 APA_RPACnclMsg_14_302h 0;
BA_ "GenSigSendType" SG_ 770 APA_RPACnclMsg_15_302h 0;
BA_ "GenSigSendType" SG_ 770 APA_RPACnclMsg_16_302h 0;
BA_ "GenSigSendType" SG_ 770 APA_RPACnclMsg_17_302h 0;
BA_ "GenSigSendType" SG_ 770 APA_RPACnclMsg_18_302h 0;
BA_ "GenSigSendType" SG_ 770 APA_RPACnclMsg_19_302h 0;
BA_ "GenSigSendType" SG_ 770 APA_RPACnclMsg_20_302h 0;
BA_ "GenSigSendType" SG_ 770 APA_RPAPauseMsg_1_302h 0;
BA_ "GenSigSendType" SG_ 770 APA_RPAPauseMsg_2_302h 0;
BA_ "GenSigSendType" SG_ 770 APA_RPAPauseMsg_3_302h 0;
BA_ "GenSigSendType" SG_ 770 APA_RPAPauseMsg_4_302h 0;
BA_ "GenSigSendType" SG_ 770 APA_RPAPauseMsg_5_302h 0;
BA_ "GenSigSendType" SG_ 770 APA_RPAPauseMsg_6_302h 0;
BA_ "GenSigSendType" SG_ 770 APA_RPAPauseMsg_7_302h 0;
BA_ "GenSigSendType" SG_ 770 APA_RPAPauseMsg_8_302h 0;
BA_ "GenSigSendType" SG_ 770 APA_RPAPauseMsg_9_302h 0;
BA_ "GenSigSendType" SG_ 770 APA_RPAPauseMsg_10_302h 0;
BA_ "GenSigSendType" SG_ 770 ADS_ParkPosn1_ID_302h 0;
BA_ "GenSigSendType" SG_ 770 ADS_MnvrOrintChng1_302h 0;
BA_ "GenSigSendType" SG_ 770 ADS_MnvrOrintChng2_302h 0;
BA_ "GenSigSendType" SG_ 770 ADS_ParkRelPos1_x1_302h 0;
BA_ "GenSigSendType" SG_ 770 ADS_CRC4_302h 0;
BA_ "GenSigSendType" SG_ 770 ADS_RollgCntr4_302h 0;
BA_ "GenSigSendType" SG_ 770 ADS_Resd4_302h 0;
BA_ "GenSigSendType" SG_ 770 ADS_ParkRelPos1_y1_302h 0;
BA_ "GenSigSendType" SG_ 770 ADS_ParkRelPos1_x2_302h 0;
BA_ "GenSigSendType" SG_ 770 ADS_ParkRelPos1_y2_302h 0;
BA_ "GenSigSendType" SG_ 770 ADS_ParkRelPos1_x3_302h 0;
BA_ "GenSigSendType" SG_ 770 ADS_TarParkSt_Posn1_302h 0;
BA_ "GenSigSendType" SG_ 770 ADS_ParkChkSrc_Posn1_302h 0;
BA_ "GenSigSendType" SG_ 770 ADS_CRC5_302h 0;
BA_ "GenSigSendType" SG_ 770 ADS_RollgCntr5_302h 0;
BA_ "GenSigSendType" SG_ 770 ADS_Resd5_302h 0;
BA_ "GenSigSendType" SG_ 770 ADS_ParkRelPos1_y3_302h 0;
BA_ "GenSigSendType" SG_ 770 ADS_ParkRelPos1_x4_302h 0;
BA_ "GenSigSendType" SG_ 770 ADS_ParkRelPos1_y4_302h 0;
BA_ "GenSigSendType" SG_ 770 ADS_ParkPosn2_ID_302h 0;
BA_ "GenSigSendType" SG_ 770 ADS_ParkRelPos2_x1_302h 0;
BA_ "GenSigSendType" SG_ 770 ADS_CRC6_302h 0;
BA_ "GenSigSendType" SG_ 770 ADS_RollgCntr6_302h 0;
BA_ "GenSigSendType" SG_ 770 ADS_Resd6_302h 0;
BA_ "GenSigSendType" SG_ 770 ADS_ParkRelPos2_y1_302h 0;
BA_ "GenSigSendType" SG_ 770 ADS_ParkRelPos2_x2_302h 0;
BA_ "GenSigSendType" SG_ 770 ADS_ParkRelPos2_y2_302h 0;
BA_ "GenSigSendType" SG_ 770 ADS_ParkRelPos2_x3_302h 0;
BA_ "GenSigSendType" SG_ 770 ADS_TarParkSt_Posn2_302h 0;
BA_ "GenSigSendType" SG_ 770 ADS_ParkChkSrc_Posn2_302h 0;
BA_ "GenSigSendType" SG_ 770 ADS_CRC7_302h 0;
BA_ "GenSigSendType" SG_ 770 ADS_RollgCntr7_302h 0;
BA_ "GenSigSendType" SG_ 770 ADS_Resd7_302h 0;
BA_ "GenSigSendType" SG_ 770 ADS_ParkRelPos2_y3_302h 0;
BA_ "GenSigSendType" SG_ 770 ADS_ParkRelPos2_x4_302h 0;
BA_ "GenSigSendType" SG_ 770 ADS_ParkRelPos2_y4_302h 0;
BA_ "GenSigSendType" SG_ 514 Fusa_202_1 0;
BA_ "E2EDataLength" SG_ 514 ADS_CRC1_202h 64;
BA_ "E2EProfile" SG_ 514 ADS_CRC1_202h "P01";
BA_ "E2EDataId" SG_ 514 ADS_CRC1_202h 255;
BA_ "GenSigSendType" SG_ 514 ADS_CRC1_202h 0;
BA_ "E2EDataLength" SG_ 514 ADS_RollgCntr1_202h 64;
BA_ "E2EProfile" SG_ 514 ADS_RollgCntr1_202h "P01";
BA_ "E2EDataId" SG_ 514 ADS_RollgCntr1_202h 255;
BA_ "GenSigSendType" SG_ 514 ADS_RollgCntr1_202h 0;
BA_ "E2EDataLength" SG_ 514 ADS_Resd1_202h 64;
BA_ "E2EProfile" SG_ 514 ADS_Resd1_202h "P01";
BA_ "E2EDataId" SG_ 514 ADS_Resd1_202h 255;
BA_ "GenSigSendType" SG_ 514 ADS_Resd1_202h 0;
BA_ "E2EDataLength" SG_ 514 ADS_AdsFault_202h 64;
BA_ "E2EProfile" SG_ 514 ADS_AdsFault_202h "P01";
BA_ "E2EDataId" SG_ 514 ADS_AdsFault_202h 255;
BA_ "GRC_Sig_ASIL" SG_ 514 ADS_AdsFault_202h 0;
BA_ "GenSigSendType" SG_ 514 ADS_AdsFault_202h 0;
BA_ "E2EDataLength" SG_ 514 ADS_NicaReminderLEDVisual_202h 64;
BA_ "E2EProfile" SG_ 514 ADS_NicaReminderLEDVisual_202h "P01";
BA_ "E2EDataId" SG_ 514 ADS_NicaReminderLEDVisual_202h 255;
BA_ "GRC_Sig_ASIL" SG_ 514 ADS_NicaReminderLEDVisual_202h 0;
BA_ "GenSigSendType" SG_ 514 ADS_NicaReminderLEDVisual_202h 0;
BA_ "E2EDataLength" SG_ 514 ADS_NicaReminderAcoustic_202h 64;
BA_ "E2EProfile" SG_ 514 ADS_NicaReminderAcoustic_202h "P01";
BA_ "E2EDataId" SG_ 514 ADS_NicaReminderAcoustic_202h 255;
BA_ "GRC_Sig_ASIL" SG_ 514 ADS_NicaReminderAcoustic_202h 1;
BA_ "GenSigSendType" SG_ 514 ADS_NicaReminderAcoustic_202h 0;
BA_ "E2EDataLength" SG_ 514 ADS_TakeoverID_202h 64;
BA_ "E2EProfile" SG_ 514 ADS_TakeoverID_202h "P01";
BA_ "E2EDataId" SG_ 514 ADS_TakeoverID_202h 255;
BA_ "GRC_Sig_ASIL" SG_ 514 ADS_TakeoverID_202h 1;
BA_ "GenSigSendType" SG_ 514 ADS_TakeoverID_202h 0;
BA_ "E2EDataLength" SG_ 514 ADS_TakeoverLevel_202h 64;
BA_ "E2EProfile" SG_ 514 ADS_TakeoverLevel_202h "P01";
BA_ "E2EDataId" SG_ 514 ADS_TakeoverLevel_202h 255;
BA_ "GRC_Sig_ASIL" SG_ 514 ADS_TakeoverLevel_202h 1;
BA_ "GenSigSendType" SG_ 514 ADS_TakeoverLevel_202h 0;
BA_ "E2EDataLength" SG_ 514 ADS_TakeoverType_202h 64;
BA_ "E2EProfile" SG_ 514 ADS_TakeoverType_202h "P01";
BA_ "E2EDataId" SG_ 514 ADS_TakeoverType_202h 255;
BA_ "GRC_Sig_ASIL" SG_ 514 ADS_TakeoverType_202h 1;
BA_ "GenSigSendType" SG_ 514 ADS_TakeoverType_202h 0;
BA_ "E2EDataLength" SG_ 514 ADS_TORIDCorrespErrorID_202h 64;
BA_ "E2EProfile" SG_ 514 ADS_TORIDCorrespErrorID_202h "P01";
BA_ "E2EDataId" SG_ 514 ADS_TORIDCorrespErrorID_202h 255;
BA_ "GRC_Sig_ASIL" SG_ 514 ADS_TORIDCorrespErrorID_202h 1;
BA_ "GenSigSendType" SG_ 514 ADS_TORIDCorrespErrorID_202h 0;
BA_ "GenSigSendType" SG_ 514 ADS_CRC2_202h 0;
BA_ "GenSigSendType" SG_ 514 ADS_RollgCntr2_202h 0;
BA_ "GenSigSendType" SG_ 514 ADS_Resd2_202h 0;
BA_ "GRC_Sig_ASIL" SG_ 514 ADS_TakeoverExtended16bit_202h 1;
BA_ "GenSigSendType" SG_ 514 ADS_TakeoverExtended16bit_202h 0;
BA_ "GRC_Sig_ASIL" SG_ 514 ADS_TakeoverExtended8bit_202h 1;
BA_ "GenSigSendType" SG_ 514 ADS_TakeoverExtended8bit_202h 0;
BA_ "GenSigSendType" SG_ 1041 ADS_CRC1_411h 0;
BA_ "GenSigSendType" SG_ 1041 ADS_RollgCntr1_411h 0;
BA_ "GenSigSendType" SG_ 1041 ADS_Resd1_411h 0;
BA_ "GenSigSendType" SG_ 1041 ADS_RadarWarning0Distance_411h 0;
BA_ "GenSigSendType" SG_ 1041 ADS_RadarWarning1Distance_411h 0;
BA_ "GenSigSendType" SG_ 1041 ADS_RadarWarning2Distance_411h 0;
BA_ "GenSigSendType" SG_ 1041 ADS_RadarWarning3Distance_411h 0;
BA_ "GenSigSendType" SG_ 1041 ADS_RadarWarning4Distance_411h 0;
BA_ "GenSigSendType" SG_ 1041 ADS_RadarWarning5Distance_411h 0;
BA_ "GenSigSendType" SG_ 1041 ADS_CRC2_411h 0;
BA_ "GenSigSendType" SG_ 1041 ADS_RollgCntr2_411h 0;
BA_ "GenSigSendType" SG_ 1041 ADS_Resd2_411h 0;
BA_ "GenSigSendType" SG_ 1041 ADS_RadarWarning6Distance_411h 0;
BA_ "GenSigSendType" SG_ 1041 ADS_RadarWarning7Distance_411h 0;
BA_ "GenSigSendType" SG_ 1041 ADS_RadarWarning8Distance_411h 0;
BA_ "GenSigSendType" SG_ 1041 ADS_RadarWarning9Distance_411h 0;
BA_ "GenSigSendType" SG_ 1041 ADS_RadarWarning10Distance_411h 0;
BA_ "GenSigSendType" SG_ 1041 ADS_RadarWarning11Distance_411h 0;
BA_ "GenSigSendType" SG_ 1041 ADS_CRC3_411h 0;
BA_ "GenSigSendType" SG_ 1041 ADS_RollgCntr3_411h 0;
BA_ "GenSigSendType" SG_ 1041 ADS_Resd3_411h 0;
BA_ "GenSigSendType" SG_ 1041 ADS_RadarWarning12Distance_411h 0;
BA_ "GenSigSendType" SG_ 1041 ADS_RadarWarning13Distance_411h 0;
BA_ "GenSigSendType" SG_ 1041 ADS_RadarWarning14Distance_411h 0;
BA_ "GenSigSendType" SG_ 1041 ADS_RadarWarning15Distance_411h 0;
BA_ "GenSigSendType" SG_ 1041 ADS_RadarWarning0AcLvl_411h 0;
BA_ "GenSigSendType" SG_ 1041 ADS_RadarWarning1AcLvl_411h 0;
BA_ "GenSigSendType" SG_ 1041 ADS_RadarWarning2AcLvl_411h 0;
BA_ "GenSigSendType" SG_ 1041 ADS_RadarWarning3AcLvl_411h 0;
BA_ "GenSigSendType" SG_ 1041 ADS_RadarWarning4AcLvl_411h 0;
BA_ "GenSigSendType" SG_ 1041 ADS_CRC4_411h 0;
BA_ "GenSigSendType" SG_ 1041 ADS_RollgCntr4_411h 0;
BA_ "GenSigSendType" SG_ 1041 ADS_Resd4_411h 0;
BA_ "GenSigSendType" SG_ 1041 ADS_RadarWarning5AcLvl_411h 0;
BA_ "GenSigSendType" SG_ 1041 ADS_RadarWarning6AcLvl_411h 0;
BA_ "GenSigSendType" SG_ 1041 ADS_RadarWarning7AcLvl_411h 0;
BA_ "GenSigSendType" SG_ 1041 ADS_RadarWarning8AcLvl_411h 0;
BA_ "GenSigSendType" SG_ 1041 ADS_RadarWarning9AcLvl_411h 0;
BA_ "GenSigSendType" SG_ 1041 ADS_RadarWarning10AcLvl_411h 0;
BA_ "GenSigSendType" SG_ 1041 ADS_RadarWarning11AcLvl_411h 0;
BA_ "GenSigSendType" SG_ 1041 ADS_RadarWarning12AcLvl_411h 0;
BA_ "GenSigSendType" SG_ 1041 ADS_RadarWarning13AcLvl_411h 0;
BA_ "GenSigSendType" SG_ 1041 ADS_RadarWarning14AcLvl_411h 0;
BA_ "GenSigSendType" SG_ 1041 ADS_RadarWarning15AcLvl_411h 0;
BA_ "GenSigSendType" SG_ 1041 ADC_FuncReq_SentryModWarn_411h 0;
BA_ "GenSigSendType" SG_ 1041 ADC_FuncReq_SentryModDetec_411h 0;
BA_ "GenSigSendType" SG_ 1041 ADC_MdcSentryAlarmMod_411h 0;
BA_ "GenSigSendType" SG_ 769 ADS_CRC1_301h 0;
BA_ "GenSigSendType" SG_ 769 ADS_RollgCntr1_301h 0;
BA_ "GenSigSendType" SG_ 769 ADS_Resd1_301h 0;
BA_ "GRC_Sig_ASIL" SG_ 769 ADS_AccFunctionStatus_301h 1;
BA_ "GenSigSendType" SG_ 769 ADS_AccFunctionStatus_301h 0;
BA_ "GRC_Sig_ASIL" SG_ 769 ADS_LccNcaFunctionStatus_301h 1;
BA_ "GenSigSendType" SG_ 769 ADS_LccNcaFunctionStatus_301h 0;
BA_ "GRC_Sig_ASIL" SG_ 769 ADS_AdsFucntionNotActive_301h 1;
BA_ "GenSigSendType" SG_ 769 ADS_AdsFucntionNotActive_301h 0;
BA_ "GRC_Sig_ASIL" SG_ 769 ADS_AvpFunctionStatus_301h 1;
BA_ "GenSigSendType" SG_ 769 ADS_AvpFunctionStatus_301h 0;
BA_ "GRC_Sig_ASIL" SG_ 769 ADS_SpeedSetByDriver_301h 1;
BA_ "GenSigSendType" SG_ 769 ADS_SpeedSetByDriver_301h 0;
BA_ "GRC_Sig_ASIL" SG_ 769 ADS_SpeedLimitValue_301h 1;
BA_ "GenSigSendType" SG_ 769 ADS_SpeedLimitValue_301h 0;
BA_ "GRC_Sig_ASIL" SG_ 769 ADS_SpeedAutoFollow_301h 1;
BA_ "GenSigSendType" SG_ 769 ADS_SpeedAutoFollow_301h 0;
BA_ "GRC_Sig_ASIL" SG_ 769 ADS_OneTouchSpeedAdjustment_301h 1;
BA_ "GenSigSendType" SG_ 769 ADS_OneTouchSpeedAdjustment_301h 0;
BA_ "GRC_Sig_ASIL" SG_ 769 ADS_CalibState_301h 1;
BA_ "GenSigSendType" SG_ 769 ADS_CalibState_301h 0;
BA_ "GRC_Sig_ASIL" SG_ 769 ADS_HODReminder_301h 1;
BA_ "GenSigSendType" SG_ 769 ADS_HODReminder_301h 0;
BA_ "GenSigSendType" SG_ 769 ADS_CRC2_301h 0;
BA_ "GenSigSendType" SG_ 769 ADS_RollgCntr2_301h 0;
BA_ "GenSigSendType" SG_ 769 ADS_Resd2_301h 0;
BA_ "GRC_Sig_ASIL" SG_ 769 ADS_DMSReminder_301h 1;
BA_ "GenSigSendType" SG_ 769 ADS_DMSReminder_301h 0;
BA_ "GRC_Sig_ASIL" SG_ 769 ADS_FcwWaning_301h 1;
BA_ "GenSigSendType" SG_ 769 ADS_FcwWaning_301h 0;
BA_ "GRC_Sig_ASIL" SG_ 769 ADS_FcwFault_301h 1;
BA_ "GenSigSendType" SG_ 769 ADS_FcwFault_301h 0;
BA_ "GRC_Sig_ASIL" SG_ 769 ADS_AebWaning_301h 1;
BA_ "GenSigSendType" SG_ 769 ADS_AebWaning_301h 0;
BA_ "GRC_Sig_ASIL" SG_ 769 ADS_AebFault_301h 1;
BA_ "GenSigSendType" SG_ 769 ADS_AebFault_301h 0;
BA_ "GRC_Sig_ASIL" SG_ 769 ADS_AebObjType_301h 1;
BA_ "GenSigSendType" SG_ 769 ADS_AebObjType_301h 0;
BA_ "GRC_Sig_ASIL" SG_ 769 ADS_RaebWarning_301h 1;
BA_ "GenSigSendType" SG_ 769 ADS_RaebWarning_301h 0;
BA_ "GRC_Sig_ASIL" SG_ 769 ADS_RaebFault_301h 1;
BA_ "GenSigSendType" SG_ 769 ADS_RaebFault_301h 0;
BA_ "GRC_Sig_ASIL" SG_ 769 ADS_RcwWarning_301h 1;
BA_ "GenSigSendType" SG_ 769 ADS_RcwWarning_301h 0;
BA_ "GRC_Sig_ASIL" SG_ 769 ADS_RcwFault_301h 1;
BA_ "GenSigSendType" SG_ 769 ADS_RcwFault_301h 0;
BA_ "GRC_Sig_ASIL" SG_ 769 ADS_FctaLeftWarning_301h 1;
BA_ "GenSigSendType" SG_ 769 ADS_FctaLeftWarning_301h 0;
BA_ "GRC_Sig_ASIL" SG_ 769 ADS_FctaRightWarning_301h 1;
BA_ "GenSigSendType" SG_ 769 ADS_FctaRightWarning_301h 0;
BA_ "GRC_Sig_ASIL" SG_ 769 ADS_FctbLeftWarning_301h 1;
BA_ "GenSigSendType" SG_ 769 ADS_FctbLeftWarning_301h 0;
BA_ "GRC_Sig_ASIL" SG_ 769 ADS_FctbRightWarning_301h 1;
BA_ "GenSigSendType" SG_ 769 ADS_FctbRightWarning_301h 0;
BA_ "GRC_Sig_ASIL" SG_ 769 ADS_RctaLeftWarning_301h 1;
BA_ "GenSigSendType" SG_ 769 ADS_RctaLeftWarning_301h 0;
BA_ "GRC_Sig_ASIL" SG_ 769 ADS_RctaRightWarning_301h 1;
BA_ "GenSigSendType" SG_ 769 ADS_RctaRightWarning_301h 0;
BA_ "GRC_Sig_ASIL" SG_ 769 ADS_RctaFault_301h 1;
BA_ "GenSigSendType" SG_ 769 ADS_RctaFault_301h 0;
BA_ "GenSigSendType" SG_ 769 ADS_CRC3_301h 0;
BA_ "GenSigSendType" SG_ 769 ADS_RollgCntr3_301h 0;
BA_ "GenSigSendType" SG_ 769 ADS_Resd3_301h 0;
BA_ "GRC_Sig_ASIL" SG_ 769 ADS_RctbLeftWarning_301h 1;
BA_ "GenSigSendType" SG_ 769 ADS_RctbLeftWarning_301h 0;
BA_ "GRC_Sig_ASIL" SG_ 769 ADS_RctbRightWarning_301h 1;
BA_ "GenSigSendType" SG_ 769 ADS_RctbRightWarning_301h 0;
BA_ "GRC_Sig_ASIL" SG_ 769 ADS_LdwWarning_301h 1;
BA_ "GenSigSendType" SG_ 769 ADS_LdwWarning_301h 0;
BA_ "GRC_Sig_ASIL" SG_ 769 ADS_LdwFault_301h 1;
BA_ "GenSigSendType" SG_ 769 ADS_LdwFault_301h 0;
BA_ "GRC_Sig_ASIL" SG_ 769 ADS_LKAWarning_301h 1;
BA_ "GenSigSendType" SG_ 769 ADS_LKAWarning_301h 0;
BA_ "GRC_Sig_ASIL" SG_ 769 ADS_LkaFault_301h 1;
BA_ "GenSigSendType" SG_ 769 ADS_LkaFault_301h 0;
BA_ "GRC_Sig_ASIL" SG_ 769 ADS_LeftMirrWarningCmd_301h 1;
BA_ "GenSigSendType" SG_ 769 ADS_LeftMirrWarningCmd_301h 0;
BA_ "GRC_Sig_ASIL" SG_ 769 ADS_RightMirrWarningCmd_301h 1;
BA_ "GenSigSendType" SG_ 769 ADS_RightMirrWarningCmd_301h 0;
BA_ "GRC_Sig_ASIL" SG_ 769 ADS_BsdFault_301h 1;
BA_ "GenSigSendType" SG_ 769 ADS_BsdFault_301h 0;
BA_ "GRC_Sig_ASIL" SG_ 769 ADS_LeFrntDoorWarningCmd_301h 1;
BA_ "GenSigSendType" SG_ 769 ADS_LeFrntDoorWarningCmd_301h 0;
BA_ "GRC_Sig_ASIL" SG_ 769 ADS_LeReDoorWarningCmd_301h 1;
BA_ "GenSigSendType" SG_ 769 ADS_LeReDoorWarningCmd_301h 0;
BA_ "GRC_Sig_ASIL" SG_ 769 ADS_RiFrntDoorWarningCmd_301h 1;
BA_ "GenSigSendType" SG_ 769 ADS_RiFrntDoorWarningCmd_301h 0;
BA_ "GRC_Sig_ASIL" SG_ 769 ADS_RiReDoorWarningCmd_301h 1;
BA_ "GenSigSendType" SG_ 769 ADS_RiReDoorWarningCmd_301h 0;
BA_ "GRC_Sig_ASIL" SG_ 769 ADS_DowFault_301h 1;
BA_ "GenSigSendType" SG_ 769 ADS_DowFault_301h 0;
BA_ "GRC_Sig_ASIL" SG_ 769 ADS_SpeedLimitWarning_301h 1;
BA_ "GenSigSendType" SG_ 769 ADS_SpeedLimitWarning_301h 0;
BA_ "GRC_Sig_ASIL" SG_ 769 ADS_TsrFault_301h 1;
BA_ "GenSigSendType" SG_ 769 ADS_TsrFault_301h 0;
BA_ "GRC_Sig_ASIL" SG_ 769 ADS_TlaFault_301h 1;
BA_ "GenSigSendType" SG_ 769 ADS_TlaFault_301h 0;
BA_ "GRC_Sig_ASIL" SG_ 769 ADS_ElkaFault_301h 1;
BA_ "GenSigSendType" SG_ 769 ADS_ElkaFault_301h 0;
BA_ "GenSigSendType" SG_ 769 ADS_CRC4_301h 0;
BA_ "GenSigSendType" SG_ 769 ADS_RollgCntr4_301h 0;
BA_ "GenSigSendType" SG_ 769 ADS_Resd4_301h 0;
BA_ "GRC_Sig_ASIL" SG_ 769 ADS_AbsoultwSpeedLimit_301h 1;
BA_ "GenSigSendType" SG_ 769 ADS_AbsoultwSpeedLimit_301h 0;
BA_ "GRC_Sig_ASIL" SG_ 769 ADS_TlaWarning_301h 1;
BA_ "GenSigSendType" SG_ 769 ADS_TlaWarning_301h 0;
BA_ "GRC_Sig_ASIL" SG_ 769 ADS_ElkaWarning_301h 1;
BA_ "GenSigSendType" SG_ 769 ADS_ElkaWarning_301h 0;
BA_ "E2EDataLength" SG_ 1042 New_Signal_412_1 64;
BA_ "E2EProfile" SG_ 1042 New_Signal_412_1 "P01";
BA_ "E2EDataId" SG_ 1042 New_Signal_412_1 479;
BA_ "GenSigSendType" SG_ 1042 New_Signal_412_1 0;
BA_ "E2EDataLength" SG_ 1042 ADS_CRC1_412h 64;
BA_ "E2EProfile" SG_ 1042 ADS_CRC1_412h "P01";
BA_ "E2EDataId" SG_ 1042 ADS_CRC1_412h 479;
BA_ "GenSigSendType" SG_ 1042 ADS_CRC1_412h 0;
BA_ "E2EDataLength" SG_ 1042 ADS_RollgCntr1_412h 64;
BA_ "E2EProfile" SG_ 1042 ADS_RollgCntr1_412h "P01";
BA_ "E2EDataId" SG_ 1042 ADS_RollgCntr1_412h 479;
BA_ "GenSigSendType" SG_ 1042 ADS_RollgCntr1_412h 0;
BA_ "E2EDataLength" SG_ 1042 ADS_Resd1_412h 64;
BA_ "E2EProfile" SG_ 1042 ADS_Resd1_412h "P01";
BA_ "E2EDataId" SG_ 1042 ADS_Resd1_412h 479;
BA_ "GenSigSendType" SG_ 1042 ADS_Resd1_412h 0;
BA_ "E2EDataLength" SG_ 1042 ADS_BrkBeamReq_412h 64;
BA_ "E2EProfile" SG_ 1042 ADS_BrkBeamReq_412h "P01";
BA_ "E2EDataId" SG_ 1042 ADS_BrkBeamReq_412h 479;
BA_ "GRC_Sig_ASIL" SG_ 1042 ADS_BrkBeamReq_412h 3;
BA_ "GenSigSendType" SG_ 1042 ADS_BrkBeamReq_412h 0;
BA_ "E2EDataLength" SG_ 1042 ADS_AutoLightSwCtrl_412h 64;
BA_ "E2EProfile" SG_ 1042 ADS_AutoLightSwCtrl_412h "P01";
BA_ "E2EDataId" SG_ 1042 ADS_AutoLightSwCtrl_412h 479;
BA_ "GenSigSendType" SG_ 1042 ADS_AutoLightSwCtrl_412h 0;
BA_ "E2EDataLength" SG_ 1042 ADS_LeFrntDowWarning_412h 64;
BA_ "E2EProfile" SG_ 1042 ADS_LeFrntDowWarning_412h "P01";
BA_ "E2EDataId" SG_ 1042 ADS_LeFrntDowWarning_412h 479;
BA_ "GRC_Sig_ASIL" SG_ 1042 ADS_LeFrntDowWarning_412h 1;
BA_ "GenSigSendType" SG_ 1042 ADS_LeFrntDowWarning_412h 0;
BA_ "E2EDataLength" SG_ 1042 ADS_RiFrntDowWarning_412h 64;
BA_ "E2EProfile" SG_ 1042 ADS_RiFrntDowWarning_412h "P01";
BA_ "E2EDataId" SG_ 1042 ADS_RiFrntDowWarning_412h 479;
BA_ "GRC_Sig_ASIL" SG_ 1042 ADS_RiFrntDowWarning_412h 1;
BA_ "GenSigSendType" SG_ 1042 ADS_RiFrntDowWarning_412h 0;
BA_ "E2EDataLength" SG_ 1042 ADS_LeReDowWarning_412h 64;
BA_ "E2EProfile" SG_ 1042 ADS_LeReDowWarning_412h "P01";
BA_ "E2EDataId" SG_ 1042 ADS_LeReDowWarning_412h 479;
BA_ "GRC_Sig_ASIL" SG_ 1042 ADS_LeReDowWarning_412h 1;
BA_ "GenSigSendType" SG_ 1042 ADS_LeReDowWarning_412h 0;
BA_ "E2EDataLength" SG_ 1042 ADS_RiReDowWarning_412h 64;
BA_ "E2EProfile" SG_ 1042 ADS_RiReDowWarning_412h "P01";
BA_ "E2EDataId" SG_ 1042 ADS_RiReDowWarning_412h 479;
BA_ "GRC_Sig_ASIL" SG_ 1042 ADS_RiReDowWarning_412h 1;
BA_ "GenSigSendType" SG_ 1042 ADS_RiReDowWarning_412h 0;
BA_ "E2EDataLength" SG_ 1042 ADS_LeftMirrWarningCmd_412h 64;
BA_ "E2EProfile" SG_ 1042 ADS_LeftMirrWarningCmd_412h "P01";
BA_ "E2EDataId" SG_ 1042 ADS_LeftMirrWarningCmd_412h 479;
BA_ "GRC_Sig_ASIL" SG_ 1042 ADS_LeftMirrWarningCmd_412h 1;
BA_ "GenSigSendType" SG_ 1042 ADS_LeftMirrWarningCmd_412h 0;
BA_ "E2EDataLength" SG_ 1042 ADS_RightMirrWarningCmd_412h 64;
BA_ "E2EProfile" SG_ 1042 ADS_RightMirrWarningCmd_412h "P01";
BA_ "E2EDataId" SG_ 1042 ADS_RightMirrWarningCmd_412h 479;
BA_ "GRC_Sig_ASIL" SG_ 1042 ADS_RightMirrWarningCmd_412h 1;
BA_ "GenSigSendType" SG_ 1042 ADS_RightMirrWarningCmd_412h 0;
BA_ "E2EDataLength" SG_ 1042 ADS_ReMirrReq_412h 64;
BA_ "E2EProfile" SG_ 1042 ADS_ReMirrReq_412h "P01";
BA_ "E2EDataId" SG_ 1042 ADS_ReMirrReq_412h 479;
BA_ "GRC_Sig_ASIL" SG_ 1042 ADS_ReMirrReq_412h 1;
BA_ "GenSigSendType" SG_ 1042 ADS_ReMirrReq_412h 0;
BA_ "E2EDataLength" SG_ 1042 ADS_DoorLockReq_412h 64;
BA_ "E2EProfile" SG_ 1042 ADS_DoorLockReq_412h "P01";
BA_ "E2EDataId" SG_ 1042 ADS_DoorLockReq_412h 479;
BA_ "GRC_Sig_ASIL" SG_ 1042 ADS_DoorLockReq_412h 1;
BA_ "GenSigSendType" SG_ 1042 ADS_DoorLockReq_412h 0;
BA_ "E2EDataLength" SG_ 1042 ADS_SBeltControl_412h 64;
BA_ "E2EProfile" SG_ 1042 ADS_SBeltControl_412h "P01";
BA_ "E2EDataId" SG_ 1042 ADS_SBeltControl_412h 479;
BA_ "GRC_Sig_ASIL" SG_ 1042 ADS_SBeltControl_412h 1;
BA_ "GenSigSendType" SG_ 1042 ADS_SBeltControl_412h 0;
BA_ "E2EDataLength" SG_ 1042 ADS_WshrReq_412h 64;
BA_ "E2EProfile" SG_ 1042 ADS_WshrReq_412h "P01";
BA_ "E2EDataId" SG_ 1042 ADS_WshrReq_412h 479;
BA_ "GRC_Sig_ASIL" SG_ 1042 ADS_WshrReq_412h 1;
BA_ "GenSigSendType" SG_ 1042 ADS_WshrReq_412h 0;
BA_ "E2EDataLength" SG_ 1042 ADS_SeatShakeControl_412h 64;
BA_ "E2EProfile" SG_ 1042 ADS_SeatShakeControl_412h "P01";
BA_ "E2EDataId" SG_ 1042 ADS_SeatShakeControl_412h 479;
BA_ "GenSigSendType" SG_ 1042 ADS_SeatShakeControl_412h 0;
BA_ "E2EDataLength" SG_ 1042 ADS_FrtWindshildHeatReq_412h 64;
BA_ "E2EProfile" SG_ 1042 ADS_FrtWindshildHeatReq_412h "P01";
BA_ "E2EDataId" SG_ 1042 ADS_FrtWindshildHeatReq_412h 479;
BA_ "GRC_Sig_ASIL" SG_ 1042 ADS_FrtWindshildHeatReq_412h 1;
BA_ "GenSigSendType" SG_ 1042 ADS_FrtWindshildHeatReq_412h 0;
BA_ "E2EDataLength" SG_ 1042 ADS_HornReq_412h 64;
BA_ "E2EProfile" SG_ 1042 ADS_HornReq_412h "P01";
BA_ "E2EDataId" SG_ 1042 ADS_HornReq_412h 479;
BA_ "GRC_Sig_ASIL" SG_ 1042 ADS_HornReq_412h 1;
BA_ "GenSigSendType" SG_ 1042 ADS_HornReq_412h 0;
BA_ "E2EDataLength" SG_ 1042 ADS_LeFmtWinCtrl_412h 64;
BA_ "E2EProfile" SG_ 1042 ADS_LeFmtWinCtrl_412h "P01";
BA_ "E2EDataId" SG_ 1042 ADS_LeFmtWinCtrl_412h 479;
BA_ "GRC_Sig_ASIL" SG_ 1042 ADS_LeFmtWinCtrl_412h 1;
BA_ "GenSigSendType" SG_ 1042 ADS_LeFmtWinCtrl_412h 0;
BA_ "E2EDataLength" SG_ 1042 ADS_RiFmtWinCtrl_412h 64;
BA_ "E2EProfile" SG_ 1042 ADS_RiFmtWinCtrl_412h "P01";
BA_ "E2EDataId" SG_ 1042 ADS_RiFmtWinCtrl_412h 479;
BA_ "GRC_Sig_ASIL" SG_ 1042 ADS_RiFmtWinCtrl_412h 1;
BA_ "GenSigSendType" SG_ 1042 ADS_RiFmtWinCtrl_412h 0;
BA_ "E2EDataLength" SG_ 1042 ADS_LeReWinCtrl_412h 64;
BA_ "E2EProfile" SG_ 1042 ADS_LeReWinCtrl_412h "P01";
BA_ "E2EDataId" SG_ 1042 ADS_LeReWinCtrl_412h 479;
BA_ "GRC_Sig_ASIL" SG_ 1042 ADS_LeReWinCtrl_412h 1;
BA_ "GenSigSendType" SG_ 1042 ADS_LeReWinCtrl_412h 0;
BA_ "E2EDataLength" SG_ 1042 ADS_RiReWinCtrl_412h 64;
BA_ "E2EProfile" SG_ 1042 ADS_RiReWinCtrl_412h "P01";
BA_ "E2EDataId" SG_ 1042 ADS_RiReWinCtrl_412h 479;
BA_ "GRC_Sig_ASIL" SG_ 1042 ADS_RiReWinCtrl_412h 1;
BA_ "GenSigSendType" SG_ 1042 ADS_RiReWinCtrl_412h 0;
BA_ "E2EDataLength" SG_ 1042 ADS_TopWinCtrl_412h 64;
BA_ "E2EProfile" SG_ 1042 ADS_TopWinCtrl_412h "P01";
BA_ "E2EDataId" SG_ 1042 ADS_TopWinCtrl_412h 479;
BA_ "GRC_Sig_ASIL" SG_ 1042 ADS_TopWinCtrl_412h 1;
BA_ "GenSigSendType" SG_ 1042 ADS_TopWinCtrl_412h 0;
BA_ "GRC_Sig_ASIL" SG_ 1042 ADS_FrontWiperReq_412h 1;
BA_ "GenSigSendType" SG_ 1042 ADS_FrontWiperReq_412h 0;
BA_ "E2EDataId" SG_ 1042 ADS_ChargingPortCmd_412h 479;
BA_ "GenSigSendType" SG_ 1042 ADS_ChargingPortCmd_412h 0;
BA_ "E2EDataLength" SG_ 1042 ADAS_FctSts_412h 64;
BA_ "E2EProfile" SG_ 1042 ADAS_FctSts_412h "P01";
BA_ "E2EDataId" SG_ 1042 ADAS_FctSts_412h 479;
BA_ "GenSigSendType" SG_ 1042 ADAS_FctSts_412h 0;
BA_ "E2EDataLength" SG_ 1042 ADS_MdcCrtSts_412h 64;
BA_ "E2EProfile" SG_ 1042 ADS_MdcCrtSts_412h "P01";
BA_ "E2EDataId" SG_ 1042 ADS_MdcCrtSts_412h 479;
BA_ "GenSigSendType" SG_ 1042 ADS_MdcCrtSts_412h 0;
BA_ "GenSigInvalidValue" SG_ 1042 ADS_MdcCrtSts_412h 7;
BA_ "GenSigSendType" SG_ 1042 ADS_CRC2_412h 0;
BA_ "GenSigSendType" SG_ 1042 ADS_RollgCntr2_412h 0;
BA_ "GenSigSendType" SG_ 1042 ADS_Resd2_412h 0;
BA_ "GenSigSendType" SG_ 1042 ADS_HVCtrlReq_412h 0;
BA_ "GenSigSendType" SG_ 1042 ADS_ThmPostRun_412h 0;
BA_ "GenSigSendType" SG_ 1042 ADS_FlowReq_412h 0;
BA_ "GenSigInvalidValue" SG_ 1042 ADS_FlowReq_412h 15;
BA_ "GenSigSendType" SG_ 1042 ADS_PwrOnOffReq_412h 0;
BA_ "GenSigSendType" SG_ 1042 ADS_hmaOnOffSts_412h 0;
BA_ "GenSigSendType" SG_ 1042 ADS_HMAStatus_412h 0;
BA_ "GenSigSendType" SG_ 1042 ADS_HiBeamReq_412h 0;
BA_ "GenSigSendType" SG_ 290 Fusa_122_3 0;
BA_ "GenSigSendType" SG_ 290 Fusa_122_2 0;
BA_ "GenSigSendType" SG_ 290 Fusa_122_1 0;
BA_ "GenSigSendType" SG_ 290 EPS_1_CRC 0;
BA_ "E2EDataId" SG_ 290 EPS_1_CRC 46;
BA_ "E2EProfile" SG_ 290 EPS_1_CRC "P01";
BA_ "E2EDataLength" SG_ 290 EPS_1_CRC 64;
BA_ "GenSigSendType" SG_ 290 EPS_1_RollgCntr 0;
BA_ "E2EDataId" SG_ 290 EPS_1_RollgCntr 46;
BA_ "E2EProfile" SG_ 290 EPS_1_RollgCntr "P01";
BA_ "E2EDataLength" SG_ 290 EPS_1_RollgCntr 64;
BA_ "GRC_Sig_ASIL" SG_ 290 EPSFailSts 3;
BA_ "GenSigSendType" SG_ 290 EPSFailSts 0;
BA_ "E2EDataId" SG_ 290 EPSFailSts 46;
BA_ "E2EProfile" SG_ 290 EPSFailSts "P01";
BA_ "E2EDataLength" SG_ 290 EPSFailSts 64;
BA_ "GenSigSendType" SG_ 290 EPSSteeringAngleCalibrationSts 0;
BA_ "E2EDataId" SG_ 290 EPSSteeringAngleCalibrationSts 46;
BA_ "E2EProfile" SG_ 290 EPSSteeringAngleCalibrationSts "P01";
BA_ "E2EDataLength" SG_ 290 EPSSteeringAngleCalibrationSts 64;
BA_ "GenSigSendType" SG_ 290 EPS_EOTLearning_Sts 0;
BA_ "E2EDataId" SG_ 290 EPS_EOTLearning_Sts 46;
BA_ "E2EProfile" SG_ 290 EPS_EOTLearning_Sts "P01";
BA_ "E2EDataLength" SG_ 290 EPS_EOTLearning_Sts 64;
BA_ "GRC_Sig_ASIL" SG_ 1046 LBMS_LoWSocFlt 3;
BA_ "GenSigSendType" SG_ 1046 LBMS_LoWSocFlt 0;
BA_ "GRC_Sig_ASIL" SG_ 1046 LBMS_ThermRunawayFlt 3;
BA_ "GenSigSendType" SG_ 1046 LBMS_ThermRunawayFlt 0;
BA_ "GRC_Sig_ASIL" SG_ 1046 LBMS_SysFlt 3;
BA_ "GenSigSendType" SG_ 1046 LBMS_SysFlt 0;
BA_ "GRC_Sig_ASIL" SG_ 1046 LBMS_LowPowerRemind 3;
BA_ "GenSigSendType" SG_ 1046 LBMS_LowPowerRemind 0;
BA_ "GRC_Sig_ASIL" SG_ 1046 LBMS_EndLifeFlt 3;
BA_ "GenSigSendType" SG_ 1046 LBMS_EndLifeFlt 0;
VAL_ 1096 TMS_AirPurgeReminderSts 0 "Not_Active" 1 "ON" 2 "OFF" 3 "Not_Used" ;
VAL_ 1096 TMS_BT_Reduce_Wind_SpeedSts 0 "Off" 1 "Active" ;
VAL_ 1096 TMS_First_BlowingSts 0 "Off" 1 "Active" ;
VAL_ 1096 TMS_CirculationInTunnelsSts 0 "Off" 1 "Active" ;
VAL_ 1096 TMS_crosscountry_coolingSts 0 "No_Request" 1 "Active" 2 "Not_Active" ;
VAL_ 1096 TMS_ParkingAirConditioningStatus 0 "Inactive" 1 "AUTO" 2 "ventilate" ;
VAL_ 1096 TMS_CoolantFillSts 0 "No_Request" 1 "Request" ;
VAL_ 1096 TMS_UVC_ControlSts 0 "No_Request" 1 "Close_Request" 2 "Open_Request" 3 "AUTO" ;
VAL_ 1096 TMS_AutoDefogActiveSts 0 "Off" 1 "On" ;
VAL_ 1096 TMS_UVC_LuminanceSts 0 "No_Request" 1 "level_1" 2 "level_2" 3 "Reserved" 4 "Reserved" 5 "Reserved" 6 "Reserved" 7 "Reserved" ;
VAL_ 1096 TMS_ICC_Lightoff_Sts 0 "No_Request" 1 "FraganceLight_on_Sts" 2 "FraganceLight_off_Sts" 3 "Reserved" ;
VAL_ 1096 TMS_ICC_Memoff_Sts 0 "No_Request" 1 "FraganceMem_on" 2 "FraganceMem_off" 3 "Reserved" ;
VAL_ 1096 TMS_keepwarmSet_TemperatureSts 0 "Temperature_20°C" 1 "Temperature_25°C" 2 "Temperature_30°C" 3 "Temperature_35°C" 4 "Temperature_40°C" 5 "Temperature_45°C" 6 "Temperature_50°C" 7 "Temperature_55°C" 8 "Temperature_60°C" 9 "reserved" 10 "reserved" 11 "reserved" 12 "reserved" 13 "reserved" 14 "reserved" 15 "reserved" 16 "reserved" 17 "reserved" 18 "reserved" 19 "reserved" 20 "reserved" 21 "reserved" 22 "reserved" 23 "reserved" 24 "reserved" 25 "reserved" 26 "reserved" 27 "reserved" 28 "reserved" 29 "reserved" 30 "reserved" 31 "reserved" 32 "reserved" 33 "reserved" 34 "reserved" 35 "reserved" 36 "reserved" 37 "reserved" 38 "reserved" 39 "reserved" 40 "reserved" 41 "reserved" 42 "reserved" 43 "reserved" 44 "reserved" 45 "reserved" 46 "reserved" 47 "reserved" 48 "reserved" 49 "reserved" 50 "reserved" 51 "reserved" 52 "reserved" 53 "reserved" 54 "reserved" 55 "reserved" 56 "reserved" 57 "reserved" 58 "reserved" 59 "reserved" 60 "reserved" 61 "reserved" 62 "reserved" 63 "reserved" 64 "reserved" 65 "reserved" 66 "reserved" 67 "reserved" 68 "reserved" 69 "reserved" 70 "reserved" 71 "reserved" 72 "reserved" 73 "reserved" 74 "reserved" 75 "reserved" 76 "reserved" 77 "reserved" 78 "reserved" 79 "reserved" 80 "reserved" 81 "reserved" 82 "reserved" 83 "reserved" 84 "reserved" 85 "reserved" 86 "reserved" 87 "reserved" 88 "reserved" 89 "reserved" 90 "reserved" 91 "reserved" 92 "reserved" 93 "reserved" 94 "reserved" 95 "reserved" 96 "reserved" 97 "reserved" 98 "reserved" 99 "reserved" 100 "reserved" 101 "reserved" 102 "reserved" 103 "reserved" 104 "reserved" 105 "reserved" 106 "reserved" 107 "reserved" 108 "reserved" 109 "reserved" 110 "reserved" 111 "reserved" 112 "reserved" 113 "reserved" 114 "reserved" 115 "reserved" 116 "reserved" 117 "reserved" 118 "reserved" 119 "reserved" 120 "reserved" 121 "reserved" 122 "reserved" 123 "reserved" 124 "reserved" 125 "reserved" 126 "reserved" 127 "reserved" 128 "reserved" 129 "reserved" 130 "reserved" 131 "reserved" 132 "reserved" 133 "reserved" 134 "reserved" 135 "reserved" 136 "reserved" 137 "reserved" 138 "reserved" 139 "reserved" 140 "reserved" 141 "reserved" 142 "reserved" 143 "reserved" 144 "reserved" 145 "reserved" 146 "reserved" 147 "reserved" 148 "reserved" 149 "reserved" 150 "reserved" 151 "reserved" 152 "reserved" 153 "reserved" 154 "reserved" 155 "reserved" 156 "reserved" 157 "reserved" 158 "reserved" 159 "reserved" 160 "reserved" 161 "reserved" 162 "reserved" 163 "reserved" 164 "reserved" 165 "reserved" 166 "reserved" 167 "reserved" 168 "reserved" 169 "reserved" 170 "reserved" 171 "reserved" 172 "reserved" 173 "reserved" 174 "reserved" 175 "reserved" 176 "reserved" 177 "reserved" 178 "reserved" 179 "reserved" 180 "reserved" 181 "reserved" 182 "reserved" 183 "reserved" 184 "reserved" 185 "reserved" 186 "reserved" 187 "reserved" 188 "reserved" 189 "reserved" 190 "reserved" 191 "reserved" 192 "reserved" 193 "reserved" 194 "reserved" 195 "reserved" 196 "reserved" 197 "reserved" 198 "reserved" 199 "reserved" 200 "reserved" 201 "reserved" 202 "reserved" 203 "reserved" 204 "reserved" 205 "reserved" 206 "reserved" 207 "reserved" 208 "reserved" 209 "reserved" 210 "reserved" 211 "reserved" 212 "reserved" 213 "reserved" 214 "reserved" 215 "reserved" 216 "reserved" 217 "reserved" 218 "reserved" 219 "reserved" 220 "reserved" 221 "reserved" 222 "reserved" 223 "reserved" 224 "reserved" 225 "reserved" 226 "reserved" 227 "reserved" 228 "reserved" 229 "reserved" 230 "reserved" 231 "reserved" 232 "reserved" 233 "reserved" 234 "reserved" 235 "reserved" 236 "reserved" 237 "reserved" 238 "reserved" 239 "reserved" 240 "reserved" 241 "reserved" 242 "reserved" 243 "reserved" 244 "reserved" 245 "reserved" 246 "reserved" 247 "reserved" 248 "reserved" 249 "reserved" 250 "reserved" 251 "reserved" 252 "reserved" 253 "reserved" 254 "reserved" ;
VAL_ 1096 TMS_CFSCycleLevel 0 "Invalid" 1 "CFSCycle level1" 2 "CFSCycle level2" 3 "CFSCycle level3" 4 "CFSCycle level4" 5 "Invalid" 6 "Invalid" 7 "Invalid" ;
VAL_ 1096 TMS_TimingLevel 0 "Invalid" 1 "CFSTiming level1" 2 "CFSTiming level2" 3 "CFSTiming level3" 4 "CFSTiming level4" 5 "Invalid" 6 "Invalid" 7 "Invalid" ;
VAL_ 1096 TMS_BiochemicalFuncSts 0 "Not Active" 1 "ON" 2 "OFF" 3 "Reserved" ;
VAL_ 1096 TMS_TimedVentilationSts 0 "Not Active" 1 "ON" 2 "OFF" 3 "Reserved" ;
VAL_ 1240 TMS_CFSSwitchFb 0 "OFF" 1 "ON" ;
VAL_ 1240 TDU_CFSPosOneType 0 "No Frag" 1 "Type 1" 2 "Type 2" 3 "Type 3" 4 "Type 4" 5 "Type 5" 6 "Unfilled" 7 "Position one active" 8 "Type 6" 9 "Type7" 10 "Type8" 11 "Type9" 12 "Type10" 13 "Type11" 14 "Type12" 15 "Not Active" ;
VAL_ 1240 TDU_CFSPosTwoType 0 "No Frag" 1 "Type 1" 2 "Type 2" 3 "Type 3" 4 "Type 4" 5 "Type 5" 6 "Unfilled" 7 "Position one active" 8 "Type 6" 9 "Type7" 10 "Type8" 11 "Type9" 12 "Type10" 13 "Type11" 14 "Type12" 15 "Not Active" ;
VAL_ 1240 TDU_CFSPosThreeType 0 "No Frag" 1 "Type 1" 2 "Type 2" 3 "Type 3" 4 "Type 4" 5 "Type 5" 6 "Unfilled" 7 "Position one active" 8 "Type 6" 9 "Type7" 10 "Type8" 11 "Type9" 12 "Type10" 13 "Type11" 14 "Type12" 15 "Not Active" ;
VAL_ 1240 TDU_CFSRunOut 0 "No Unset" 1 "Position One Runout" 2 "Position Two Runout" 3 "Position One and Two Runout" 4 "Position Three Runout" 5 "Position One and Three Runout" 6 "Position Two and Three Runout" 7 "Position One and Two and Three Runout" 8 "Reserved" 9 "Reserved" 10 "Reserved" 11 "Reserved" 12 "Reserved" 13 "Reserved" 14 "Reserved" 15 "Not Active" ;
VAL_ 1240 TMS_CFSShortWarn 0 "No Unset" 1 "Position One ShortWarn" 2 "Position Two ShortWarn" 3 "Position One and Two ShortWarn" 4 "Position Three ShortWarn" 5 "Position One and Three ShortWarn" 6 "Position Two and Three ShortWarn" 7 "Position One and Two and Three ShortWarn" 8 "Reserved" 9 "Reserved" 10 "Reserved" 11 "Reserved" 12 "Reserved" 13 "Reserved" 14 "Reserved" 15 "Not Active" ;
VAL_ 1240 TMS_CFSLevelSetFb 0 "Not Active" 1 "Level 1" 2 "Level 2" 3 "Level 3" 4 "Reserved" 5 "Reserved" 6 "Reserved" 7 "Reserved" 8 "Reserved" 9 "Reserved" 10 "Reserved" 11 "Reserved" 12 "Reserved" 13 "Reserved" 14 "Reserved" 15 "Reserved" ;
VAL_ 1240 TMS_CFSPosSetFb 0 "Not Active" 1 "Position One" 2 "Position Two" 3 "Position Three" ;
VAL_ 1240 TMS_PM25SwitchFb 0 "OFF" 1 "On" ;
VAL_ 1240 TMS_AQSCOSts_2 0 "Lv0_Clean air" 1 "Lv1_10% CO Pollution" 2 "Lv2_20% CO Pollution" 3 "Lv3_30% CO Pollution" 4 "Lv4_40% CO Pollution" 5 "Lv5_50% CO Pollution" 6 "Lv6_60% CO Pollution" 7 "Lv7_70% CO Pollution" 8 "Lv8_80% CO Pollution" 9 "Lv9_90% CO Pollution" 10 "Lv10_100%CO Pollution" ;
VAL_ 1240 TMS_AQSNO2Sts_2 0 "Lv0_Clean air" 1 "Lv1_10% NO2 Pollution" 2 "Lv2_20% NO2 Pollution" 3 "Lv3_30% NO2 Pollution" 4 "Lv4_40% NO2 Pollution" 5 "Lv5_50% NO2 Pollution" 6 "Lv6_60% NO2 Pollution" 7 "Lv7_70% NO2 Pollution" 8 "Lv8_80% NO2 Pollution" 9 "Lv9_90% NO2 Pollution" 10 "Lv10_100%NO2 Pollution" ;
VAL_ 1240 TMS_AQSN02SnsrSts_2 0 "Initializing" 1 "ActiveMode_SensorOn" 2 "StandbyMode_SensorOFF" 3 "Error" ;
VAL_ 1240 TMS_AQSLifeCntr_2 0 "Cyclic_0" 1 "Cyclic_1" 2 "Cyclic_2" 3 "Cyclic_3" ;
VAL_ 1240 TMS_AQSErrSts_2 0 "SNA" 1 "NoErr" 2 "OverVoltage" 3 "OverTemp" 4 "IntErr" ;
VAL_ 1240 TMS_AQSErrRespAQSM_2 0 "Normal" 1 "Error" ;
VAL_ 1240 TMS_AQSAirQlySts_2 0 "No Pollution" 1 "AirQlyHi_Low Pollution" 2 "AirQlyMed_Medium Pollution" 3 "AirQlyLo_High Pollution" 4 "SNA" 5 "Reserved" 6 "Reserved" 7 "Reserved" ;
VAL_ 1240 TMS_ThrModeStsFb 0 "Blow Face" 1 "Blow Face and Blow Foot" 2 "Blow Foot" 3 "Auto" 4 "Reserved" 5 "Reserved" 6 "Reserved" 7 "Not Active" ;
VAL_ 1240 TMS_ThrSetTempFb_C 31 "Not active" ;
VAL_ 1240 TMS_ThrCLMSwitchFb 0 "OFF" 1 "On" ;
VAL_ 1240 TMS_ThrAutoSwitchFb 0 "Auto OFF" 1 "Auto On" ;
VAL_ 1240 TMS_ThrBlowSpeedLevelKeyStsFb 0 "Not Active" 1 "Level  1" 2 "Level  2" 3 "Level  3" 4 "Level  4" 5 "Level  5" 6 "Level  6" 7 "Level  7" 8 "Level  0" 9 "Reserved" 10 "Reserved" 11 "Reserved" 12 "Reserved" 13 "Reserved" 14 "Reserved" 15 "Reserved" ;
VAL_ 638 FRZCU_HoodSts 0 "Close" 1 "Ajar_" 2 "full_open" 3 "Reserved" ;
VAL_ 638 FRZCU_AuthenResult 0 "not_success" 1 "success_" ;
VAL_ 638 FRZCU_PowerMode 0 "Off" 1 "Comfortable" 2 "ON" 3 "Reserved" ;
VAL_ 638 FRZCU_TrunkSts 0 "Close" 1 "Ajar_" 2 "full_open" 3 "Reserved" ;
VAL_ 638 FRZCU_HandleSwitchStsFL 0 "Not_Active" 1 "Outside" 2 "Inside" 3 "Bothside" ;
VAL_ 638 FRZCU_HandleSwitchStsFR 0 "Not_Active" 1 "Outside" 2 "Inside" 3 "Bothside" ;
VAL_ 638 FRZCU_HandleSwitchStsRR 0 "Not_Active" 1 "Outside" 2 "Inside" 3 "Bothside" ;
VAL_ 638 FRZCU_HandleSwitchStsRL 0 "Not_Active" 1 "Outside" 2 "Inside" 3 "Bothside" ;
VAL_ 638 SeatLength_target_Passenger 0 "Not_active" 1 "0" 2 "10%" 3 "20%" 4 "30%" 5 "40%" 6 "50%" 7 "60%" 8 "70%" 9 "80%" 10 "90%" 11 "100%" 12 "Reserved" 13 "Reserved" 14 "Reserved" 15 "Reserved" ;
VAL_ 638 SeatBackrest_target_Passenger 0 "Not_active" 1 "0" 2 "5%" 3 "10%" 4 "15%" 5 "20%" 6 "25%" 7 "30%" 8 "35%" 9 "40%" 10 "45%" 11 "50%" 12 "55%" 13 "60%" 14 "65%" 15 "70%" 16 "75%" 17 "80%" 18 "85%" 19 "90%" 20 "95%" 21 "100%" 22 "Reserved" 23 "Reserved" 24 "Reserved" 25 "Reserved" 26 "Reserved" 27 "Reserved" 28 "Reserved" 29 "Reserved" 30 "Reserved" 31 "Reserved" ;
VAL_ 638 FRZCU_TrunkLockSts 0 "Locked" 1 "Unlocked" 2 "Superlocked" 3 "Unknown" ;
VAL_ 638 FRZCU_HoodLockSts 0 "Locked" 1 "Unlocked" 2 "Superlocked" 3 "Unknown" ;
VAL_ 638 FrontBackSpeedAdj_Cmd 0 "No_Request" 1 "Low" 2 "Medium" 3 "High" 4 "Reserved" 5 "Reserved" 6 "Reserved" 7 "invalid" ;
VAL_ 638 FRZCU_GloveboxSW 0 "OFF" 1 "ON" ;
VAL_ 638 FRZCU_FRReleaseLockSts 0 "None" 1 "Releasing" 2 "Released" 3 "Reset" 4 "Resetting" 5 "Reserved" 6 "Reserved" 7 "Reserved" ;
VAL_ 638 FRZCU_RRReleaseLockSts 0 "None" 1 "Releasing" 2 "Released" 3 "Reset" 4 "Resetting" 5 "Reserved" 6 "Reserved" 7 "Reserved" ;
VAL_ 638 FRZCU_PELockInKeyWarning 0 "Not_Active" 1 "Active" ;
VAL_ 638 FRZCU_PowerOFFWarning 0 "Not_Active" 1 "Active" ;
VAL_ 638 FRZCU_KeylessWarning 0 "Not_Active" 1 "Active" ;
VAL_ 638 FRZCU_OTAPwrDwnReqFb 0 "No_Command" 1 "Success" 2 "Fail" 3 "Resrved" ;
VAL_ 638 FRZCU_OTAPwrOnReqFb 0 "No_Command" 1 "Success" 2 "Fail" 3 "Resrved" ;
VAL_ 949 PEPS_InformationSource 0 "Not_Active" 1 "Smart_Information" 2 "RKE_Information" 3 "Near_Access" ;
VAL_ 949 PEPS_OrderInformation 0 "OFF" 1 "Lock" 2 "Unlock" 4 "Trunk" 5 "Welcome_On" 6 "Welcome_Off" 7 "RKE_Search_Car" 8 "Power_Slide_Door_Left" ;
VAL_ 949 PEPS_IDInformation 0 "Not_Active" 1 "Transmitter_1" 2 "Transmitter_2" 3 "Transmitter_3" 4 "Transmitter_4" 5 "Transmitter_BLT1" 6 "Transmitter_BLT2" 7 "Transmitter_BLT3" 8 "Transmitter_NFC1" 9 "Transmitter_NFC2" 10 "Transmitter_NFC3" ;
VAL_ 949 PEPS_KeySts 0 "Not_Active" 1 "PEPS_Key_In" 2 "PEPS_Key_Near_Flant" 3 "PEPS_Key_Near_Frant" 4 "PEPS_Key_Near_Trunkant" 5 "Unknow" ;
VAL_ 949 PEPS_ETRUnLockReq 0 "Not_Request" 1 "Request" ;
VAL_ 1028 PEPS_WelcomeON 0 "Default_value" 1 "Welcome_light_OFF" 2 "Welcome_light_ON" 3 "Reserved" ;
VAL_ 1028 PEPS_VehicleSearchReq 0 "No_Request" 1 "Request" 2 "Reseved" 3 "Reseved" ;
VAL_ 1028 PEPS_SATOReminder 0 "No_Command" 1 "Remind_stop" 2 "Remind_start" 3 "Reseved" ;
VAL_ 1028 PEPS_PLGUnlockReq 0 "Not_Request" 1 "Request" 2 "Reseved" 3 "Reseved" ;
VAL_ 1028 PEPS_RKETrunkSts 0 "Not_Active" 1 "Long_Press" 2 "Short_Press" 3 "Not_Used" ;
VAL_ 1028 PEPS_SSBInhibitCWCSts 0 "Default" 1 "Disable" 2 "Reseved" 3 "Reseved" ;
VAL_ 1028 PEPS_WirelessChargingCtrSts 0 "Default" 1 "Disable" 2 "Reseved" 3 "Reseved" ;
VAL_ 1028 PEPS_EmgyShutdown 0 "No_Happen" 1 "Happen" 2 "Reseved" 3 "Reseved" ;
VAL_ 1028 PEPS_SSBInputFailure 0 "Not_Fail" 1 "Fail" 2 "Reseved" 3 "Reseved" ;
VAL_ 1028 PEPS_SmartSystemWarning1_1 0 "Normal" 1 "Identifier_is_out_of_vehicle" 2 "Reseved" 3 "Reseved" ;
VAL_ 1028 PEPS_SmartSystemWarning2_2 0 "Normal" 1 "Identifier_is_out_of_vehicle_range_when_vehicle_starts_running" 2 "Reseved" 3 "Reseved" ;
VAL_ 1028 PEPS_SmartSystemWarning3_1 0 "Normal" 1 "Identifier_low_battery_detected" 2 "Reseved" 3 "Reseved" ;
VAL_ 1028 PEPS_SmartSystemWarning3_2 0 "Normal" 1 "Engine_start_not_possible_if_gear_box_not_in_P_or_N_position" 2 "Reseved" 3 "Reseved" ;
VAL_ 1028 PEPS_SmartSystemWarning4_2 0 "Normal_" 1 "Engine_start_attempted_without_pressing_clutch/brake_pedal" 2 "Reseved" 3 "Reseved" ;
VAL_ 1028 PEPS_SmartSystemWarning4_3 0 "Normal" 1 "Switching_OFF_while_Gear_box_not_in_P_position" 2 "Reseved" 3 "Reseved" ;
VAL_ 1028 PEPS_SystemWarning 0 "Normal" 1 "Fault" 2 "Reseved" 3 "Reseved" ;
VAL_ 1028 PEPS_BLTKeyPESts 0 "OFF" 1 "ON" 2 "Reseved" 3 "Reseved" ;
VAL_ 1291 BMS_TBOXHvBattMaxT 254 "Abnormal" 255 "Invalid" ;
VAL_ 1291 BMS_TBOXHvBattMinT 254 "Abnormal" 255 "Invalid" ;
VAL_ 1291 BMS_SOCLight 127 "Invalid" ;
VAL_ 587 LHRPulseCounterFailSts 0 "Fail Not Present" 1 "Fail Present" ;
VAL_ 587 RHRPulseCounterFailSts 0 "Fail Not Present" 1 "Fail Present" ;
VAL_ 587 RHFPulseCounterFailSts 0 "Fail Not Present" 1 "Fail Present" ;
VAL_ 587 LHFPulseCounterFailSts 0 "Fail Not Present" 1 "Fail Present" ;
VAL_ 587 LHFWheelDriveDirection 0 "Init" 1 "Forward" 2 "Backward" 3 "Stop" 4 "Invalid" 5 "reserved" 6 "reserved" 7 "reserved" ;
VAL_ 587 RHFWheelDriveDirection 0 "Init" 1 "Forward" 2 "Backward" 3 "Stop" 4 "Invalid" 5 "reserved" 6 "reserved" 7 "reserved" ;
VAL_ 587 LHRWheelDriveDirection 0 "Init" 1 "Forward" 2 "Backward" 3 "Stop" 4 "Invalid" 5 "reserved" 6 "reserved" 7 "reserved" ;
VAL_ 587 RHRWheelDriveDirection 0 "Init" 1 "Forward" 2 "Backward" 3 "Stop" 4 "Invalid" 5 "reserved" 6 "reserved" 7 "reserved" ;
VAL_ 1338 FMCU_ErrLvlDis 0 "No Error" 1 "Err_level1" 2 "Err_level2" 3 "Err_level3" 4 "Err_level4" 5 "Err_level5" 6 "Err_level6" ;
VAL_ 1338 FMCU_SpdAct_EDR 65535 "Invalid" ;
VAL_ 777 ISGF_ErrLvl 0 "No Error" 1 "Err_level1" 2 "Err_level2" 3 "Err_level3" 4 "Err_level4" 5 "Err_level5" 6 "Err_level6" ;
VAL_ 1403 RMCU_ErrLvlDis 0 "No Error" 1 "Err_level1" 2 "Err_level2" 3 "Err_level3" 4 "Err_level4" 5 "Err_level5" 6 "Err_level6" ;
VAL_ 1403 RMCU_Speed_EDR 65535 "Invalid" ;
VAL_ 1299 BMS_PackVoltageDis 65534 "Abnormal" 65535 "Invalid" ;
VAL_ 1299 BMS_PackCurrentDis 65534 "Abnormal" 65535 "Invalid" ;
VAL_ 1099 ISGF_SysTempOvrInd 0 "Lamp off" 1 "Lamp on" ;
VAL_ 1130 TCU_23_GBFaultstatus 0 "No failure" 1 "GB failure" 2 "High oil over temperature" 3 "Clutch over temperature" ;
VAL_ 1130 TCU_23_TeachInState 0 "Default" 1 "Successful" 2 "Fault" 3 "Teach in process" 4 "require teach in" ;
VAL_ 1130 TCU_23_GBWarmUpReq 0 "No Request" 1 "Warm Up Request" ;
VAL_ 1130 TCU_23_CluSelfLrng 0 "No Request" 1 "ClutchSelfLearnEnb" ;
VAL_ 1180 ACU_1_AirBagFailSts 0 "Fail no present, lamp off" 1 "Fail no present, lamp flashing" 2 "Fail present, lamp on" 3 "Lamp on, but no warning information displaying on the LCD" ;
VAL_ 1180 ACU_1_ThdRowLBeltWarning 0 "No Warning" 1 "Warning" ;
VAL_ 1180 ACU_1_ThdRowRBeltWarning 0 "No Warning" 1 "Warning" ;
VAL_ 1180 ACU_1_PsngrSeatBeltWarning 0 "Not warning" 1 "Reserve" 2 "Warning" 3 "Not used" ;
VAL_ 1180 ACU_1_SecRowLBeltWarning 0 "No Warning" 1 "Warning" ;
VAL_ 1180 ACU_1_SecRowMBeltWarning 0 "No Warning" 1 "Warning" ;
VAL_ 1180 ACU_1_SecRowRBeltWarning 0 "No Warning" 1 "Warning" ;
VAL_ 1180 ACU_1_PsngrSeatOccupiedSts 0 "not occupied" 1 "occupied" 2 "open circuit" 3 "short circuit" ;
VAL_ 811 BMS_Chg_Sts 1 "Parking chagre" 2 "Driving charge" 3 "no charge" 4 "charge complete" 14 "Abnomal" 15 "Invalid" ;
VAL_ 1427 ILCF_1_LogoParkingSts 0 "Not Active" 1 "ON" 2 "OFF" 3 "Reserved" ;
VAL_ 1172 ExternalTemperature_C 254 "invalid" ;
VAL_ 1172 BlowSpeedLevelDisplaySts 0 "Not_Active" 1 "Level_1" 2 "Level_2" 3 "Level_3" 4 "Level_4" 5 "Level_5" 6 "Level_6" 7 "Level_7" 8 "Level_8" 9 "Level_9" 10 "Level_10" 11 "Reserved" 12 "Level_0" 13 "Reserved" 14 "Reserved" 15 "Reserved" ;
VAL_ 1147 CCP_1_FrontAutoACSwitchReq 0 "No_Pressed" 1 "Pressed" ;
VAL_ 1147 CCP_1_FBlowSpdCtrlSwitchReq 0 "No_Request" 1 "Speed_1_Request" 2 "Speed_2_Request" 3 "Speed_3_Request" 4 "Speed_4_Request" 5 "Speed_5_Request" 6 "Speed_6_Request" 7 "Speed_7_Request" 8 "Speed_8_Request" 9 "Speed_9_Request" 10 "Speed_10_Request" 12 "Speed_0_Request" 15 "Invalid" ;
VAL_ 1147 FLCCP_MainSetHeatReq 0 "Not_Active" 1 "OFF" 2 "Seat_heating_Level1" 3 "Seat_heating_Level2" 4 "Seat_heating_Level3" ;
VAL_ 1147 FLCCP_MainSetVentilationReq 0 "Not_Active" 1 "OFF" 2 "Seat_Ventilation_Level1" 3 "Seat_Ventilation_Level2" 4 "Seat_Ventilation_Level3" ;
VAL_ 1107 TMS_PM25_Detect 0 "NotActive" 1 "Active" ;
VAL_ 1107 TMS_CCP_FrontAutoACSts 0 "NotActive" 1 "Active" ;
VAL_ 1107 TMS_CCP_ACStatus 0 "NotActive" 1 "Active" ;
VAL_ 1107 TMS_CCP_FrontOFFSts 0 "NotActive" 1 "Active" ;
VAL_ 1107 TMS_CCP_FBlowSpdCtrlSts 0 "No_Request" 1 "Speed_1_Request" 2 "Speed_2_Request" 3 "Speed_3_Request" 4 "Speed_4_Request" 5 "Speed_5_Request" 6 "Speed_6_Request" 7 "Speed_7_Request" 8 "Speed_8_Request" 9 "Speed_9_Request" 10 "Speed_10_Request" 12 "Speed_0_Request" 15 "Invalid" ;
VAL_ 1107 TMS_CCP_RecyMode 0 "no_Request" 1 "internal_Recycle_Request" 2 "external_Recycle_Request" 3 "auto_Recycle_Request" ;
VAL_ 1107 TMS_CCP_FrontDefrostSts 0 "NotActive" 1 "Active" ;
VAL_ 1107 TMS_UVC_WorkingBfReq 0 "No_Request" 1 "Open_Request" 2 "Close_Request" 3 "AUTO" ;
VAL_ 1107 TMS_UVC_LuminanceBfReq 0 "No_Request" 1 "Higher" 2 "Lower" 3 "Reserved" ;
VAL_ 1107 TMS_CCP_ACFastCool 0 "Not_Active" 1 "ON" 2 "OFF" 3 "Not_Used" ;
VAL_ 1107 TMS_CCP_ACFastHeat 0 "Not_Active" 1 "ON" 2 "OFF" 3 "Not_Used" ;
VAL_ 1175 CCP_2_RecyModeReq 0 "no_Request" 1 "internal_Recycle_Request" 2 "external_Recycle_Request" ;
VAL_ 1175 CCP_2_DefrostModeSwitchReq 0 "No_Pressed" 1 "Pressed" ;
VAL_ 1175 CCP_2_RearDefrostSwitchReq 0 "No_Pressed" 1 "Pressed" ;
VAL_ 1175 CCP_2_ACSwitchReq 0 "No_Pressed" 1 "Pressed" ;
VAL_ 1292 CHB_App_Sts 0 "NotActive" 1 "Chb_ON" 2 "Chb_OFF" 3 "reserved" ;
VAL_ 1292 CHB_AppMem_Sts 0 "NotActive" 1 "ChbMem_ON" 2 "ChbMem_OFF" 3 "reserved" ;
VAL_ 1292 CHB_AppDelay_Sts 0 "NotActive" 1 "ChbDelay_ON" 2 "ChbDelay_OFF" 3 "reserved" ;
VAL_ 1292 CHB_AppCoolorheat_Sts 0 "NotActive" 1 "ChbCool_on" 2 "ChbHeat_on" 3 "Close" 4 "ColdDrinkMode" 5 "IceCreamMode" 6 "WarmMilkMode" 7 "WarmDrinkMode" ;
VAL_ 1292 CHB_AppCoolset_Sts 0 "Not_Active" 1 "ChbCoolset_-6" 2 "ChbCoolset_-5" 3 "ChbCoolset_-4" 4 "ChbCoolset_-3" 5 "ChbCoolset_-2" 6 "ChbCoolset_-1" 7 "ChbCoolset_0" 8 "ChbCoolset_1" 9 "ChbCoolset_2" 10 "ChbCoolset_3" 11 "ChbCoolset_4" 12 "ChbCoolset_5" 13 "ChbCoolset_6" 14 "ChbCoolset_-18" 15 "ChbCoolset_-17" 16 "ChbCoolset_-16" 17 "ChbCoolset_-15" 18 "ChbCoolset_-14" 19 "ChbCoolset_-13" 20 "ChbCoolset_-12" 21 "ChbCoolset_-11" 22 "ChbCoolset_-10" 23 "ChbCoolset_-9" 24 "ChbCoolset_-8" 25 "ChbCoolset_-7" 26 "Reserved" 27 "Reserved" 28 "Reserved" 29 "Reserved" 30 "Reserved" 31 "Reserved" ;
VAL_ 1292 CHB_AppHeatset_Sts 0 "Not_Active" 1 "ChbHeatset_35" 2 "ChbHeatset_36" 3 "ChbHeatset_37" 4 "ChbHeatset_38" 5 "ChbHeatset_39" 6 "ChbHeatset_40" 7 "ChbHeatset_41" 8 "ChbHeatset_42" 9 "ChbHeatset_43" 10 "ChbHeatset_44" 11 "ChbHeatset_45" 12 "ChbHeatset_46" 13 "ChbHeatset_47" 14 "ChbHeatset_48" 15 "ChbHeatset_49" 16 "ChbHeatset_50" ;
VAL_ 1292 CHB_AppSterilization_Sts 0 "NotActive" 1 "Chbsterilize_ON" 2 "Chbsterilize_OFF" 3 "Chbsterilize_Stop" ;
VAL_ 1292 CHB_AppItemsLeft_Sts 0 "NotActive" 1 "ChbItemsLeft_ON" 2 "ChbItemsLeft_OFF" 3 "reserved" ;
VAL_ 1292 CHB_AppItemsLeftset_Sts 0 "NotActive" 1 "CHB_ItemsLeftset_ON" 2 "CHB_ItemsLeftset_OFF" 3 "Reserved" ;
VAL_ 1292 CHB_AppChbDoor_Sts 0 "NotActive" 1 "ChbDoor_ON" 2 "ChbDoor_OFF" 3 "reserved" ;
VAL_ 1241 FuelTankLidSystemFailureSts 0 "No failure" 1 "Failure" ;
VAL_ 1241 FuelTankPressureConditionReached 0 "Not Active" 1 "Wait to refuel" 2 "Ready to refuel" 3 "Reserved" ;
VAL_ 49 ACU_2_LateralAcceleration 65535 "Invalid" ;
VAL_ 49 ACU_2_YawRate 65535 "Invalid" ;
VAL_ 49 ACU_2_YawrateSigValidData 0 "Valid" 1 "Reserved" 2 "Invalid" 3 "Initialize" ;
VAL_ 49 ACU_2_LateralAccelerationSigVD 0 "Valid" 1 "Reserved" 2 "Invalid" 3 "Initialize" ;
VAL_ 1024 CSunshadeSts 0 "Not Active" 1 "Open" 2 "Close" 3 "Half_Open" 4 "Opening" 5 "Closing" 6 "Stop" 7 "Error" ;
VAL_ 1024 CSunshadePercentSts 0 "Not Active" 1 "0%" 2 "10%" 3 "20%" 4 "30%" 5 "40%" 6 "50%" 7 "60%" 8 "70%" 9 "80%" 10 "90%" 11 "100%" 12 "reserved" 13 "reserved" 14 "reserved" 15 "reserved" ;
VAL_ 1024 FRZCU_SeatHeatLvlFR2 0 "Not Active" 1 "OFF" 2 "Level1" 3 "Level2" 4 "Level3" 5 "Level4" 6 "Level5" 7 "Level6" 8 "Level7" 9 "Level8" 10 "Level9" ;
VAL_ 1024 FRZCU_SeatVentLvlFR2 0 "Not Active" 1 "OFF" 2 "Level1" 3 "Level2" 4 "Level3" 5 "Level4" 6 "Level5" 7 "Level6" 8 "Level7" 9 "Level8" 10 "Level9" ;
VAL_ 1024 FRZCU_SeatVentLvlRR2 0 "Not Active" 1 "OFF" 2 "Level1" 3 "Level2" 4 "Level3" 5 "Level4" 6 "Level5" 7 "Level6" 8 "Level7" 9 "Level8" 10 "Level9" ;
VAL_ 1024 FRZCU_SeatHeatLvlRR2 0 "Not Active" 1 "OFF" 2 "Level1" 3 "Level2" 4 "Level3" 5 "Level4" 6 "Level5" 7 "Level6" 8 "Level7" 9 "Level8" 10 "Level9" ;
VAL_ 1024 FRZCU_ContainerlightSts 0 "Not Active" 1 "ON" 2 "OFF" 3 "reserved" ;
VAL_ 1024 FRZCU_FRWinThermalSts 0 "Normal" 1 "Thermal protection" ;
VAL_ 1024 FRZCU_RRWinThermalSts 0 "Normal" 1 "Thermal protection" ;
VAL_ 1024 FRZCU_CSunshadeThermalSts 0 "Normal" 1 "Thermal protection" ;
VAL_ 1182 OBC_ElectronicLockSts 0 "Unlock" 1 "Lock" 2 "Lock error" 3 "Unlock error" 4 "Elock error" ;
VAL_ 1182 OBC_WorkingMode 0 "Init" 1 "Standby" 2 "Chg" 3 "Default" 4 "Preheat" 5 "Keepwarm" 6 "V2L" 7 "V2V" 8 "Powerdown" 9 "Afterrun" 10 "Fault" 11 "Reserved" 12 "Reserved" 13 "Reserved" 14 "Reserved" 15 "Reserved" ;
VAL_ 1182 OBC_OutDischgCurr 1023 "Invalid" ;
VAL_ 1182 OBC_OutDischgVolt 8191 "Invalid" ;
VAL_ 513 MFSL_UP_SW 0 "Not_action" 1 "Pressed" 2 "Stuck" 3 "invalid" ;
VAL_ 513 MFSL_DW_SW 0 "Not_action" 1 "Pressed" 2 "Stuck" 3 "invalid" ;
VAL_ 513 MFSL_Left_SW 0 "Not_action" 1 "Pressed" 2 "Stuck" 3 "invalid" ;
VAL_ 513 MFSL_Right_SW 0 "Not_action" 1 "Pressed" 2 "Stuck" 3 "invalid" ;
VAL_ 513 MFSL_OK_SW 0 "Not_action" 1 "Pressed" 2 "Stuck" 3 "invalid" ;
VAL_ 513 MFSL_APA_SW 0 "Not_action" 1 "Pressed" 2 "Stuck" 3 "invalid" ;
VAL_ 513 MFSL_LCC_NCA_SW 0 "Not_action" 1 "Pressed" 2 "Stuck" 3 "invalid" ;
VAL_ 1164 OBC_DischgSts 0 "NoDischarge" 1 "Discharging" 2 "Discharging-Interior" 3 "Discharging_AND_Discharging-Interior" ;
VAL_ 789 ATCM_DriveModeSw 0 "Not Active" 1 "Plus" 2 "Minus" 3 "Reserved" ;
VAL_ 789 ATCM_XModeSw 0 "Not_Active" 1 "ON" 2 "OFF" 3 "Reserved" ;
VAL_ 789 ATCM_SwitchUTurnModeSet 0 "Release" 1 "Press" ;
VAL_ 789 ATCM_ESP_OFF_SW 0 "Release" 1 "Press" ;
VAL_ 789 ATCM_AVH_SW 0 "Release" 1 "Press" ;
VAL_ 789 ATCM_AVM 0 "Release" 1 "Press" ;
VAL_ 571 LHTurnlightSts 0 "Not Active" 1 "Active" ;
VAL_ 571 RHTurnlightSts 0 "Not Active" 1 "Active" ;
VAL_ 571 LHFdoorSts 0 "Close" 1 "Ajar" 2 "full_open" 3 "Reserved" ;
VAL_ 571 LHFDoorLockSts 0 "Locked" 1 "Unlocked" 2 "Superlocked" 3 "Unknown" ;
VAL_ 571 LHTurnSW 0 "Off" 1 "Active" ;
VAL_ 571 RHTurnSW 0 "Off" 1 "Active" ;
VAL_ 571 HazardLightSW 0 "Close" 1 "Open" ;
VAL_ 571 LHFSeatBeltSW 0 "Not Active" 1 "Active" ;
VAL_ 571 DirectionIndLeft 0 "Close" 1 "Open" ;
VAL_ 571 DirectionIndRight 0 "Close" 1 "Open" ;
VAL_ 699 LHRdoorSts 0 "Close" 1 "Ajar" 2 "full_open" 3 "Reserved" ;
VAL_ 787 ChrgHoodSts 0 "Close" 1 "Open" ;
VAL_ 787 FRZCU_FRSitPosnSts 0 "Not Active" 1 "Location1" 2 "Location2" 3 "Location3" ;
VAL_ 572 ONEBOX_7_TAB_HighTemp 0 "No Active" 1 "Active" ;
VAL_ 572 ONEBOX_7_TAB_Active 0 "Not Active" 1 "Active" 2 "Stand by" 3 "Failed" ;
VAL_ 572 ONEBOX_7_BSW_Active 0 "Not Active" 1 "Active" 2 "Filed" 3 "Reserved" ;
VAL_ 1120 RLHS_2_AmbBrightness 4095 "Invalid" ;
VAL_ 1120 RLHS_LiSwithReason 0 "Darkstart" 1 "Day" 2 "Night" 3 "Tunnul" ;
VAL_ 1199 TCM_1_TrailerSts 0 "Disconnect" 1 "Connect" ;
VAL_ 770 ADS_RPAOnlineOrNot_302h 0 "None" 1 "rolling counter" 2 "rolling counter" 3 "rolling counter" 4 "rolling counter" 5 "rolling counter" 6 "rolling counter" 7 "rolling counter" 8 "rolling counter" 9 "rolling counter" 10 "rolling counter" 11 "rolling counter" 12 "rolling counter" 13 "rolling counter" 14 "rolling counter" 15 "rolling counter" 16 "rolling counter" 17 "rolling counter" 18 "rolling counter" 19 "rolling counter" 20 "rolling counter" 21 "rolling counter" 22 "rolling counter" 23 "rolling counter" 24 "rolling counter" 25 "rolling counter" 26 "rolling counter" 27 "rolling counter" 28 "rolling counter" 29 "rolling counter" 30 "rolling counter" 31 "rolling counter" 32 "rolling counter" 33 "rolling counter" 34 "rolling counter" 35 "rolling counter" 36 "rolling counter" 37 "rolling counter" 38 "rolling counter" 39 "rolling counter" 40 "rolling counter" 41 "rolling counter" 42 "rolling counter" 43 "rolling counter" 44 "rolling counter" 45 "rolling counter" 46 "rolling counter" 47 "rolling counter" 48 "rolling counter" 49 "rolling counter" 50 "rolling counter" 51 "rolling counter" 52 "rolling counter" 53 "rolling counter" 54 "rolling counter" 55 "rolling counter" 56 "rolling counter" 57 "rolling counter" 58 "rolling counter" 59 "rolling counter" 60 "rolling counter" 61 "rolling counter" 62 "rolling counter" 63 "rolling counter" 64 "rolling counter" 65 "rolling counter" 66 "rolling counter" 67 "rolling counter" 68 "rolling counter" 69 "rolling counter" 70 "rolling counter" 71 "rolling counter" 72 "rolling counter" 73 "rolling counter" 74 "rolling counter" 75 "rolling counter" 76 "rolling counter" 77 "rolling counter" 78 "rolling counter" 79 "rolling counter" 80 "rolling counter" 81 "rolling counter" 82 "rolling counter" 83 "rolling counter" 84 "rolling counter" 85 "rolling counter" 86 "rolling counter" 87 "rolling counter" 88 "rolling counter" 89 "rolling counter" 90 "rolling counter" 91 "rolling counter" 92 "rolling counter" 93 "rolling counter" 94 "rolling counter" 95 "rolling counter" 96 "rolling counter" 97 "rolling counter" 98 "rolling counter" 99 "rolling counter" 100 "rolling counter" 101 "rolling counter" 102 "rolling counter" 103 "rolling counter" 104 "rolling counter" 105 "rolling counter" 106 "rolling counter" 107 "rolling counter" 108 "rolling counter" 109 "rolling counter" 110 "rolling counter" 111 "rolling counter" 112 "rolling counter" 113 "rolling counter" 114 "rolling counter" 115 "rolling counter" 116 "rolling counter" 117 "rolling counter" 118 "rolling counter" 119 "rolling counter" 120 "rolling counter" 121 "rolling counter" 122 "rolling counter" 123 "rolling counter" 124 "rolling counter" 125 "rolling counter" 126 "rolling counter" 127 "rolling counter" 128 "rolling counter" 129 "rolling counter" 130 "rolling counter" 131 "rolling counter" 132 "rolling counter" 133 "rolling counter" 134 "rolling counter" 135 "rolling counter" 136 "rolling counter" 137 "rolling counter" 138 "rolling counter" 139 "rolling counter" 140 "rolling counter" 141 "rolling counter" 142 "rolling counter" 143 "rolling counter" 144 "rolling counter" 145 "rolling counter" 146 "rolling counter" 147 "rolling counter" 148 "rolling counter" 149 "rolling counter" 150 "rolling counter" 151 "rolling counter" 152 "rolling counter" 153 "rolling counter" 154 "rolling counter" 155 "rolling counter" 156 "rolling counter" 157 "rolling counter" 158 "rolling counter" 159 "rolling counter" 160 "rolling counter" 161 "rolling counter" 162 "rolling counter" 163 "rolling counter" 164 "rolling counter" 165 "rolling counter" 166 "rolling counter" 167 "rolling counter" 168 "rolling counter" 169 "rolling counter" 170 "rolling counter" 171 "rolling counter" 172 "rolling counter" 173 "rolling counter" 174 "rolling counter" 175 "rolling counter" 176 "rolling counter" 177 "rolling counter" 178 "rolling counter" 179 "rolling counter" 180 "rolling counter" 181 "rolling counter" 182 "rolling counter" 183 "rolling counter" 184 "rolling counter" 185 "rolling counter" 186 "rolling counter" 187 "rolling counter" 188 "rolling counter" 189 "rolling counter" 190 "rolling counter" 191 "rolling counter" 192 "rolling counter" 193 "rolling counter" 194 "rolling counter" 195 "rolling counter" 196 "rolling counter" 197 "rolling counter" 198 "rolling counter" 199 "rolling counter" 200 "rolling counter" 201 "rolling counter" 202 "rolling counter" 203 "rolling counter" 204 "rolling counter" 205 "rolling counter" 206 "rolling counter" 207 "rolling counter" 208 "rolling counter" 209 "rolling counter" 210 "rolling counter" 211 "rolling counter" 212 "rolling counter" 213 "rolling counter" 214 "rolling counter" 215 "rolling counter" 216 "rolling counter" 217 "rolling counter" 218 "rolling counter" 219 "rolling counter" 220 "rolling counter" 221 "rolling counter" 222 "rolling counter" 223 "rolling counter" 224 "rolling counter" 225 "rolling counter" 226 "rolling counter" 227 "rolling counter" 228 "rolling counter" 229 "rolling counter" 230 "rolling counter" 231 "rolling counter" 232 "rolling counter" 233 "rolling counter" 234 "rolling counter" 235 "rolling counter" 236 "rolling counter" 237 "rolling counter" 238 "rolling counter" 239 "rolling counter" 240 "rolling counter" 241 "rolling counter" 242 "rolling counter" 243 "rolling counter" 244 "rolling counter" 245 "rolling counter" 246 "rolling counter" 247 "rolling counter" 248 "rolling counter" 249 "rolling counter" 250 "rolling counter" 251 "rolling counter" 252 "rolling counter" 253 "rolling counter" 254 "rolling counter" 255 "rolling counter" ;
VAL_ 770 ADS_RpaParkAuthn_302h 0 "不允许手机操作" 1 "允许手机操作" 2 "预留" 3 "预留" ;
VAL_ 770 ADS_VehParkMod_302h 0 "None" 1 "车头泊入" 2 "车尾泊入" 3 "Reserved" 4 "Reserved" 5 "Reserved" 6 "Reserved" 7 "Reserved" ;
VAL_ 770 ADS_RemParkPatSel_302h 0 "NONE" 1 "PARK_IN_REQUEST_CONFIRMED" 2 "PARK_OUT_REQUEST_CONFIRMED" 3 "RESERVED" ;
VAL_ 770 ADS_ParkDirCfm_302h 0 "None" 1 "ParallelLeft_confirm" 2 "ParallelRight_confirm" 3 "PerpendicularForward_confirm" 4 "PerpendicularLeftForward_confirm" 5 "PerpendicularRightForward_confirm" 6 "PerpendicularLeftBack_confirm" 7 "PerpendicularRightBack_confirm" 8 "PerpendicularBack_confirm" 9 "Reserved" 10 "Reserved" 11 "Reserved" 12 "Reserved" 13 "Reserved" 14 "Reserved" 15 "Reserved" ;
VAL_ 770 ADS_ObstclDst_302h 0 "None" 1 "前左障碍物距离Level1" 2 "前左障碍物距离Level2" 3 "前左障碍物距离Level3" 4 "前障碍物距离Level1" 5 "前障碍物距离Level2" 6 "前障碍物距离Level3" 7 "前右障碍物距离Level1" 8 "前右障碍物距离Level2" 9 "前右障碍物距离Level3" 10 "后左障碍物距离Level1" 11 "后左障碍物距离Level2" 12 "后左障碍物距离Level3" 13 "后障碍物距离Level1" 14 "后障碍物距离Level2" 15 "后障碍物距离Level3" 16 "后右障碍物距离Level1" 17 "后右障碍物距离Level2" 18 "后右障碍物距离Level3" 19 "Reserved" 20 "Reserved" 21 "Reserved" 22 "Reserved" 23 "Reserved" 24 "Reserved" 25 "Reserved" 26 "Reserved" 27 "Reserved" 28 "Reserved" 29 "Reserved" 30 "Reserved" 31 "Reserved" ;
VAL_ 770 ADS_AutEve_302h 1 "MOP_HMI_NULL = 0" 2 "MOP_HMI_CRUISE = 1" 3 "MOP_HMI_BYPASS = 2" 4 "MOP_HMI_STOP_MAN = 3" 5 "MOP_HMI_STOP_CAR = 4" 6 "MOP_HMI_FOLLOW = 5" 7 "MOP_HMI_MEET = 6" 8 "MOP_HMI_TIME_OUT = 7" 9 "Reserved" 10 "Reserved" 11 "Reserved" 12 "Reserved" 13 "Reserved" 14 "Reserved" 15 "Reserved" ;
VAL_ 770 ADS_parkInterruptDuration_302h 0 "None（无倒计时或倒计时已结束）" 1 "30s倒计时，精度为1s" 2 "30s倒计时，精度为1s" 3 "30s倒计时，精度为1s" 4 "30s倒计时，精度为1s" 5 "30s倒计时，精度为1s" 6 "30s倒计时，精度为1s" 7 "30s倒计时，精度为1s" 8 "30s倒计时，精度为1s" 9 "30s倒计时，精度为1s" 10 "30s倒计时，精度为1s" 11 "30s倒计时，精度为1s" 12 "30s倒计时，精度为1s" 13 "30s倒计时，精度为1s" 14 "30s倒计时，精度为1s" 15 "30s倒计时，精度为1s" 16 "30s倒计时，精度为1s" 17 "30s倒计时，精度为1s" 18 "30s倒计时，精度为1s" 19 "30s倒计时，精度为1s" 20 "30s倒计时，精度为1s" 21 "30s倒计时，精度为1s" 22 "30s倒计时，精度为1s" 23 "30s倒计时，精度为1s" 24 "30s倒计时，精度为1s" 25 "30s倒计时，精度为1s" 26 "30s倒计时，精度为1s" 27 "30s倒计时，精度为1s" 28 "30s倒计时，精度为1s" 29 "30s倒计时，精度为1s" 30 "30s倒计时，精度为1s" 49 "Reserved" 50 "Reserved" 51 "Reserved" 52 "Reserved" 53 "Reserved" 54 "Reserved" 55 "Reserved" 56 "Reserved" 57 "Reserved" 58 "Reserved" 59 "Reserved" 60 "Reserved" 61 "Reserved" 62 "Reserved" 63 "Reserved" 64 "Reserved" 65 "Reserved" 66 "Reserved" 67 "Reserved" 68 "Reserved" 69 "Reserved" 70 "Reserved" 71 "Reserved" 72 "Reserved" 73 "Reserved" 74 "Reserved" 75 "Reserved" 76 "Reserved" 77 "Reserved" 78 "Reserved" 79 "Reserved" 80 "Reserved" 81 "Reserved" 82 "Reserved" 83 "Reserved" 84 "Reserved" 85 "Reserved" 86 "Reserved" 87 "Reserved" 88 "Reserved" 89 "Reserved" 90 "Reserved" 91 "Reserved" 92 "Reserved" 93 "Reserved" 94 "Reserved" 95 "Reserved" 96 "Reserved" 97 "Reserved" 98 "Reserved" 99 "Reserved" 100 "Reserved" 101 "Reserved" 102 "Reserved" 103 "Reserved" 104 "Reserved" 105 "Reserved" 106 "Reserved" 107 "Reserved" 108 "Reserved" 109 "Reserved" 110 "Reserved" 111 "Reserved" 112 "Reserved" 113 "Reserved" 114 "Reserved" 115 "Reserved" 116 "Reserved" 117 "Reserved" 118 "Reserved" 119 "Reserved" 120 "Reserved" 121 "Reserved" 122 "Reserved" 123 "Reserved" 124 "Reserved" 125 "Reserved" 126 "Reserved" 127 "Reserved" 128 "Reserved" 129 "Reserved" 130 "Reserved" 131 "Reserved" 132 "Reserved" 133 "Reserved" 134 "Reserved" 135 "Reserved" 136 "Reserved" 137 "Reserved" 138 "Reserved" 139 "Reserved" 140 "Reserved" 141 "Reserved" 142 "Reserved" 143 "Reserved" 144 "Reserved" 145 "Reserved" 146 "Reserved" 147 "Reserved" 148 "Reserved" 149 "Reserved" 150 "Reserved" 151 "Reserved" 152 "Reserved" 153 "Reserved" 154 "Reserved" 155 "Reserved" 156 "Reserved" 157 "Reserved" 158 "Reserved" 159 "Reserved" 160 "Reserved" 161 "Reserved" 162 "Reserved" 163 "Reserved" 164 "Reserved" 165 "Reserved" 166 "Reserved" 167 "Reserved" 168 "Reserved" 169 "Reserved" 170 "Reserved" 171 "Reserved" 172 "Reserved" 173 "Reserved" 174 "Reserved" 175 "Reserved" 176 "Reserved" 177 "Reserved" 178 "Reserved" 179 "Reserved" 180 "Reserved" 181 "Reserved" 182 "Reserved" 183 "Reserved" 184 "Reserved" 185 "Reserved" 186 "Reserved" 187 "Reserved" 188 "Reserved" 189 "Reserved" 190 "Reserved" 191 "Reserved" 192 "Reserved" 193 "Reserved" 194 "Reserved" 195 "Reserved" 196 "Reserved" 197 "Reserved" 198 "Reserved" 199 "Reserved" 200 "Reserved" 201 "Reserved" 202 "Reserved" 203 "Reserved" 204 "Reserved" 205 "Reserved" 206 "Reserved" 207 "Reserved" 208 "Reserved" 209 "Reserved" 210 "Reserved" 211 "Reserved" 212 "Reserved" 213 "Reserved" 214 "Reserved" 215 "Reserved" 216 "Reserved" 217 "Reserved" 218 "Reserved" 219 "Reserved" 220 "Reserved" 221 "Reserved" 222 "Reserved" 223 "Reserved" 224 "Reserved" 225 "Reserved" 226 "Reserved" 227 "Reserved" 228 "Reserved" 229 "Reserved" 230 "Reserved" 231 "Reserved" 232 "Reserved" 233 "Reserved" 234 "Reserved" 235 "Reserved" 236 "Reserved" 237 "Reserved" 238 "Reserved" 239 "Reserved" 240 "Reserved" 241 "Reserved" 242 "Reserved" 243 "Reserved" 244 "Reserved" 245 "Reserved" 246 "Reserved" 247 "Reserved" 248 "Reserved" 249 "Reserved" 250 "Reserved" 251 "Reserved" 252 "Reserved" 253 "Reserved" 254 "Reserved" 255 "Reserved" ;
VAL_ 770 APA_ResuAvl_302h 0 "默认" 1 "自检过程中" 2 "自检成功，to active满足" 3 "自检不成功，to active不满足" ;
VAL_ 770 ADS_ParkStMac_302h 0 "STATE_OFF = 0" 1 "STATE_RDA_FORWARD = 1" 2 "STATE_RDA_BACK = 2" 3 "STATE_RDA_ABORT = 3" 4 "STATE_RDA_FINISH = 4" 5 "STATE_CRUISE_FINISH = 5" 6 "STATE_APA_SUSPEND = 6" 7 "STATE_APA_SEARCH = 7" 8 "STATE_APA_STANDBY = 8" 9 "STATE_PARK_OUT = 9" 10 "STATE_PARK_IN = 10" 11 "STATE_APA_FINISH = 11" 12 "STATE_PAUSE = 12" 13 "STATE_OVERRIDE = 13" 14 "预留1" 15 "Reserved" 16 "Reserved" 17 "Reserved" 18 "Reserved" 19 "Reserved" 20 "Reserved" 21 "Reserved" 22 "Reserved" 23 "Reserved" 24 "Reserved" 25 "Reserved" 26 "Reserved" 27 "Reserved" 28 "Reserved" 29 "Reserved" 30 "Reserved" 31 "Reserved" ;
VAL_ 770 ADS_ParkOutDir_ParaLe_302h 0 "不可用" 1 "可用" ;
VAL_ 770 ADS_ParkOutDir_ParaRi_302h 0 "不可用" 1 "可用" ;
VAL_ 770 ADS_ParkOutDir_PerpFwd_302h 0 "不可用" 1 "可用" ;
VAL_ 770 ADS_ParkOutDir_PerpLeFwd_302h 0 "不可用" 1 "可用" ;
VAL_ 770 ADS_ParkOutDir_PerpRiFwd_302h 0 "不可用" 1 "可用" ;
VAL_ 770 ADS_ParkOutDir_PerpLeBack_302h 0 "不可用" 1 "可用" ;
VAL_ 770 ADS_ParkOutDir_PerpRiBack_302h 0 "不可用" 1 "可用" ;
VAL_ 770 ADS_ParkOutDir_PerpBack_302h 0 "不可用" 1 "可用" ;
VAL_ 770 APA_RPAFctUnavlMsg_1_302h 0 "none" 1 "happened 出现该原因" ;
VAL_ 770 APA_RPAFctUnavlMsg_2_302h 0 "none" 1 "happened 出现该原因" ;
VAL_ 770 APA_RPAFctUnavlMsg_3_302h 0 "none" 1 "happened 出现该原因" ;
VAL_ 770 APA_RPAFctUnavlMsg_4_302h 0 "none" 1 "happened 出现该原因" ;
VAL_ 770 APA_RPAFctUnavlMsg_5_302h 0 "none" 1 "happened 出现该原因" ;
VAL_ 770 APA_RPAFctUnavlMsg_6_302h 0 "none" 1 "happened 出现该原因" ;
VAL_ 770 APA_RPAFctUnavlMsg_7_302h 0 "none" 1 "happened 出现该原因" ;
VAL_ 770 APA_RPAFctUnavlMsg_8_302h 0 "none" 1 "happened 出现该原因" ;
VAL_ 770 APA_RPAFctUnavlMsg_9_302h 0 "none" 1 "happened 出现该原因" ;
VAL_ 770 APA_RPAFctUnavlMsg_10_302h 0 "none" 1 "happened 出现该原因" ;
VAL_ 770 APA_RPAFctUnavlMsg_11_302h 0 "none" 1 "happened 出现该原因" ;
VAL_ 770 APA_RPAFctUnavlMsg_12_302h 0 "none" 1 "happened 出现该原因" ;
VAL_ 770 APA_RPAFctUnavlMsg_13_302h 0 "none" 1 "happened 出现该原因" ;
VAL_ 770 APA_RPAFctUnavlMsg_14_302h 0 "none" 1 "happened 出现该原因" ;
VAL_ 770 APA_RPAFctUnavlMsg_15_302h 0 "none" 1 "happened 出现该原因" ;
VAL_ 770 APA_RPAFctUnavlMsg_16_302h 0 "none" 1 "happened 出现该原因" ;
VAL_ 770 APA_RPAFctUnavlMsg_17_302h 0 "none" 1 "happened 出现该原因" ;
VAL_ 770 APA_RPAFctUnavlMsg_18_302h 0 "none" 1 "happened 出现该原因" ;
VAL_ 770 APA_RPAFctUnavlMsg_19_302h 0 "none" 1 "happened 出现该原因" ;
VAL_ 770 APA_RPAFctUnavlMsg_20_302h 0 "none" 1 "happened 出现该原因" ;
VAL_ 770 APA_RPAFctUnavlMsg_21_302h 0 "none" 1 "happened 出现该原因" ;
VAL_ 770 APA_RPAFctUnavlMsg_22_302h 0 "none" 1 "happened 出现该原因" ;
VAL_ 770 APA_RPAFctUnavlMsg_23_302h 0 "none" 1 "happened 出现该原因" ;
VAL_ 770 APA_RPAFctUnavlMsg_24_302h 0 "none" 1 "happened 出现该原因" ;
VAL_ 770 APA_RPAFctUnavlMsg_25_302h 0 "none" 1 "happened 出现该原因" ;
VAL_ 770 APA_RPACnclMsg_1_302h 0 "none" 1 "happened 出现该原因" ;
VAL_ 770 APA_RPACnclMsg_2_302h 0 "none" 1 "happened 出现该原因" ;
VAL_ 770 APA_RPACnclMsg_3 0 "none" 1 "happened 出现该原因" ;
VAL_ 770 APA_RPACnclMsg_4_302h 0 "none" 1 "happened 出现该原因" ;
VAL_ 770 APA_RPACnclMsg_5_302h 0 "none" 1 "happened 出现该原因" ;
VAL_ 770 APA_RPACnclMsg_6_302h 0 "none" 1 "happened 出现该原因" ;
VAL_ 770 APA_RPACnclMsg_7_302h 0 "none" 1 "happened 出现该原因" ;
VAL_ 770 APA_RPACnclMsg_8_302h 0 "none" 1 "happened 出现该原因" ;
VAL_ 770 APA_RPACnclMsg_9_302h 0 "none" 1 "happened 出现该原因" ;
VAL_ 770 APA_RPACnclMsg_10_302h 0 "none" 1 "happened 出现该原因" ;
VAL_ 770 APA_RPACnclMsg_11_302h 0 "none" 1 "happened 出现该原因" ;
VAL_ 770 APA_RPACnclMsg_12_302h 0 "none" 1 "happened 出现该原因" ;
VAL_ 770 APA_RPACnclMsg_13_302h 0 "none" 1 "happened 出现该原因" ;
VAL_ 770 APA_RPACnclMsg_14_302h 0 "none" 1 "happened 出现该原因" ;
VAL_ 770 APA_RPACnclMsg_15_302h 0 "none" 1 "happened 出现该原因" ;
VAL_ 770 APA_RPACnclMsg_16_302h 0 "none" 1 "happened 出现该原因" ;
VAL_ 770 APA_RPACnclMsg_17_302h 0 "none" 1 "happened 出现该原因" ;
VAL_ 770 APA_RPACnclMsg_18_302h 0 "none" 1 "happened 出现该原因" ;
VAL_ 770 APA_RPACnclMsg_19_302h 0 "none" 1 "happened 出现该原因" ;
VAL_ 770 APA_RPACnclMsg_20_302h 0 "none" 1 "happened 出现该原因" ;
VAL_ 770 APA_RPAPauseMsg_1_302h 0 "none" 1 "happened 出现该原因" ;
VAL_ 770 APA_RPAPauseMsg_2_302h 0 "none" 1 "happened 出现该原因" ;
VAL_ 770 APA_RPAPauseMsg_3_302h 0 "none" 1 "happened 出现该原因" ;
VAL_ 770 APA_RPAPauseMsg_4_302h 0 "none" 1 "happened 出现该原因" ;
VAL_ 770 APA_RPAPauseMsg_5_302h 0 "none" 1 "happened 出现该原因" ;
VAL_ 770 APA_RPAPauseMsg_6_302h 0 "none" 1 "happened 出现该原因" ;
VAL_ 770 APA_RPAPauseMsg_7_302h 0 "none" 1 "happened 出现该原因" ;
VAL_ 770 APA_RPAPauseMsg_8_302h 0 "none" 1 "happened 出现该原因" ;
VAL_ 770 APA_RPAPauseMsg_9_302h 0 "none" 1 "happened 出现该原因" ;
VAL_ 770 APA_RPAPauseMsg_10_302h 0 "none" 1 "happened 出现该原因" ;
VAL_ 770 ADS_MnvrOrintChng1_302h 0 "None" 1 "Parallel" 2 "Cross" 3 "斜列" ;
VAL_ 770 ADS_MnvrOrintChng2_302h 0 "None" 1 "Parallel" 2 "Cross" 3 "斜列" ;
VAL_ 770 ADS_TarParkSt_Posn1_302h 0 "None" 1 "Invalid" 2 "Valid" 3 "Selectable" 4 "Selected" 5 "Reserved" 6 "Reserved" 7 "Reserved" ;
VAL_ 770 ADS_ParkChkSrc_Posn1_302h 0 "None" 1 "camera" 2 "lidar" 3 "mixed" 4 "Reserved" 5 "Reserved" 6 "Reserved" 7 "Reserved" ;
VAL_ 770 ADS_TarParkSt_Posn2_302h 0 "None" 1 "Invalid" 2 "Valid" 3 "Selectable" 4 "Selected" 5 "Reserved" 6 "Reserved" 7 "Reserved" ;
VAL_ 770 ADS_ParkChkSrc_Posn2_302h 0 "None" 1 "camera" 2 "lidar" 3 "mixed" 4 "Reserved" 5 "Reserved" 6 "Reserved" 7 "Reserved" ;
VAL_ 514 ADS_AdsFault_202h 0 "no request" 1 "无故障" 2 "有故障" 3 "reserved" 7 "Invalid" ;
VAL_ 514 ADS_NicaReminderLEDVisual_202h 0 "no request" 1 "turn on" 2 "turn off" 3 "reserved" 4 "reserved" 5 "reserved" 6 "reserved" 7 "Invalid" ;
VAL_ 514 ADS_NicaReminderAcoustic_202h 0 "no request" 1 "acoustic" 2 "no acoustic" 3 "torL1_acoustic" 4 "aeb_acoustic" 5 "reserved" 6 "reserved" 7 "Invalid" ;
VAL_ 514 ADS_TakeoverID_202h 0 "no request作为默认值" ;
VAL_ 514 ADS_TakeoverLevel_202h 0 "no request" 1 "Level 1" 2 "Level 2" 3 "Level 3" 4 "Level 4" 7 "Invalid" ;
VAL_ 514 ADS_TakeoverType_202h 0 "no request" 1 "大红手" 2 "松开加速踏板" 3 "制动踏板" 4 "MRM大红手" 5 "大黄手" 15 "Invalid" ;
VAL_ 514 ADS_TORIDCorrespErrorID_202h 0 "no request作为默认值" ;
VAL_ 1041 ADS_RadarWarning0AcLvl_411h 0 "no request" 1 "Level 1" 2 "Level 2" 3 "Level 3" 4 "Level 4" 5 "Level 5" 7 "Invalid" ;
VAL_ 1041 ADS_RadarWarning1AcLvl_411h 0 "no request" 1 "Level 1" 2 "Level 2" 3 "Level 3" 4 "Level 4" 5 "Level 5" 7 "Invalid" ;
VAL_ 1041 ADS_RadarWarning2AcLvl_411h 0 "no request" 1 "Level 1" 2 "Level 2" 3 "Level 3" 4 "Level 4" 5 "Level 5" 7 "Invalid" ;
VAL_ 1041 ADS_RadarWarning3AcLvl_411h 0 "no request" 1 "Level 1" 2 "Level 2" 3 "Level 3" 4 "Level 4" 5 "Level 5" 7 "Invalid" ;
VAL_ 1041 ADS_RadarWarning4AcLvl_411h 0 "no request" 1 "Level 1" 2 "Level 2" 3 "Level 3" 4 "Level 4" 5 "Level 5" 7 "Invalid" ;
VAL_ 1041 ADS_RadarWarning5AcLvl_411h 0 "no request" 1 "Level 1" 2 "Level 2" 3 "Level 3" 4 "Level 4" 5 "Level 5" 7 "Invalid" ;
VAL_ 1041 ADS_RadarWarning6AcLvl_411h 0 "no request" 1 "Level 1" 2 "Level 2" 3 "Level 3" 4 "Level 4" 5 "Level 5" 7 "Invalid" ;
VAL_ 1041 ADS_RadarWarning7AcLvl_411h 0 "no request" 1 "Level 1" 2 "Level 2" 3 "Level 3" 4 "Level 4" 5 "Level 5" 7 "Invalid" ;
VAL_ 1041 ADS_RadarWarning8AcLvl_411h 0 "no request" 1 "Level 1" 2 "Level 2" 3 "Level 3" 4 "Level 4" 5 "Level 5" 7 "Invalid" ;
VAL_ 1041 ADS_RadarWarning9AcLvl_411h 0 "no request" 1 "Level 1" 2 "Level 2" 3 "Level 3" 4 "Level 4" 5 "Level 5" 7 "Invalid" ;
VAL_ 1041 ADS_RadarWarning10AcLvl_411h 0 "no request" 1 "Level 1" 2 "Level 2" 3 "Level 3" 4 "Level 4" 5 "Level 5" 7 "Invalid" ;
VAL_ 1041 ADS_RadarWarning11AcLvl_411h 0 "no request" 1 "Level 1" 2 "Level 2" 3 "Level 3" 4 "Level 4" 5 "Level 5" 7 "Invalid" ;
VAL_ 1041 ADS_RadarWarning12AcLvl_411h 0 "no request" 1 "Level 1" 2 "Level 2" 3 "Level 3" 4 "Level 4" 5 "Level 5" 7 "Invalid" ;
VAL_ 1041 ADS_RadarWarning13AcLvl_411h 0 "no request" 1 "Level 1" 2 "Level 2" 3 "Level 3" 4 "Level 4" 5 "Level 5" 7 "Invalid" ;
VAL_ 1041 ADS_RadarWarning14AcLvl_411h 0 "no request" 1 "Level 1" 2 "Level 2" 3 "Level 3" 4 "Level 4" 5 "Level 5" 7 "Invalid" ;
VAL_ 1041 ADS_RadarWarning15AcLvl_411h 0 "no request" 1 "Level 1" 2 "Level 2" 3 "Level 3" 4 "Level 4" 5 "Level 5" 7 "Invalid" ;
VAL_ 1041 ADC_FuncReq_SentryModWarn_411h 0 "OFF;" 1 "哨兵模式唤醒" ;
VAL_ 1041 ADC_FuncReq_SentryModDetec_411h 0 "OFF;" 1 "哨兵模式维持" ;
VAL_ 1041 ADC_MdcSentryAlarmMod_411h 0 "无告警" 1 "警报" ;
VAL_ 769 ADS_AccFunctionStatus_301h 0 "No request" 1 "ACC_OFF" 2 "ACC_STANDBY" 3 "ACC_OVERRIDE" 4 "ACC_ACTIVE" 5 "ACC_STANDSTILL" 15 "Invalid" ;
VAL_ 769 ADS_LccNcaFunctionStatus_301h 0 "no request" 1 "OFF" 2 "LCC_STANDBY" 3 "LCC_LATERAL_OVERRIDE" 4 "LCC_LONGITUDINAL_OVERRIDE" 5 "LCC_LAT_LONG_OVERRIDE" 6 "LCC_ACTIVE" 7 "NCA_STANDBY" 8 "NCA_LATERAL_OVERRIDE" 9 "NCA_LONGITUDINAL_OVERRIDE" 10 "NCA_LAT_LONG_OVERRIDE" 11 "NCA_ACTIVE" 63 "Invalid" ;
VAL_ 769 ADS_AdsFucntionNotActive_301h 0 "no request" 1 "OFF" 2 "ACC" 3 "LCC" 4 "NCA" 5 "AVP" 15 "Invalid" ;
VAL_ 769 ADS_AvpFunctionStatus_301h 0 "no request" 1 "AVP_STATE_OFF" 2 "AVP_STATE_STANDBY" 3 "AVP_STATE_OVERRIDE" 4 "AVP_STATE_ACTIVE" 31 "invalid" ;
VAL_ 769 ADS_SpeedAutoFollow_301h 0 "no request" 1 "OFF" 2 "Active" 7 "Invalid" ;
VAL_ 769 ADS_OneTouchSpeedAdjustment_301h 0 "no request" 1 "Speed+" 2 "Speed-" 7 "Invalid" ;
VAL_ 769 ADS_CalibState_301h 0 "no request" 1 "off" 2 "on" 3 "reserved" 4 "reserved" 5 "reserved" 6 "reserved" 7 "Invalid" ;
VAL_ 769 ADS_HODReminder_301h 0 "no request" 1 "OFF" 2 "warning_level 1" 3 "warning_level 2" 4 "warning_level 3" 5 "warning_level 4" 6 "reserved" 7 "Invalid" ;
VAL_ 769 ADS_DMSReminder_301h 0 "no request" 1 "OFF" 2 "Distraction_warning_level 1" 3 "Fatigue_warning_level 1" 4 "Distraction_warning_level 2" 5 "Fatigue_warning_level 2" 6 "Distraction_warning_level 3" 7 "Fatigue_warning_level 3" 8 "Distraction_tellphone_call" 15 "Invalid" ;
VAL_ 769 ADS_FcwWaning_301h 0 "no request" 1 "Off" 2 "Standby" 3 "Active_level1" 4 "Active_level2" 5 "Nolicense" 7 "invalid" ;
VAL_ 769 ADS_FcwFault_301h 0 "no request" 1 "no fault" 2 "fault" 3 "invalid" ;
VAL_ 769 ADS_AebWaning_301h 0 "no request" 1 "Off" 2 "Active" 3 "IBA" 4 "Hold" 5 "Inactive (standby)" 6 "Nolicense" 7 "invalid" ;
VAL_ 769 ADS_AebFault_301h 0 "no request" 1 "no fault" 2 "fault" 3 "invalid" ;
VAL_ 769 ADS_AebObjType_301h 0 "no request" 1 "NONE" 2 "CARS" 3 "CYCLIST" 4 "Pedestrian" 5 "Others（通用障碍物）" 7 "invalid" ;
VAL_ 769 ADS_RaebWarning_301h 0 "no request" 1 "Off" 2 "Active" 3 "Hold" 4 "Inactive (standby)" 5 "Nolicense" 6 "Reserved" 7 "invalid" ;
VAL_ 769 ADS_RaebFault_301h 0 "no request" 1 "no fault" 2 "fault" 3 "invalid" ;
VAL_ 769 ADS_RcwWarning_301h 0 "no request" 1 "Off" 2 "Standby" 3 "Active_level1" 4 "Active_level2" 5 "Nolicense" 7 "invalid" ;
VAL_ 769 ADS_RcwFault_301h 0 "no request" 1 "no fault" 2 "fault" 3 "invalid" ;
VAL_ 769 ADS_FctaLeftWarning_301h 0 "no request" 1 "Off" 2 "Standby" 3 "Active_level1_Left" 4 "Active_level2_Left" 5 "Nolicense" 7 "invalid" ;
VAL_ 769 ADS_FctaRightWarning_301h 0 "no request" 1 "Off" 2 "Standby" 3 "Active_level1_Right" 4 "Active_level2_Right" 5 "Nolicense" 7 "invalid" ;
VAL_ 769 ADS_FctbLeftWarning_301h 0 "no request" 1 "Off" 2 "Active_Left" 3 "IBA" 4 "Hold" 5 "inactive (standby)" 6 "Nolicense" 7 "invalid" ;
VAL_ 769 ADS_FctbRightWarning_301h 0 "no request" 1 "Off" 2 "Active_Right" 3 "IBA" 4 "Hold" 5 "inactive (standby)" 6 "Nolicense" 7 "invalid" ;
VAL_ 769 ADS_RctaLeftWarning_301h 0 "no request" 1 "Off" 2 "Standby" 3 "Warning_Left" 4 "Warning_level2_Left" 5 "Nolicense" 6 "Reserved" 7 "invalid" ;
VAL_ 769 ADS_RctaRightWarning_301h 0 "no request" 1 "Off" 2 "Standby" 3 "Warning_Right" 4 "Warning_level2_Right" 5 "Nolicense" 6 "Reserved" 7 "invalid" ;
VAL_ 769 ADS_RctaFault_301h 0 "no request" 1 "no fault" 2 "fault" 3 "invalid" ;
VAL_ 769 ADS_RctbLeftWarning_301h 0 "no request" 1 "Off" 2 "Active_Left" 3 "Hold" 4 "Inactive (Standby)" 5 "Nolicense" 7 "invalid" ;
VAL_ 769 ADS_RctbRightWarning_301h 0 "no request" 1 "Off" 2 "Active_Right" 3 "Hold" 4 "Inactive (Standby)" 5 "Nolicense" 7 "invalid" ;
VAL_ 769 ADS_LdwWarning_301h 0 "no request" 1 "Off" 2 "Standby" 3 "Ready" 4 "Active_Left" 5 "Active_Right" 6 "Switchoff" 7 "invalid" ;
VAL_ 769 ADS_LdwFault_301h 0 "no request" 1 "no fault" 2 "fault" 3 "invalid" ;
VAL_ 769 ADS_LKAWarning_301h 0 "no request" 1 "Off" 2 "Standby" 3 "Ready" 4 "Active_Left" 5 "Active_Right" 6 "Switchoff" 7 "invalid" ;
VAL_ 769 ADS_LkaFault_301h 0 "no request" 1 "no fault" 2 "fault" 3 "invalid" ;
VAL_ 769 ADS_LeftMirrWarningCmd_301h 0 "no request" 1 "no warning" 2 "level 1" 3 "level 2" 4 "reserved" 7 "Invalid" ;
VAL_ 769 ADS_RightMirrWarningCmd_301h 0 "no request" 1 "no warning" 2 "level 1" 3 "level 2" 4 "reserved" 7 "Invalid" ;
VAL_ 769 ADS_BsdFault_301h 0 "no request" 1 "no fault" 2 "fault" 3 "invalid" ;
VAL_ 769 ADS_LeFrntDoorWarningCmd_301h 0 "no request" 1 "no warning" 2 "level 1" 3 "level 2" 4 "reserved" 7 "Invalid" ;
VAL_ 769 ADS_LeReDoorWarningCmd_301h 0 "no request" 1 "no warning" 2 "level 1" 3 "level 2" 4 "reserved" 7 "Invalid" ;
VAL_ 769 ADS_RiFrntDoorWarningCmd_301h 0 "no request" 1 "no warning" 2 "level 1" 3 "level 2" 4 "reserved" 7 "Invalid" ;
VAL_ 769 ADS_RiReDoorWarningCmd_301h 0 "no request" 1 "no warning" 2 "level 1" 3 "level 2" 4 "reserved" 7 "Invalid" ;
VAL_ 769 ADS_DowFault_301h 0 "no request" 1 "no fault" 2 "fault" 3 "invalid" ;
VAL_ 769 ADS_SpeedLimitWarning_301h 0 "no request" 1 "no_warning" 2 "warning_Relative" 3 "warning_Absolute" 4 "reserved_1" 5 "reserved_2" 6 "reserved_3" 7 "Invalid" ;
VAL_ 769 ADS_TsrFault_301h 0 "no request" 1 "no fault" 2 "fault" 3 "invalid" ;
VAL_ 769 ADS_TlaFault_301h 0 "no request" 1 "no fault" 2 "fault" 3 "invalid" ;
VAL_ 769 ADS_ElkaFault_301h 0 "no request" 1 "no fault" 2 "fault" 3 "invalid" ;
VAL_ 769 ADS_TlaWarning_301h 0 "no request" 1 "No Warning" 2 "Red Light Warning" 3 "Start Warning" 4 "reserved_1" 5 "reserved_2" 6 "reserved_3" 7 "Invalid" ;
VAL_ 769 ADS_ElkaWarning_301h 0 "no request" 1 "Off" 2 "Standby" 3 "Ready" 4 "Active_Left" 5 "Active_Right" 6 "Switchoff" 7 "invalid" ;
VAL_ 1042 ADS_BrkBeamReq_412h 0 "无请求" 1 "ON" 2 "Resvered" 3 "Resvered" ;
VAL_ 1042 ADS_AutoLightSwCtrl_412h 0 "无请求" 1 "POSITION_LIGHT" 2 "LOW_BEAM" 3 "AUTO_MODE" ;
VAL_ 1042 ADS_LeFrntDowWarning_412h 0 "无请求" 1 "常亮" 2 "闪烁" 3 "reserved" ;
VAL_ 1042 ADS_RiFrntDowWarning_412h 0 "无请求" 1 "常亮" 2 "闪烁" 3 "reserved" ;
VAL_ 1042 ADS_LeReDowWarning_412h 0 "无请求" 1 "常亮" 2 "闪烁" 3 "reserved" ;
VAL_ 1042 ADS_RiReDowWarning_412h 0 "无请求" 1 "常亮" 2 "闪烁" 3 "reserved" ;
VAL_ 1042 ADS_LeftMirrWarningCmd_412h 0 "无请求" 1 "Level（常亮）" 2 "Level (闪烁）" 3 "resversed" ;
VAL_ 1042 ADS_RightMirrWarningCmd_412h 0 "无请求" 1 "Level（常亮）" 2 "Level (闪烁）" 3 "resversed" ;
VAL_ 1042 ADS_ReMirrReq_412h 0 "Not Request" 1 "展开" 2 "折叠" 3 "Not used" ;
VAL_ 1042 ADS_DoorLockReq_412h 0 "Not Request 无请求" 1 "UnLock 解锁请求" 2 "Lock 上锁请求" 3 "reserved" ;
VAL_ 1042 ADS_SBeltControl_412h 0 "No Request" 1 "Shake" 2 "Tied level 1" 3 "Tied level 2 （预留）" 4 "reserved" 5 "reserved" 6 "reserved" 7 "reserved" ;
VAL_ 1042 ADS_WshrReq_412h 0 "无请求" 1 "有请求" ;
VAL_ 1042 ADS_SeatShakeControl_412h 0 "No Request" 1 "Shake" 2 "reserved" 3 "reserved" ;
VAL_ 1042 ADS_FrtWindshildHeatReq_412h 0 "无请求" 1 "有请求" 2 "reserved" 3 "reserved" ;
VAL_ 1042 ADS_HornReq_412h 0 "无请求" 1 "哨兵模式喇叭请求" 2 "巡航功能喇叭请求" 3 "resevered" ;
VAL_ 1042 ADS_LeFmtWinCtrl_412h 0 "无请求" 1 "关闭" 2 "打开" 3 "resevered" ;
VAL_ 1042 ADS_RiFmtWinCtrl_412h 0 "无请求" 1 "关闭" 2 "打开" 3 "resevered" ;
VAL_ 1042 ADS_LeReWinCtrl_412h 0 "无请求" 1 "关闭" 2 "打开" 3 "resevered" ;
VAL_ 1042 ADS_RiReWinCtrl_412h 0 "无请求" 1 "关闭" 2 "打开" 3 "resevered" ;
VAL_ 1042 ADS_TopWinCtrl_412h 0 "无请求" 1 "关闭" 2 "打开" 3 "resevered" ;
VAL_ 1042 ADS_FrontWiperReq_412h 0 "无请求" 1 "有请求" ;
VAL_ 1042 ADS_ChargingPortCmd_412h 0 "no request" 1 "OFF" 2 "ON" 3 "Reversed" ;
VAL_ 1042 ADAS_FctSts_412h 0 "Off" 1 "On" ;
VAL_ 1042 ADS_MdcCrtSts_412h 0 "DeepSleep深度睡眠状态" 1 "LightSleep浅睡眠状态" 2 "Active激活状态" 3 "PartialActive半激活状态" 4 "Reserved" 5 "Reserved" 6 "Reserved" 7 "Invalid" ;
VAL_ 1042 ADS_HVCtrlReq_412h 0 "No Request" 1 "Request" ;
VAL_ 1042 ADS_ThmPostRun_412h 0 "No Request" 1 "Request" ;
VAL_ 1042 ADS_FlowReq_412h 0 "0.0L/min" 1 "0.25L/min" 2 "0.5L/min" 3 "0.75L/min" 4 "1.0L/min" 5 "1.25L/min" 6 "1.5L/min" 7 "1.75L/min" 8 "2.00L/min" 9 "2.25L/min" 10 "2.5L/min" 11 "2.75L/min" 12 "3.0L/min" 13 "3.25L/min" ;
VAL_ 1042 ADS_PwrOnOffReq_412h 0 "no request" 1 "Power on 上电（从OFF至整车Ready状态）" 2 "Power off 下电（KL15 OFF)" 3 "上Ready（等同于过动力防盗）" 4 "下Ready（等同于退动力防盗，需维持高压）" 5 "reserved" 6 "reserved" 7 "reserved" ;
VAL_ 1042 ADS_hmaOnOffSts_412h 0 "Initial" 1 "OFF" 2 "ON" 3 "INVALID" ;
VAL_ 1042 ADS_HMAStatus_412h 0 "Off" 1 "Standby" 2 "Active" 3 "Failure" ;
VAL_ 1042 ADS_HiBeamReq_412h 0 "No Request" 1 "Request" ;
VAL_ 290 EPSFailSts 0 "Not present" 1 "Fail present" 2 "Reserved" 3 "Reserved" ;
VAL_ 290 EPSSteeringAngleCalibrationSts 0 "Calibration is fine" 1 "No calibration or no initialization" ;
VAL_ 290 EPS_EOTLearning_Sts 0 "Learnt" 1 "Not Learnt" ;
VAL_ 1046 LBMS_LoWSocFlt 0 "No Remind" 1 "Low Power Remind" 2 "Level 2 fault" 3 "Level 3 fault" 4 "Reserved" 5 "Reserved" 6 "Reserved" 7 "Reserved" 8 "Reserved" 9 "Reserved" 10 "Reserved" 11 "Reserved" 12 "Reserved" 13 "Reserved" 14 "Reserved" 15 "Reserved" ;
VAL_ 1046 LBMS_ThermRunawayFlt 0 "No Active" 1 "Active" ;
VAL_ 1046 LBMS_SysFlt 0 "No Active" 1 "Active" ;
VAL_ 1046 LBMS_LowPowerRemind 0 "No Remind" 1 "Low Power Remind" 2 "Level 2 fault" 3 "Level 3 fault" 4 "Reserved" 5 "Reserved" 6 "Reserved" 7 "Reserved" 8 "Reserved" 9 "Reserved" 10 "Reserved" 11 "Reserved" 12 "Reserved" 13 "Reserved" 14 "Reserved" 15 "Reserved" ;
VAL_ 1046 LBMS_EndLifeFlt 0 "No Active" 1 "Active" ;
SIG_GROUP_ 1291 BMS_2_G_0x50B_E2E_P01_1 1 : Fusa_50B_1 BMS_2_G_CRC BMS_2_G_RollgCntr BMS_2_G_Resd BMS_TBOXInsulation_R BMS_TBOXErrorNumber BMS_TBOXHvBattMaxT BMS_TBOXHvBattMinT BMS_SOCLight;
SIG_GROUP_ 1180 New_Signal_Group_49C 1 : New_Signal_49C_1 New_Signal_49C_2 New_Signal_49C_3 New_Signal_49C_4 New_Signal_49C_5 New_Signal_49C_6 New_Signal_49C_7 New_Signal_49C_8 New_Signal_49C_9 ACU_1_PsngrSeatOccupiedSts ACU_1_SecRowRBeltWarning ACU_1_SecRowMBeltWarning ACU_1_SecRowLBeltWarning ACU_1_PsngrSeatBeltWarning ACU_1_ThdRowRBeltWarning ACU_1_ThdRowLBeltWarning ACU_1_AirBagFailSts ABM_1_Rollover_Status ACU_1_CRC1 ACU_1_RollgCntr1;
SIG_GROUP_ 514 New_Signal_Group202_1 1 : Fusa_202_1 ADS_TakeoverExtended8bit_202h ADS_TakeoverExtended16bit_202h ADS_RollgCntr2_202h ADS_Resd2_202h ADS_CRC2_202h;
SIG_GROUP_ 514 New_Signal_Group_202 1 : ADS_TORIDCorrespErrorID_202h ADS_TakeoverType_202h ADS_TakeoverLevel_202h ADS_TakeoverID_202h ADS_NicaReminderAcoustic_202h ADS_NicaReminderLEDVisual_202h ADS_AdsFault_202h ADS_Resd1_202h ADS_RollgCntr1_202h ADS_CRC1_202h;
SIG_GROUP_ 1042 New_Signal_Group_412 1 : New_Signal_412_1 ADS_MdcCrtSts_412h ADAS_FctSts_412h ADS_ChargingPortCmd_412h ADS_FrontWiperReq_412h ADS_TopWinCtrl_412h ADS_RiReWinCtrl_412h ADS_LeReWinCtrl_412h ADS_RiFmtWinCtrl_412h ADS_LeFmtWinCtrl_412h ADS_HornReq_412h ADS_FrtWindshildHeatReq_412h ADS_SeatShakeControl_412h ADS_WshrReq_412h ADS_SBeltControl_412h ADS_DoorLockReq_412h ADS_ReMirrReq_412h ADS_RightMirrWarningCmd_412h ADS_LeftMirrWarningCmd_412h ADS_RiReDowWarning_412h ADS_LeReDowWarning_412h ADS_RiFrntDowWarning_412h ADS_LeFrntDowWarning_412h ADS_AutoLightSwCtrl_412h ADS_BrkBeamReq_412h ADS_Resd1_412h ADS_RollgCntr1_412h ADS_CRC1_412h;
SIG_GROUP_ 290 EPS_1_0x122_E2E_P01_1 1 : Fusa_122_1 Fusa_122_2 Fusa_122_3 EPS_1_CRC EPS_1_RollgCntr EPSFailSts EPSSteeringAngleCalibrationSts EPS_EOTLearning_Sts;
